VERSION ""

NS_ :

BS_:

BU_: ARM APIM_CDC APIM_CISM APIM ESPM DSP APIM_CIM FCIMB RACM_RCIM HUD_ADV WCM TRM_ITRM ACM GWM _delete IPC GENERIC TSTR

BO_ 811 APIM_Data: 8 APIM
 SG_ ExtLghtDsply_D_Stat : 7|3@0+ (1,0) [0|7] "SED"  GWM
 SG_ LongTermReset_B_RqMnu : 17|1@0+ (1,0) [0|1] "SED"  GWM
 SG_ SpeedoMajorUnit_D_Confg : 59|2@0+ (1,0) [0|3] "SED"  GWM
 SG_ ScMnSoc_Pc_RqMnu : 55|7@0+ (1,0) [0|125] "percent"  GWM
 SG_ ScEnbl_D_RqMnu : 57|2@0+ (1,0) [0|3] "SED"  GWM
 SG_ OnePdlDrvButtn_B_Stat : 48|1@0+ (1,0) [0|1] "SED"  GWM
 SG_ OnePdlDrvButtn_B_Falt : 16|1@0+ (1,0) [0|1] "SED"  GWM
 SG_ GoTEditMnte_T_RqMnu : 63|4@0+ (1,0) [0|15] "SED"  GWM
 SG_ GoTEditHr_T_RqMnu : 44|5@0+ (1,0) [0|29] "SED"  GWM
 SG_ ExtLghtRight_D_RqMnu : 11|3@0+ (1,0) [0|7] "SED"  GWM
 SG_ AutoLghtOvrrd_B_RqDrv : 8|1@0+ (1,0) [0|1] "SED"  GWM
 SG_ TrnkFrontRleas_No_RqMnu : 20|3@0+ (1,0) [0|7] "unitless"  GWM
 SG_ BecRleas_No_RqMnu : 23|3@0+ (1,0) [0|7] "unitless"  GWM
 SG_ ExtLghtRear_D_RqMnu : 14|3@0+ (1,0) [0|7] "SED"  GWM
 SG_ ExtLghtLeft_D_RqMnu : 1|3@0+ (1,0) [0|7] "SED"  GWM
 SG_ ExtLghtFront_D_RqMnu : 4|3@0+ (1,0) [0|7] "SED"  GWM
 SG_ DistToStopover_L_Actl : 31|16@0+ (0.1,0) [0|6553.4] "kilometer"  IPC,GWM
 SG_ StopoverType_D_Stat : 47|3@0+ (1,0) [0|7] "SED"  IPC,GWM

BO_ 543 TelTaleData: 8 IPC
 SG_ TeltalWarnData_No_Actl : 7|64@0+ (1,0) [0|1.84467E+019] "unitless"  APIM,APIM_CISM,GWM

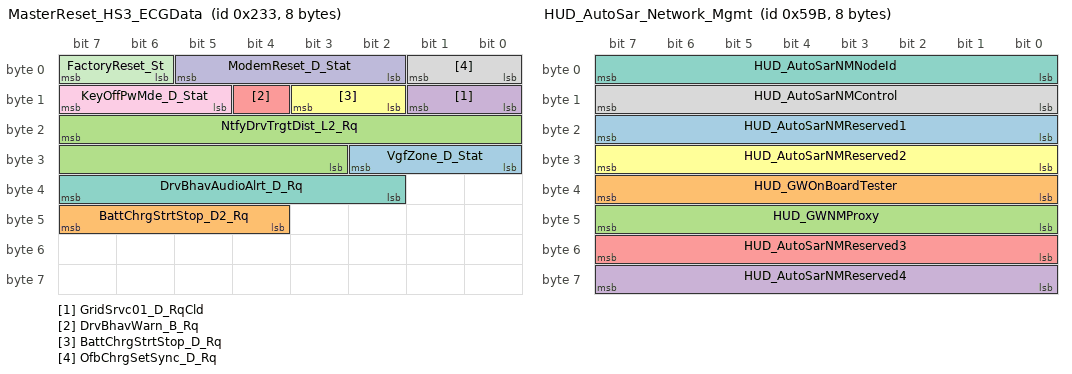
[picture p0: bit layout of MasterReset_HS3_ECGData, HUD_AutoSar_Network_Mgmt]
BO_ 563 MasterReset_HS3_ECGData: 8 GWM
 SG_ VgfZone_D_Stat : 26|3@0+ (1,0) [0|7] "SED"  IPC
 SG_ BattChrgStrtStop_D2_Rq : 47|4@0+ (1,0) [0|15] "SED" Vector__XXX
 SG_ NtfyDrvTrgtDist_L2_Rq : 23|13@0+ (0.1,0) [0|818.9] "Km" Vector__XXX
 SG_ GridSrvc01_D_RqCld : 9|2@0+ (1,0) [0|3] "SED"  APIM_CDC,APIM,APIM_CISM,APIM_CIM
 SG_ DrvBhavWarn_B_Rq : 12|1@0+ (1,0) [0|1] "SED"  APIM_CDC,APIM_CIM,IPC
 SG_ BattChrgStrtStop_D_Rq : 11|2@0+ (1,0) [0|3] "SED"  GENERIC
 SG_ DrvBhavAudioAlrt_D_Rq : 39|6@0+ (1,0) [0|63] "SED"  APIM_CDC,APIM,APIM_CISM,APIM_CIM
 SG_ OfbChrgSetSync_D_Rq : 1|2@0+ (1,0) [0|3] "SED"  APIM_CDC,APIM,APIM_CISM,APIM_CIM
 SG_ KeyOffPwMde_D_Stat : 15|3@0+ (1,0) [0|7] "SED"  APIM_CDC,APIM,APIM_CISM,APIM_CIM
 SG_ ModemReset_D_Stat : 5|4@0+ (1,0) [0|15] "SED"  APIM_CDC,APIM,APIM_CISM,APIM_CIM,ACM
 SG_ FactoryReset_St : 7|2@0+ (1,0) [0|3] "SED"  APIM_CDC,APIM,APIM_CISM,APIM_CIM,ACM

BO_ 587 PHONE_RDISP2_WORD_Rx: 8 HUD_ADV
 SG_ PHONE_RDISP2_WORD_Rx : 7|64@0+ (1,0) [0|1.84467440737096E+019] "unitless"  APIM_CDC,APIM,APIM_CISM,APIM_CIM,ACM

BO_ 579 PHONE_RDISP2_WORD_Tx: 8 ACM
 SG_ PHONE_RDISP2_WORD_Tx : 7|64@0+ (1,0) [0|1.84467440737096E+019] "unitless"  HUD_ADV

BO_ 585 NAV_RDISP2_WORD_Rx: 8 HUD_ADV
 SG_ NAV_RDISP2_WORD_Rx : 7|64@0+ (1,0) [0|1.84467440737096E+019] "unitless"  APIM_CDC,APIM,APIM_CISM,APIM_CIM

BO_ 586 CONMP_RDISP2_WORD_Rx: 8 HUD_ADV
 SG_ CONMP_RDISP2_WORD_Rx : 7|64@0+ (1,0) [0|1.84467440737096E+019] "unitless"  APIM_CDC,APIM,APIM_CISM,APIM_CIM

BO_ 578 CONMP_RDISP2_WORD_Tx: 8 APIM
 SG_ CONMP_RDISP2_WORD_Tx : 7|64@0+ (1,0) [0|1.84467440737096E+019] "unitless"  HUD_ADV

BO_ 577 NAV_RDISP2_WORD_Tx: 8 APIM
 SG_ NAV_RDISP2_WORD_Tx : 7|64@0+ (1,0) [0|1.84467440737096E+019] "unitless"  HUD_ADV

BO_ 978 ConvertibleTop_Slave_HS3: 8 GWM
 SG_ CnvtTopTWarn_B_Falt : 25|1@0+ (1,0) [0|1] "SED" Vector__XXX
 SG_ CnvtTopTOvr_B_Falt : 26|1@0+ (1,0) [0|1] "SED" Vector__XXX
 SG_ CnvtTopTDir_B_Falt : 27|1@0+ (1,0) [0|1] "SED" Vector__XXX
 SG_ CnvtTopStall_B_Falt : 28|1@0+ (1,0) [0|1] "SED" Vector__XXX
 SG_ CnvtTopSns_B_Falt : 29|1@0+ (1,0) [0|1] "SED" Vector__XXX
 SG_ CnvtTopRvrse_B_Stat : 30|1@0+ (1,0) [0|1] "SED" Vector__XXX
 SG_ CnvtTopRngOpen_B_Stat : 31|1@0+ (1,0) [0|1] "SED" Vector__XXX
 SG_ CnvtTopRngClose_B_Stat : 16|1@0+ (1,0) [0|1] "SED" Vector__XXX
 SG_ CnvtTopRestrc_B_Falt : 17|1@0+ (1,0) [0|1] "SED" Vector__XXX
 SG_ CnvtTopRdy_B_Stat : 18|1@0+ (1,0) [0|1] "SED" Vector__XXX
 SG_ CnvtTopPosSet_B_Stat : 19|1@0+ (1,0) [0|1] "SED" Vector__XXX
 SG_ CnvtTopPos_No_Actl : 39|16@0+ (1,0) [0|65535] "unitless" Vector__XXX
 SG_ CnvtTopPos_D_Stat : 23|4@0+ (1,0) [0|15] "SED"  APIM_CDC,APIM,APIM_CIM,APIM_CISM
 SG_ CnvtTopPos_B_Falt : 8|1@0+ (1,0) [0|1] "SED" Vector__XXX
 SG_ CnvtTopOut_B_Falt : 9|1@0+ (1,0) [0|1] "SED" Vector__XXX
 SG_ CnvtTopOpen_D_Stat : 11|2@0+ (1,0) [0|3] "SED" Vector__XXX
 SG_ CnvtTopOpen_B_Stat : 12|1@0+ (1,0) [0|1] "SED" Vector__XXX
 SG_ CnvtTopNom_B_Stat : 13|1@0+ (1,0) [0|1] "SED" Vector__XXX
 SG_ CnvtTopDir_B_Falt : 0|1@0+ (1,0) [0|1] "SED" Vector__XXX
 SG_ CnvtTopComplt_No_Cnt : 15|2@0+ (1,0) [0|3] "unitless" Vector__XXX
 SG_ CnvtTopComplt_D_Stat : 3|3@0+ (1,0) [0|7] "SED" Vector__XXX
 SG_ CnvtTopCnfm_B_Stat : 4|1@0+ (1,0) [0|1] "SED" Vector__XXX
 SG_ CnvtTopClose_D_Stat : 6|2@0+ (1,0) [0|3] "SED" Vector__XXX
 SG_ CnvtTopActv_B_Stat : 7|1@0+ (1,0) [0|1] "SED" Vector__XXX
 SG_ TonneuCapMde_D_Stat : 55|2@0+ (1,0) [0|3] "SED" Vector__XXX

BO_ 717 DSPAMP_RDISP_WORD_Rx: 8 APIM
 SG_ DSPAMP_RDISP_WORD_Rx : 7|64@0+ (1,0) [0|1.84467440737096E+019] "unitless"  DSP

BO_ 719 MyKeySrvr_Clnt_Word_Rx: 8 APIM
 SG_ MyKeySrvr_Clnt_Word_Rx : 7|64@0+ (1,0) [0|1.84467440737096E+019] "unitless"  IPC

BO_ 589 TRAFFIC_RDISP_WORD_Rx: 8 APIM
 SG_ TRAFFIC_RDISP_WORD_Rx : 7|64@0+ (1,0) [0|1.84467440737096E+019] "unitless"  GWM

BO_ 1146 TrailerInfo_ITRM: 8 TRM_ITRM
 SG_ TrlrAidSwtch_D_RqDrv : 35|2@0+ (1,0) [0|3] "SED"  GWM
 SG_ TrlrAidCtl_U_RqDrv : 31|12@0+ (0.00125,0) [0|5.11625] "volt"  GWM

BO_ 737 APIM_ECG_Word_Tx: 8 APIM
 SG_ APIM_ECG_Word_Tx : 7|64@0+ (1,0) [0|1.84467440737096E+019] "unitless"  IPC,GWM

BO_ 745 ECG_APIM_Word_Tx: 8 GWM
 SG_ ECG_APIM_Word_Tx : 7|64@0+ (1,0) [0|1.84467440737096E+019] "unitless"  APIM_CDC,APIM,APIM_CIM,APIM_CISM

BO_ 1195 TCU_RDISP2_WORD_Rx: 8 HUD_ADV
 SG_ TCU_RDISP2_WORD_Rx : 7|64@0+ (1,0) [0|1.84467440737096E+019] "unitless"  GWM

BO_ 1185 TCU_MC_WORD_Rx: 8 IPC
 SG_ TCU_MC_WORD_Rx : 7|64@0+ (1,0) [0|1.84467440737096E+019] "unitless"  GWM

BO_ 1435 HUD_AutoSar_Network_Mgmt: 8 HUD_ADV
 SG_ HUD_AutoSarNMReserved1 : 23|8@0+ (1,0) [0|255] "unitless"  GENERIC,IPC
 SG_ HUD_GWOnBoardTester : 39|8@0+ (1,0) [0|255] "unitless"  GENERIC,IPC,GWM
 SG_ HUD_GWNMProxy : 47|8@0+ (1,0) [0|255] "unitless"  GENERIC,IPC,GWM
 SG_ HUD_AutoSarNMReserved4 : 63|8@0+ (1,0) [0|255] "unitless"  GENERIC,IPC,GWM
 SG_ HUD_AutoSarNMReserved3 : 55|8@0+ (1,0) [0|255] "unitless"  GENERIC,IPC,GWM
 SG_ HUD_AutoSarNMReserved2 : 31|8@0+ (1,0) [0|255] "unitless"  GENERIC,IPC,GWM
 SG_ HUD_AutoSarNMNodeId : 7|8@0+ (1,0) [0|255] "unitless"  GENERIC,IPC,GWM
 SG_ HUD_AutoSarNMControl : 15|8@0+ (1,0) [0|255] "unitless"  GENERIC,IPC,GWM

BO_ 1109 eCall_Info: 8 APIM
 SG_ eCallConfirmation : 7|3@0+ (1,0) [0|7] "SED"  IPC,GWM

BO_ 1945 TesterPhysicalResTRM_ITRM: 8 TRM_ITRM
 SG_ TesterPhysicalResTRM_ITRM : 7|64@0+ (1,0) [0|1.84467E+019] "unitless"  TSTR

BO_ 1937 TesterPhysicalReqTRM_ITRM: 8 TSTR
 SG_ TesterPhysicalReqTRM_ITRM : 7|64@0+ (1,0) [0|1.84467E+019] "unitless"  TRM_ITRM

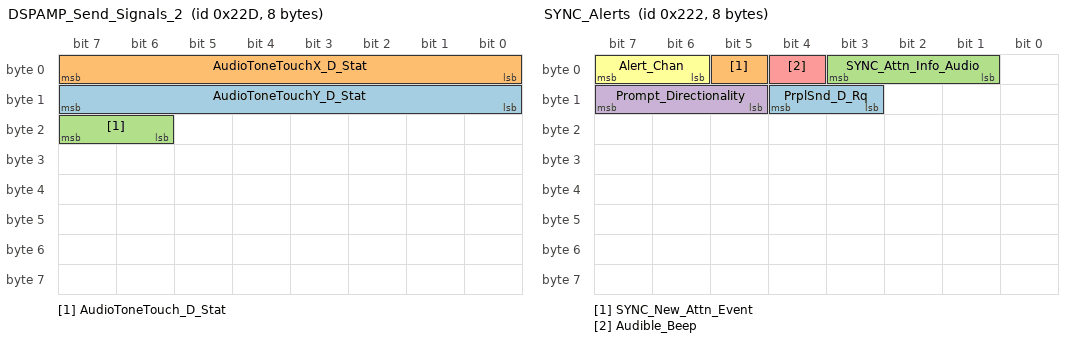
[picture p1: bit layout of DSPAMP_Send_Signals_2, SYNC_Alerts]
BO_ 557 DSPAMP_Send_Signals_2: 8 DSP
 SG_ AudioToneTouchY_D_Stat : 15|8@0+ (1,0) [0|255] "SED"  APIM_CDC,APIM,APIM_CISM,APIM_CIM
 SG_ AudioToneTouchX_D_Stat : 7|8@0+ (1,0) [0|255] "SED"  APIM_CDC,APIM,APIM_CISM,APIM_CIM
 SG_ AudioToneTouch_D_Stat : 23|2@0+ (1,0) [0|3] "SED"  APIM_CDC,APIM,APIM_CISM,APIM_CIM

BO_ 718 BEZEL_RDISP_WORD_Rx: 8 APIM
 SG_ BEZEL_RDISP_WORD_Rx : 7|64@0+ (1,0) [0|1.84467440737096E+019] "unitless"  GWM

BO_ 140 CruiseCtrl_StrgData2: 8 IPC
 SG_ DcacPwResetBttn_D_Stat : 36|2@0+ (1,0) [0|3] "SED"  GWM
 SG_ CcAslButtnIndxIncPress2 : 18|1@0+ (1,0) [0|1] "SED"  GWM
 SG_ SteWhlSwtchMde_D_Stat : 23|2@0+ (1,0) [0|3] "SED"  GWM
 SG_ CcAslButtnOffCnclPress2 : 17|1@0+ (1,0) [0|1] "SED"  GWM
 SG_ CcAslButtnIndxDecPress2 : 19|1@0+ (1,0) [0|1] "SED"  GWM
 SG_ CcAslButtnCnclResPress2 : 21|1@0+ (1,0) [0|1] "SED"  GWM
 SG_ CcAslButtnResIncPress3 : 29|1@0+ (1,0) [0|1] "SED"  GWM
 SG_ CcButtnOnPress3 : 37|1@0+ (1,0) [0|1] "SED"  GWM
 SG_ CcButtnOnOffPress3 : 38|1@0+ (1,0) [0|1] "SED"  GWM
 SG_ CcButtnOnOffCnclPress3 : 39|1@0+ (1,0) [0|1] "SED"  GWM
 SG_ CcButtnOffPress3 : 24|1@0+ (1,0) [0|1] "SED"  GWM
 SG_ CcAsllButtnResPress3 : 25|1@0+ (1,0) [0|1] "SED"  GWM
 SG_ CcAslButtnSetPress3 : 26|1@0+ (1,0) [0|1] "SED"  GWM
 SG_ CcAslButtnSetIncPress3 : 27|1@0+ (1,0) [0|1] "SED"  GWM
 SG_ CcAslButtnSetDecPress3 : 28|1@0+ (1,0) [0|1] "SED"  GWM
 SG_ CcAslButtnResDecPress3 : 30|1@0+ (1,0) [0|1] "SED"  GWM
 SG_ CcAslButtnOnPress3 : 31|1@0+ (1,0) [0|1] "SED"  GWM
 SG_ CcAslButtnOnOffCncl3 : 16|1@0+ (1,0) [0|1] "SED"  GWM
 SG_ CcAslButtnDeny_B_Actl3 : 20|1@0+ (1,0) [0|1] "SED"  GWM
 SG_ CcAslButtnCnclPress3 : 8|1@0+ (1,0) [0|1] "SED"  GWM
 SG_ AslButtnOnOffPress3 : 9|1@0+ (1,0) [0|1] "SED"  GWM
 SG_ AslButtnOnOffCnclPress2 : 10|1@0+ (1,0) [0|1] "SED"  GWM

BO_ 546 SYNC_Alerts: 8 APIM
 SG_ PrplSnd_D_Rq : 12|2@0+ (1,0) [0|3] "SED"  ACM
 SG_ SYNC_New_Attn_Event : 5|1@0+ (1,0) [0|1] "SED"  DSP,ACM
 SG_ SYNC_Attn_Info_Audio : 3|3@0+ (1,0) [0|7] "SED"  DSP,ACM
 SG_ Prompt_Directionality : 15|3@0+ (1,0) [0|7] "SED"  DSP,ACM
 SG_ Audible_Beep : 4|1@0+ (1,0) [0|1] "SED"  DSP,ACM
 SG_ Alert_Chan : 7|2@0+ (1,0) [0|3] "SED"  WCM,RACM_RCIM,DSP,ACM

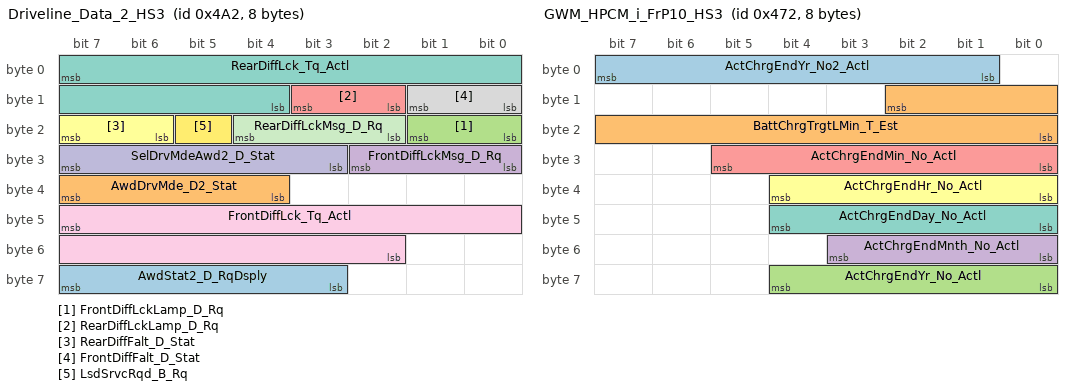
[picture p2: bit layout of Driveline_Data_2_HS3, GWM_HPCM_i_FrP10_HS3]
BO_ 1186 Driveline_Data_2_HS3: 8 GWM
 SG_ AwdStat2_D_RqDsply : 63|5@0+ (1,0) [0|31] "SED"  APIM_CDC,APIM_CIM,IPC
 SG_ AwdDrvMde_D2_Stat : 39|4@0+ (1,0) [0|15] "SED"  APIM_CDC,APIM_CIM,IPC
 SG_ FrontDiffLckLamp_D_Rq : 17|2@0+ (1,0) [0|3] "SED"  APIM_CDC,HUD_ADV,APIM,APIM_CIM,APIM_CISM,IPC
 SG_ FrontDiffLckMsg_D_Rq : 26|3@0+ (1,0) [0|7] "SED"  APIM_CDC,APIM_CIM,IPC
 SG_ RearDiffLckLamp_D_Rq : 11|2@0+ (1,0) [0|3] "SED"  APIM_CDC,HUD_ADV,APIM,APIM_CISM,APIM_CIM,ACM,IPC
 SG_ RearDiffFalt_D_Stat : 23|2@0+ (1,0) [0|3] "SED" Vector__XXX
 SG_ RearDiffLck_Tq_Actl : 7|12@0+ (1,0) [0|4093] "Nm" Vector__XXX
 SG_ FrontDiffFalt_D_Stat : 9|2@0+ (1,0) [0|3] "SED"  GENERIC
 SG_ FrontDiffLck_Tq_Actl : 47|14@0+ (1,0) [0|16381] "Nm"  GENERIC
 SG_ SelDrvMdeAwd2_D_Stat : 31|5@0+ (1,0) [0|31] "SED"  GENERIC
 SG_ RearDiffLckMsg_D_Rq : 20|3@0+ (1,0) [0|7] "SED"  APIM_CDC,APIM_CIM,IPC
 SG_ LsdSrvcRqd_B_Rq : 21|1@0+ (1,0) [0|1] "SED"  APIM_CDC,APIM_CISM,APIM_CIM,IPC

BO_ 1138 GWM_HPCM_i_FrP10_HS3: 8 GWM
 SG_ ActChrgEndYr_No2_Actl : 7|7@0+ (1,2017) [2017|2144] "year"  APIM_CDC,APIM,APIM_CIM,APIM_CISM,IPC
 SG_ BattChrgTrgtLMin_T_Est : 10|11@0+ (1,0) [0|2045] "minute"  APIM_CDC,APIM,APIM_CIM,APIM_CISM
 SG_ ActChrgEndYr_No_Actl : 60|5@0+ (1,2010) [2010|2040] "year"  APIM_CDC,APIM,APIM_CIM,APIM_CISM,IPC
 SG_ ActChrgEndMnth_No_Actl : 51|4@0+ (1,1) [1|15] "month"  APIM_CDC,APIM,APIM_CIM,APIM_CISM,IPC
 SG_ ActChrgEndMin_No_Actl : 29|6@0+ (1,0) [0|61] "minute"  APIM_CDC,APIM,APIM_CIM,APIM_CISM,IPC
 SG_ ActChrgEndHr_No_Actl : 36|5@0+ (1,0) [0|29] "hour"  APIM_CDC,APIM,APIM_CIM,APIM_CISM,IPC
 SG_ ActChrgEndDay_No_Actl : 44|5@0+ (1,1) [1|31] "day"  APIM_CDC,APIM,APIM_CIM,APIM_CISM,IPC

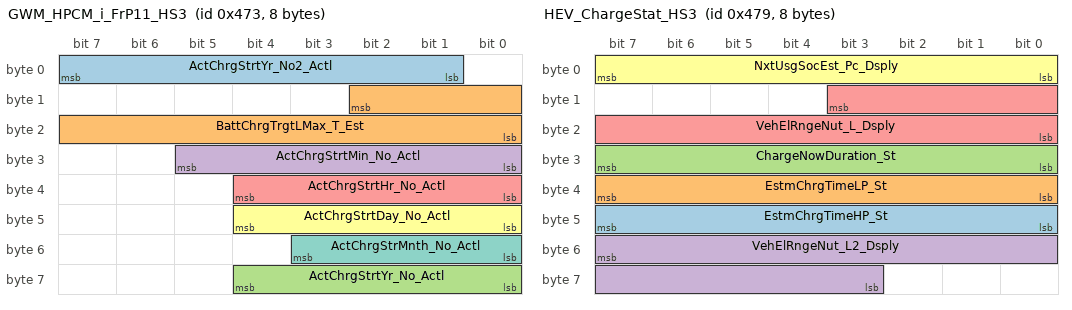
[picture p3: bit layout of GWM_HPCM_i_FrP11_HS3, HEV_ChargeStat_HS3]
BO_ 1139 GWM_HPCM_i_FrP11_HS3: 8 GWM
 SG_ ActChrgStrtYr_No2_Actl : 7|7@0+ (1,2017) [2017|2144] "year"  APIM_CDC,APIM,APIM_CIM,APIM_CISM,IPC
 SG_ BattChrgTrgtLMax_T_Est : 10|11@0+ (1,0) [0|2045] "minute"  APIM_CDC,APIM,APIM_CIM,APIM_CISM
 SG_ ActChrgStrtYr_No_Actl : 60|5@0+ (1,2010) [2010|2040] "year"  APIM_CDC,APIM,APIM_CIM,APIM_CISM,IPC
 SG_ ActChrgStrtMin_No_Actl : 29|6@0+ (1,0) [0|61] "minute"  APIM_CDC,APIM,APIM_CIM,APIM_CISM,IPC
 SG_ ActChrgStrtHr_No_Actl : 36|5@0+ (1,0) [0|29] "hour"  APIM_CDC,APIM,APIM_CIM,APIM_CISM,IPC,HUD_ADV
 SG_ ActChrgStrtDay_No_Actl : 44|5@0+ (1,1) [1|31] "day"  APIM_CDC,APIM,APIM_CIM,APIM_CISM,IPC
 SG_ ActChrgStrMnth_No_Actl : 51|4@0+ (1,1) [1|15] "month"  APIM_CDC,APIM,APIM_CIM,APIM_CISM,IPC

BO_ 1145 HEV_ChargeStat_HS3: 8 GWM
 SG_ EstmChrgTimeHP_St : 47|8@0+ (0.1,0) [0|25.4] "hour"  APIM_CDC,APIM,APIM_CISM,APIM_CIM,IPC
 SG_ EstmChrgTimeLP_St : 39|8@0+ (0.1,0) [0|25.4] "hour"  APIM_CDC,APIM,APIM_CISM,APIM_CIM,IPC
 SG_ ChargeNowDuration_St : 31|8@0+ (0.1,0) [0|25.4] "hour"  APIM_CDC,APIM,APIM_CISM,APIM_CIM,IPC
 SG_ VehElRngeNut_L2_Dsply : 55|13@0+ (0.1,0) [0|818.9] "km"  APIM_CDC,APIM,APIM_CIM,APIM_CISM
 SG_ VehElRngeNut_L_Dsply : 11|12@0+ (0.1,0) [0|409.3] "km"  APIM_CDC,APIM,APIM_CIM,APIM_CISM,IPC
 SG_ NxtUsgSocEst_Pc_Dsply : 7|8@0+ (0.5,0) [0|126.5] "unitless"  APIM_CDC,APIM,APIM_CIM,APIM_CISM

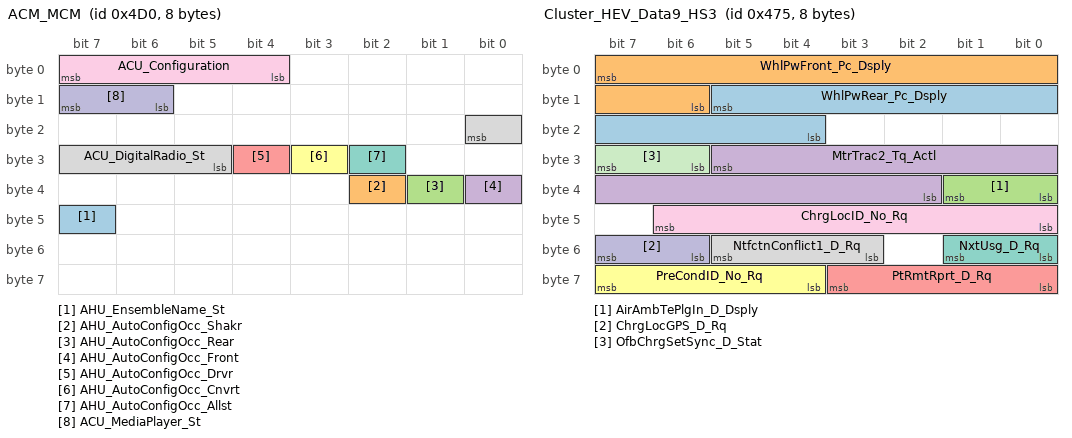
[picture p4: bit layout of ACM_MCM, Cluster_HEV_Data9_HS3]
BO_ 1232 ACM_MCM: 8 APIM_CIM
 SG_ AHU_EnsembleName_St : 47|1@0+ (1,0) [0|1] "SED"  APIM_CDC,APIM
 SG_ AHU_AutoConfigOcc_Shakr : 34|1@0+ (1,0) [0|1] "SED"  APIM_CDC,APIM,GWM
 SG_ AHU_AutoConfigOcc_Rear : 33|1@0+ (1,0) [0|1] "SED"  APIM_CDC,APIM,GWM
 SG_ AHU_AutoConfigOcc_Front : 32|1@0+ (1,0) [0|1] "SED"  APIM_CDC,APIM,GWM
 SG_ AHU_AutoConfigOcc_Drvr : 28|1@0+ (1,0) [0|1] "SED"  APIM_CDC,APIM,GWM
 SG_ AHU_AutoConfigOcc_Cnvrt : 27|1@0+ (1,0) [0|1] "SED"  APIM_CDC,APIM,GWM
 SG_ AHU_AutoConfigOcc_Allst : 26|1@0+ (1,0) [0|1] "SED"  APIM_CDC,APIM,GWM
 SG_ ACU_DigitalRadio_St : 16|4@0+ (1,0) [0|15] "SED"  APIM_CDC,APIM,GWM,IPC
 SG_ ACU_Configuration : 7|4@0+ (1,0) [0|15] "SED"  APIM_CDC,APIM,GWM,IPC
 SG_ ACU_MediaPlayer_St : 15|2@0+ (1,0) [0|3] "SED"  APIM_CDC,APIM,GWM,IPC

BO_ 1141 Cluster_HEV_Data9_HS3: 8 GWM
 SG_ WhlPwRear_Pc_Dsply : 13|10@0+ (0.2,-102.2) [-102.2|102.4] "percent"  APIM_CDC,APIM_CIM,IPC
 SG_ WhlPwFront_Pc_Dsply : 7|10@0+ (0.2,-102.2) [-102.2|102.4] "percent"  APIM_CDC,APIM_CIM,IPC
 SG_ AirAmbTePlgIn_D_Dsply : 33|2@0+ (1,0) [0|3] "SED"  APIM_CDC,APIM_CISM,APIM_CIM,IPC
 SG_ MtrTrac2_Tq_Actl : 29|12@0+ (1,-2047) [-2047|2048] "Nm" Vector__XXX
 SG_ PtRmtRprt_D_Rq : 59|4@0+ (1,0) [0|15] "SED"  IPC
 SG_ PreCondID_No_Rq : 63|4@0+ (1,0) [0|15] "unitless"  IPC
 SG_ NxtUsg_D_Rq : 49|2@0+ (1,0) [0|3] "SED"  IPC
 SG_ NtfctnConflict1_D_Rq : 53|3@0+ (1,0) [0|7] "SED"  APIM_CDC,APIM,APIM_CIM,APIM_CISM
 SG_ ChrgLocID_No_Rq : 46|7@0+ (1,0) [0|127] "unitless"  IPC
 SG_ ChrgLocGPS_D_Rq : 55|2@0+ (1,0) [0|3] "SED"  IPC
 SG_ OfbChrgSetSync_D_Stat : 31|2@0+ (1,0) [0|3] "SED"  APIM_CDC,APIM,APIM_CIM,APIM_CISM

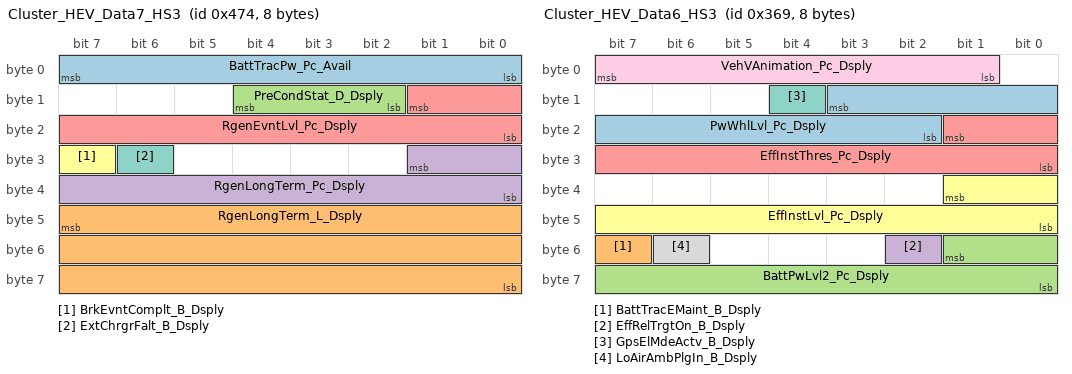
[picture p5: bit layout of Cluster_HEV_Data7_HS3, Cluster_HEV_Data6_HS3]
BO_ 1140 Cluster_HEV_Data7_HS3: 8 GWM
 SG_ BattTracPw_Pc_Avail : 7|8@0+ (0.5,0) [0|126.5] "percent"  APIM_CDC,APIM_CIM,IPC
 SG_ RgenLongTerm_L_Dsply : 47|24@0+ (0.1,0) [0|1677721.3] "km"  APIM_CDC,APIM_CIM,IPC
 SG_ PreCondStat_D_Dsply : 12|3@0+ (1,0) [0|7] "SED"  IPC
 SG_ RgenLongTerm_Pc_Dsply : 25|10@0+ (0.1,0) [0|102.3] "percent"  APIM_CDC,APIM_CIM,IPC
 SG_ RgenEvntLvl_Pc_Dsply : 9|10@0+ (0.1,0) [0|102.1] "percent"  APIM_CDC,APIM_CIM,IPC
 SG_ BrkEvntComplt_B_Dsply : 31|1@0+ (1,0) [0|1] "SED"  APIM_CDC,APIM_CIM,IPC
 SG_ ExtChrgrFalt_B_Dsply : 30|1@0+ (1,0) [0|1] "SED"  APIM_CDC,APIM_CIM,IPC

BO_ 873 Cluster_HEV_Data6_HS3: 8 GWM
 SG_ PwWhlLvl_Pc_Dsply : 11|10@0+ (0.2,-102.2) [-102.2|102.4] "percent"  APIM_CDC,APIM_CISM,APIM_CIM,IPC
 SG_ BattTracEMaint_B_Dsply : 55|1@0+ (1,0) [0|1] "SED"  APIM_CDC,APIM_CISM,APIM_CIM,IPC
 SG_ BattPwLvl2_Pc_Dsply : 49|10@0+ (0.2,-102.2) [-102.2|102.4] "percent"  APIM_CDC,APIM,APIM_CISM,APIM_CIM,IPC
 SG_ EffRelTrgtOn_B_Dsply : 50|1@0+ (1,0) [0|1] "SED"  APIM_CDC,APIM_CISM,APIM_CIM,IPC
 SG_ EffInstThres_Pc_Dsply : 17|10@0+ (0.1,0) [0|102.3] "percent"  APIM_CDC,APIM_CISM,APIM_CIM,IPC
 SG_ EffInstLvl_Pc_Dsply : 33|10@0+ (0.1,0) [0|102.3] "percent"  APIM_CDC,APIM_CISM,APIM_CIM,IPC
 SG_ GpsElMdeActv_B_Dsply : 12|1@0+ (1,0) [0|1] "SED"  APIM_CDC,APIM,APIM_CIM,APIM_CISM,IPC
 SG_ LoAirAmbPlgIn_B_Dsply : 54|1@0+ (1,0) [0|1] "SED"  APIM_CDC,APIM_CISM,APIM_CIM,IPC
 SG_ VehVAnimation_Pc_Dsply : 7|7@0+ (1,0) [0|127] "percent"  APIM_CDC,APIM_CISM,APIM_CIM,IPC

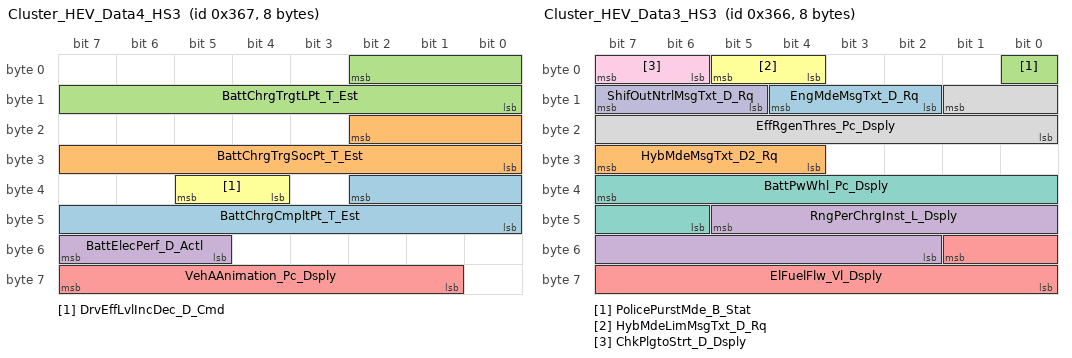
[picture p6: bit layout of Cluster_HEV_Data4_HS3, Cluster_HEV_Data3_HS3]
BO_ 871 Cluster_HEV_Data4_HS3: 8 GWM
 SG_ BattChrgCmpltPt_T_Est : 34|11@0+ (1,0) [0|2045] "minute"  IPC
 SG_ BattChrgTrgSocPt_T_Est : 18|11@0+ (1,0) [0|2045] "minute"  IPC
 SG_ BattChrgTrgtLPt_T_Est : 2|11@0+ (1,0) [0|2045] "minute"  IPC
 SG_ BattElecPerf_D_Actl : 55|3@0+ (1,0) [0|7] "SED"  APIM_CDC,APIM_CISM,APIM_CIM,IPC
 SG_ VehAAnimation_Pc_Dsply : 63|7@0+ (1,0) [0|127] "percent"  APIM_CDC,APIM_CISM,APIM_CIM,IPC
 SG_ DrvEffLvlIncDec_D_Cmd : 37|2@0+ (1,0) [0|3] "SED"  APIM_CDC,APIM_CISM,APIM_CIM,IPC

BO_ 870 Cluster_HEV_Data3_HS3: 8 GWM
 SG_ EngMdeMsgTxt_D_Rq : 12|3@0+ (1,0) [0|7] "SED"  APIM_CDC,IPC,APIM_CIM
 SG_ HybMdeMsgTxt_D2_Rq : 31|4@0+ (1,0) [0|15] "SED"  APIM_CDC,IPC,APIM_CIM
 SG_ PolicePurstMde_B_Stat : 0|1@0+ (1,0) [0|1] "SED"  APIM_CDC,IPC,APIM_CIM
 SG_ RngPerChrgInst_L_Dsply : 45|12@0+ (0.1,0) [0|409.3] "km"  APIM_CDC,IPC,APIM_CIM
 SG_ ElFuelFlw_Vl_Dsply : 49|10@0+ (25,0) [0|25575] "micro-litre"  APIM_CDC,APIM_CISM,APIM_CIM,IPC
 SG_ HybMdeLimMsgTxt_D_Rq : 5|2@0+ (1,0) [0|3] "SED"  APIM_CDC,APIM_CISM,APIM_CIM,IPC
 SG_ BattPwWhl_Pc_Dsply : 39|10@0+ (0.1,0) [0|102.3] "percent"  APIM_CDC,APIM_CISM,APIM_CIM,IPC
 SG_ EffRgenThres_Pc_Dsply : 9|10@0+ (0.1,-102.3) [-102.3|1023] "percent"  APIM_CDC,APIM_CIM,IPC
 SG_ ChkPlgtoStrt_D_Dsply : 7|2@0+ (1,0) [0|3] "SED"  APIM_CDC,IPC,APIM_CIM
 SG_ ShifOutNtrlMsgTxt_D_Rq : 15|3@0+ (1,0) [0|7] "SED"  APIM_CDC,APIM_CISM,APIM_CIM,IPC

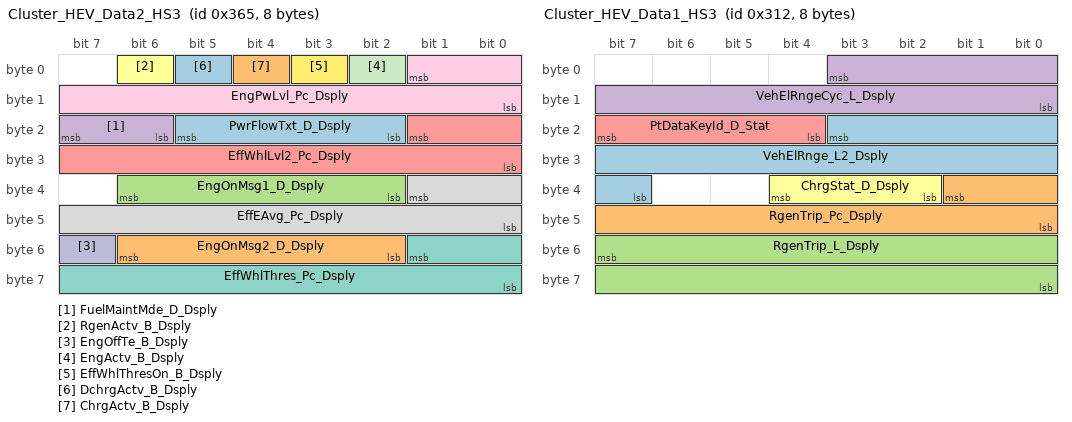
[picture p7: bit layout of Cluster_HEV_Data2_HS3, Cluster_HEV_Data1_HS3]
BO_ 869 Cluster_HEV_Data2_HS3: 8 GWM
 SG_ PwrFlowTxt_D_Dsply : 21|4@0+ (1,0) [0|15] "SED"  APIM_CDC,APIM,APIM_CIM,APIM_CISM,IPC
 SG_ EngOnMsg2_D_Dsply : 54|5@0+ (1,0) [0|31] "SED"  APIM_CDC,APIM,APIM_CISM,APIM_CIM,IPC
 SG_ EngOnMsg1_D_Dsply : 38|5@0+ (1,0) [0|31] "SED"  APIM_CDC,APIM,APIM_CISM,APIM_CIM,IPC
 SG_ FuelMaintMde_D_Dsply : 23|2@0+ (1,0) [0|3] "SED"  APIM_CDC,APIM_CIM,IPC
 SG_ EffWhlLvl2_Pc_Dsply : 17|10@0+ (0.2,-102.2) [-102.2|102.4] "percent"  APIM_CDC,APIM,APIM_CISM,APIM_CIM,ACM,IPC
 SG_ RgenActv_B_Dsply : 6|1@0+ (1,0) [0|1] "SED"  APIM_CDC,APIM_CISM,APIM_CIM,IPC
 SG_ EffWhlThres_Pc_Dsply : 49|10@0+ (0.1,0) [0|102.3] "percent"  APIM_CDC,APIM_CIM,IPC
 SG_ EffEAvg_Pc_Dsply : 33|10@0+ (0.1,0) [0|102.3] "percent"  APIM_CDC,APIM,APIM_CIM,APIM_CISM,IPC
 SG_ EngPwLvl_Pc_Dsply : 1|10@0+ (0.1,0) [0|102.3] "percent"  APIM_CDC,APIM,APIM_CIM,APIM_CISM,IPC
 SG_ EngOffTe_B_Dsply : 55|1@0+ (1,0) [0|1] "SED"  APIM_CDC,APIM_CISM,APIM_CIM,IPC
 SG_ EngActv_B_Dsply : 2|1@0+ (1,0) [0|1] "SED"  APIM_CDC,APIM,APIM_CISM,APIM_CIM,IPC
 SG_ EffWhlThresOn_B_Dsply : 3|1@0+ (1,0) [0|1] "SED"  APIM_CDC,APIM_CISM,APIM_CIM,IPC
 SG_ DchrgActv_B_Dsply : 5|1@0+ (1,0) [0|1] "SED"  APIM_CDC,APIM_CISM,APIM_CIM,IPC
 SG_ ChrgActv_B_Dsply : 4|1@0+ (1,0) [0|1] "SED"  APIM_CDC,APIM_CISM,APIM_CIM,IPC

BO_ 786 Cluster_HEV_Data1_HS3: 8 GWM
 SG_ VehElRnge_L2_Dsply : 19|13@0+ (0.1,0) [0|818.9] "kilometer"  APIM_CDC,APIM,APIM_CIM,APIM_CISM,IPC
 SG_ RgenTrip_Pc_Dsply : 33|10@0+ (0.1,0) [0|102.3] "percent"  APIM_CDC,APIM_CIM,IPC
 SG_ RgenTrip_L_Dsply : 55|16@0+ (0.1,0) [0|6553.3] "kilometer"  APIM_CDC,APIM_CIM,IPC
 SG_ VehElRngeCyc_L_Dsply : 3|12@0+ (0.1,0) [0|409.3] "km"  APIM_CDC,APIM,APIM_CIM,APIM_CISM
 SG_ PtDataKeyId_D_Stat : 23|4@0+ (1,0) [0|15] "SED" Vector__XXX
 SG_ ChrgStat_D_Dsply : 36|3@0+ (1,0) [0|7] "SED"  APIM_CDC,APIM,APIM_CIM,APIM_CISM,IPC

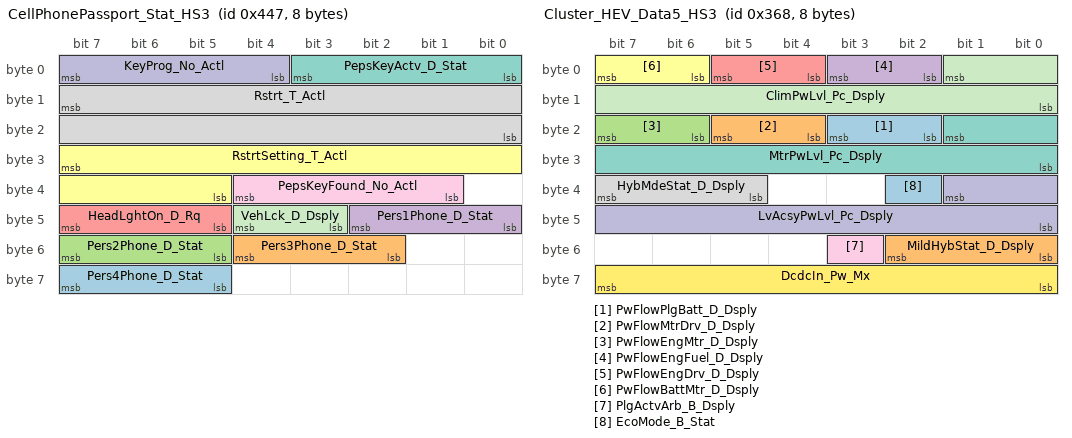
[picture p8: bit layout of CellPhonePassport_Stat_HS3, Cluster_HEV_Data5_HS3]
BO_ 1095 CellPhonePassport_Stat_HS3: 8 GWM
 SG_ Pers4Phone_D_Stat : 63|3@0+ (1,0) [0|7] "SED"  APIM_CDC,APIM,APIM_CIM,APIM_CISM
 SG_ Pers3Phone_D_Stat : 52|3@0+ (1,0) [0|7] "SED"  APIM_CDC,APIM,APIM_CIM,APIM_CISM
 SG_ Pers2Phone_D_Stat : 55|3@0+ (1,0) [0|7] "SED"  APIM_CDC,APIM,APIM_CIM,APIM_CISM
 SG_ Pers1Phone_D_Stat : 42|3@0+ (1,0) [0|7] "SED"  APIM_CDC,APIM,APIM_CIM,APIM_CISM
 SG_ HeadLghtOn_D_Rq : 47|3@0+ (1,0) [0|7] "SED"  GENERIC
 SG_ RstrtSetting_T_Actl : 31|11@0+ (1,0) [0|2047] "second" Vector__XXX
 SG_ PepsKeyActv_D_Stat : 3|4@0+ (1,0) [0|15] "SED" Vector__XXX
 SG_ Rstrt_T_Actl : 15|16@0+ (1,0) [0|65535] "seconds" Vector__XXX
 SG_ PepsKeyFound_No_Actl : 36|4@0+ (1,0) [0|15] "unitless" Vector__XXX
 SG_ KeyProg_No_Actl : 7|4@0+ (1,0) [0|15] "unitless" Vector__XXX
 SG_ VehLck_D_Dsply : 44|2@0+ (1,0) [0|3] "SED"  GENERIC

BO_ 684 MC_RDISP_WORD_Rx: 8 APIM
 SG_ MC_RDISP_WORD_Rx : 7|64@0+ (1,0) [0|1.84467440737096E+019] "unitless"  IPC

BO_ 872 Cluster_HEV_Data5_HS3: 8 GWM
 SG_ PwFlowPlgBatt_D_Dsply : 19|2@0+ (1,0) [0|3] "SED"  APIM_CDC,APIM,APIM_CIM,APIM_CISM,IPC
 SG_ PwFlowMtrDrv_D_Dsply : 21|2@0+ (1,0) [0|3] "SED"  APIM_CDC,APIM,APIM_CIM,APIM_CISM,IPC
 SG_ PwFlowEngMtr_D_Dsply : 23|2@0+ (1,0) [0|3] "SED"  APIM_CDC,APIM,APIM_CIM,APIM_CISM,IPC
 SG_ PwFlowEngFuel_D_Dsply : 3|2@0+ (1,0) [0|3] "SED"  APIM_CDC,APIM,APIM_CIM,APIM_CISM,IPC
 SG_ PwFlowEngDrv_D_Dsply : 5|2@0+ (1,0) [0|3] "SED"  APIM_CDC,APIM,APIM_CIM,APIM_CISM,IPC
 SG_ PwFlowBattMtr_D_Dsply : 7|2@0+ (1,0) [0|3] "SED"  APIM_CDC,APIM,APIM_CIM,APIM_CISM,IPC
 SG_ MtrPwLvl_Pc_Dsply : 17|10@0+ (0.2,-102.2) [-102.2|102.4] "percent"  APIM_CDC,APIM,APIM_CIM,APIM_CISM,IPC
 SG_ HybMdeStat_D_Dsply : 39|3@0+ (1,0) [0|7] "SED"  APIM_CDC,APIM,APIM_CISM,APIM_CIM,HUD_ADV,IPC
 SG_ PlgActvArb_B_Dsply : 51|1@0+ (1,0) [0|1] "SED"  APIM_CDC,APIM,APIM_CISM,APIM_CIM,IPC
 SG_ LvAcsyPwLvl_Pc_Dsply : 33|10@0+ (0.1,0) [0|102.3] "percent"  APIM_CDC,APIM,APIM_CIM,APIM_CISM,IPC
 SG_ ClimPwLvl_Pc_Dsply : 1|10@0+ (0.1,0) [0|102.3] "percent"  APIM_CDC,APIM,APIM_CIM,APIM_CISM,IPC
 SG_ DcdcIn_Pw_Mx : 63|8@0+ (20,1000) [1000|6100] "watts" Vector__XXX
 SG_ EcoMode_B_Stat : 34|1@0+ (1,0) [0|1] "SED"  APIM_CDC,APIM_CIM,IPC
 SG_ MildHybStat_D_Dsply : 50|3@0+ (1,0) [0|7] "SED"  APIM_CDC,IPC,APIM_CIM

BO_ 791 Cluster_HEV_Data8: 8 IPC
 SG_ StopStrtVThres_D_RqMnu : 17|2@0+ (1,0) [0|3] "SED"  GWM
 SG_ AwdDrvMde_D2_Rq : 21|4@0+ (1,0) [0|15] "SED"  GWM
 SG_ EngAirFilt_B_RqReset : 48|1@0+ (1,0) [0|1] "SED"  GWM
 SG_ BattElEmotive_Pc_Dsply : 1|10@0+ (0.1,0) [0|102.1] "percent"  APIM,APIM_CISM,GWM
 SG_ VehElEffTrip2Reset_B_Rq : 62|1@0+ (1,0) [0|1] "SED"  GWM
 SG_ VehElEffTrip1Reset_B_Rq : 63|1@0+ (1,0) [0|1] "SED"  GWM
 SG_ HybMdeOvrrd_D_Rq : 7|2@0+ (1,0) [0|3] "SED"  GWM
 SG_ GpsElMdeSel_B_Rq : 50|1@0+ (1,0) [0|1] "SED"  GWM
 SG_ LongTermReset_B_Rq : 49|1@0+ (1,0) [0|1] "SED"  GWM
 SG_ EcoCcActv_B_Rq : 51|1@0+ (1,0) [0|1] "SED"  GWM
 SG_ DrvEffLvl_No_Stat : 61|6@0+ (1,0) [0|61] "unitless"  APIM_CDC,APIM,APIM_CISM,GWM
 SG_ ChargeProfIDPref_Rq : 5|2@0+ (1,0) [0|3] "SED"  GWM
 SG_ ConsAvgTrip_Fe_Dsply : 31|24@0+ (0.0001,0) [0|1677.7215] "litre/100km"  GWM
 SG_ GrdAsstAllw_D_RqMnu : 23|2@0+ (1,0) [0|3] "SED"  GWM
 SG_ PlgOvrrdStrt_D_Cmd : 55|2@0+ (1,0) [0|3] "SED"  GWM
 SG_ EcoMde_D_RqMnu : 3|2@0+ (1,0) [0|3] "SED"  GWM
 SG_ EmotiveType_D_Dsply : 53|2@0+ (1,0) [0|3] "SED"  APIM,APIM_CISM,GWM

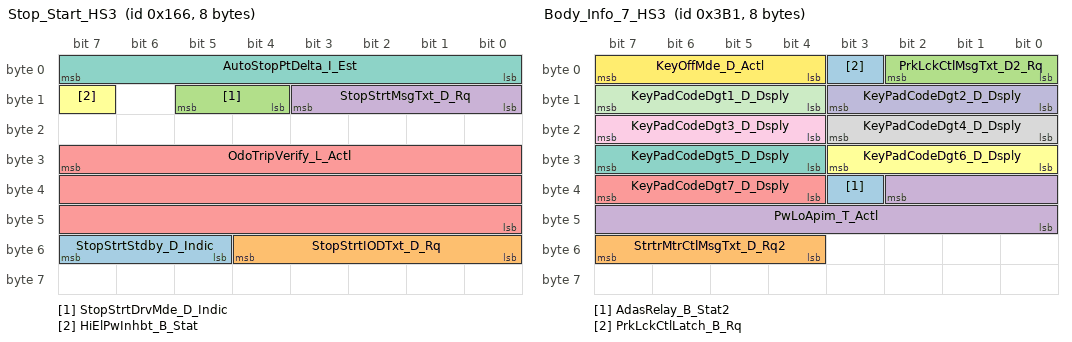
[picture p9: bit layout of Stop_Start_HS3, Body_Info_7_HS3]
BO_ 358 Stop_Start_HS3: 8 GWM
 SG_ StopStrtStdby_D_Indic : 55|3@0+ (1,0) [0|7] "SED"  APIM_CDC,APIM_CISM,APIM_CIM,IPC
 SG_ StopStrtIODTxt_D_Rq : 52|5@0+ (1,0) [0|31] "SED"  APIM_CDC,APIM_CISM,APIM_CIM,IPC
 SG_ StopStrtDrvMde_D_Indic : 13|2@0+ (1,0) [0|3] "SED"  APIM_CDC,APIM,APIM_CIM,APIM_CISM,IPC
 SG_ StopStrtMsgTxt_D_Rq : 11|4@0+ (1,0) [0|15] "SED"  APIM_CDC,APIM_CIM,IPC
 SG_ OdoTripVerify_L_Actl : 31|24@0+ (0.1,0) [0|1677721.4] "km"  APIM_CDC,APIM_CIM,IPC
 SG_ HiElPwInhbt_B_Stat : 15|1@0+ (1,0) [0|1] "SED"  GENERIC
 SG_ AutoStopPtDelta_I_Est : 7|8@0+ (1,-127) [-127|127] "Amps"  GENERIC

BO_ 945 Body_Info_7_HS3: 8 GWM
 SG_ AdasRelay_B_Stat2 : 35|1@0+ (1,0) [0|1] "SED" Vector__XXX
 SG_ StrtrMtrCtlMsgTxt_D_Rq2 : 55|4@0+ (1,0) [0|15] "SED"  APIM_CDC,APIM_CIM,IPC
 SG_ PrkLckCtlMsgTxt_D2_Rq : 2|3@0+ (1,0) [0|7] "SED"  APIM_CDC,APIM,APIM_CIM,IPC,APIM_CISM
 SG_ PwLoApim_T_Actl : 34|11@0+ (1,0) [0|2047] "minute"  APIM_CDC,APIM,APIM_CISM,APIM_CIM
 SG_ KeyPadCodeDgt7_D_Dsply : 39|4@0+ (1,0) [0|15] "SED"  IPC
 SG_ KeyPadCodeDgt6_D_Dsply : 27|4@0+ (1,0) [0|15] "SED"  IPC
 SG_ KeyPadCodeDgt5_D_Dsply : 31|4@0+ (1,0) [0|15] "SED"  IPC
 SG_ KeyPadCodeDgt4_D_Dsply : 19|4@0+ (1,0) [0|15] "SED"  IPC
 SG_ KeyPadCodeDgt3_D_Dsply : 23|4@0+ (1,0) [0|15] "SED"  IPC
 SG_ KeyPadCodeDgt2_D_Dsply : 11|4@0+ (1,0) [0|15] "SED"  IPC
 SG_ KeyPadCodeDgt1_D_Dsply : 15|4@0+ (1,0) [0|15] "SED"  IPC
 SG_ KeyOffMde_D_Actl : 7|4@0+ (1,0) [0|15] "SED"  APIM_CDC,APIM,APIM_CIM,APIM_CISM,IPC,TRM_ITRM
 SG_ PrkLckCtlLatch_B_Rq : 3|1@0+ (1,0) [0|1] "SED"  APIM_CDC,APIM_CIM,IPC

BO_ 740 ACM_Send_Signals_2: 8 ACM
 SG_ EmgcyAsstActv_D_Stat : 7|2@0+ (1,0) [0|3] "SED"  GWM

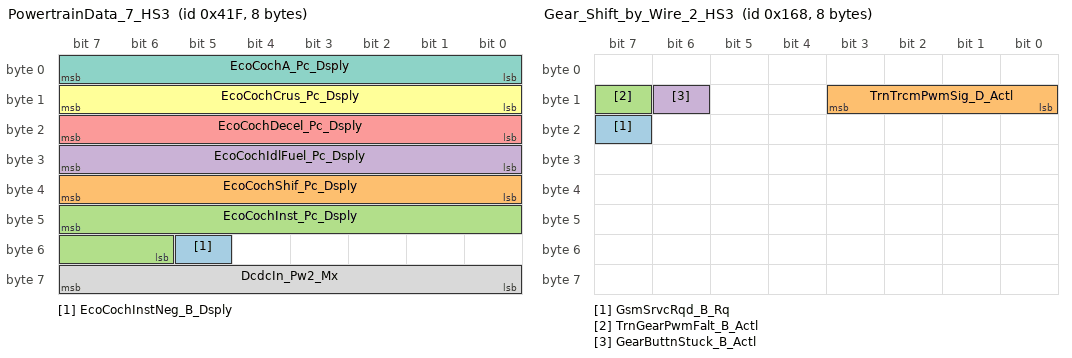
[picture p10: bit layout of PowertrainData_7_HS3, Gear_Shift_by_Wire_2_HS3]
BO_ 1055 PowertrainData_7_HS3: 8 GWM
 SG_ EcoCochInstNeg_B_Dsply : 53|1@0+ (1,0) [0|1] "SED"  APIM_CDC,APIM_CISM,APIM_CIM,IPC
 SG_ EcoCochShif_Pc_Dsply : 39|8@0+ (0.392157,0) [0|100.000035] "percent"  APIM,APIM_CDC,APIM_CISM,APIM_CIM,IPC
 SG_ EcoCochInst_Pc_Dsply : 47|10@0+ (0.1,0) [0|102.3] "percent"  APIM_CDC,APIM_CISM,APIM_CIM,IPC
 SG_ EcoCochIdlFuel_Pc_Dsply : 31|8@0+ (0.392157,0) [0|100.000035] "percent"  APIM_CDC,APIM_CISM,APIM_CIM,IPC
 SG_ EcoCochDecel_Pc_Dsply : 23|8@0+ (0.392157,0) [0|100.000035] "percent"  APIM_CDC,APIM,APIM_CISM,APIM_CIM,IPC
 SG_ EcoCochCrus_Pc_Dsply : 15|8@0+ (0.392157,0) [0|100.000035] "percent"  APIM_CDC,APIM,APIM_CISM,APIM_CIM,IPC
 SG_ EcoCochA_Pc_Dsply : 7|8@0+ (0.392157,0) [0|100.000035] "percent"  APIM_CDC,APIM,APIM_CISM,APIM_CIM,IPC
 SG_ DcdcIn_Pw2_Mx : 63|8@0+ (20,500) [500|5600] "watts" Vector__XXX

BO_ 360 Gear_Shift_by_Wire_2_HS3: 8 GWM
 SG_ GsmSrvcRqd_B_Rq : 23|1@0+ (1,0) [0|1] "SED"  APIM_CDC,APIM_CIM,IPC
 SG_ TrnTrcmPwmSig_D_Actl : 11|4@0+ (1,0) [0|15] "SED"  GENERIC
 SG_ TrnGearPwmFalt_B_Actl : 15|1@0+ (1,0) [0|1] "SED"  GENERIC
 SG_ GearButtnStuck_B_Actl : 14|1@0+ (1,0) [0|1] "SED"  GENERIC

BO_ 1839 TesterPhysicalResACM: 8 ACM
 SG_ TesterPhysicalResACM : 7|64@0+ (1,0) [0|1.84467E+019] "unitless"  TSTR

BO_ 1831 TesterPhysicalReqACM: 8 TSTR
 SG_ TesterPhysicalReqACM : 7|64@0+ (1,0) [0|1.84467E+019] "unitless"  ACM

BO_ 1056 SelectDriveModeData_HS3: 8 GWM
 SG_ VehVActlBrk_No_Corr : 0|8@1+ (0.001,0.9) [0.9|1.153] "unitless"  IPC
 SG_ AutoEpbButtnOn_B_Stat : 48|1@0+ (1,0) [0|1] "SED"  APIM_CDC,APIM,APIM_CIM,APIM_CISM
 SG_ AutoEpbMsgTxt_D_Rq : 58|3@0+ (1,0) [0|7] "SED"  APIM_CDC,APIM,APIM_CIM,APIM_CISM
 SG_ AutoEpbDsply_D_Stat : 37|2@0+ (1,0) [0|3] "SED"  APIM_CDC,APIM,APIM_CIM,APIM_CISM
 SG_ SelDrvMdeHmi03_D_Rq : 12|5@0+ (1,0) [0|31] "SED" Vector__XXX
 SG_ SelDrvMdePos12_B_Avail : 54|1@0+ (1,0) [0|1] "SED"  APIM_CDC,APIM,APIM_CISM,APIM_CIM,IPC
 SG_ SelDrvMdePos11_B_Avail : 55|1@0+ (1,0) [0|1] "SED"  APIM_CDC,APIM,APIM_CISM,APIM_CIM,IPC
 SG_ SelDrvMdePos10_B_Avail : 40|1@0+ (1,0) [0|1] "SED"  APIM_CDC,APIM,APIM_CISM,APIM_CIM,IPC
 SG_ SelDrvMdePos09_B_Avail : 41|1@0+ (1,0) [0|1] "SED"  APIM_CDC,APIM,APIM_CISM,APIM_CIM,IPC
 SG_ SelDrvMdePos08_B_Avail : 42|1@0+ (1,0) [0|1] "SED"  APIM_CDC,APIM,APIM_CISM,APIM_CIM,IPC
 SG_ SelDrvMdePos07_B_Avail : 43|1@0+ (1,0) [0|1] "SED"  APIM_CDC,APIM,APIM_CISM,APIM_CIM,IPC
 SG_ SelDrvMdePos06_B_Avail : 44|1@0+ (1,0) [0|1] "SED"  APIM_CDC,APIM,APIM_CISM,APIM_CIM,IPC
 SG_ SelDrvMdePos05_B_Avail : 45|1@0+ (1,0) [0|1] "SED"  APIM_CDC,APIM,APIM_CISM,APIM_CIM,IPC
 SG_ SelDrvMdePos04_B_Avail : 46|1@0+ (1,0) [0|1] "SED"  APIM_CDC,APIM,APIM_CISM,APIM_CIM,IPC
 SG_ SelDrvMdePos03_B_Avail : 47|1@0+ (1,0) [0|1] "SED"  APIM_CDC,APIM,APIM_CISM,APIM_CIM,IPC
 SG_ SelDrvMdePos02_B_Avail : 32|1@0+ (1,0) [0|1] "SED"  APIM_CDC,APIM,APIM_CISM,APIM_CIM,IPC
 SG_ SelDrvMdePos01_B_Avail : 24|1@0+ (1,0) [0|1] "SED"  APIM_CDC,APIM,APIM_CISM,APIM_CIM,IPC
 SG_ SelDrvMdeMsgTxt2_D_Rq : 23|4@0+ (1,0) [0|15] "SED"  APIM_CDC,APIM,APIM_CIM,APIM_CISM
 SG_ ActvDrvMde_D2_Stat : 53|5@0+ (1,0) [0|31] "SED"  APIM_CDC,APIM,APIM_CISM,APIM_CIM,HUD_ADV,ACM,IPC
 SG_ SelDrvMde_D2_Rq : 63|5@0+ (1,0) [0|31] "SED"  APIM_CDC,APIM,APIM_CISM,APIM_CIM,IPC
 SG_ AwdMde_D_RqBrk : 35|3@0+ (1,0) [0|7] "SED"  GENERIC
 SG_ SelDrvMdePt_D_Rq : 31|5@0+ (1,0) [0|31] "SED"  GENERIC
 SG_ SelDrvMdeMsgTxt_D_Rq : 19|4@0+ (1,0) [0|15] "SED"  APIM_CDC,APIM_CIM,IPC
 SG_ SelDrvMde_D_Stat : 26|2@0+ (1,0) [0|3] "SED"  APIM_CDC,APIM,APIM_CISM,APIM_CIM,IPC

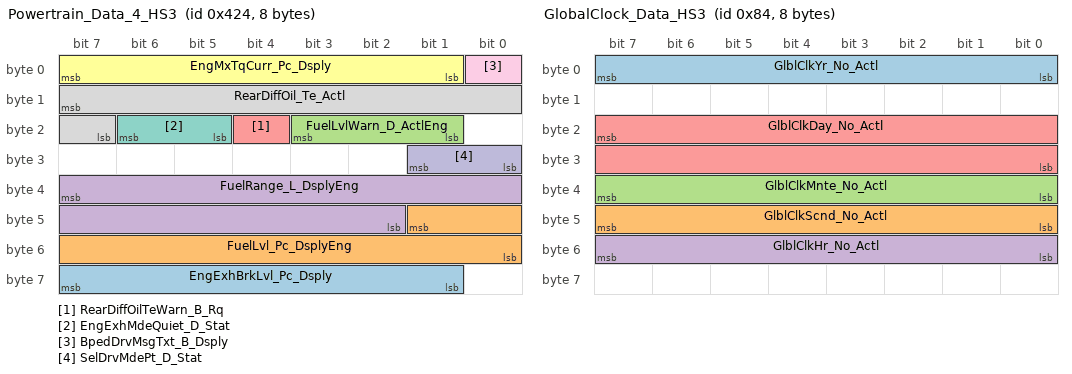
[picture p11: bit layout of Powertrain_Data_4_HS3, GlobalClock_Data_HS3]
BO_ 1060 Powertrain_Data_4_HS3: 8 GWM
 SG_ EngExhBrkLvl_Pc_Dsply : 63|7@0+ (1,0) [0|127] "Percent"  APIM_CDC,APIM_CIM,IPC
 SG_ FuelLvl_Pc_DsplyEng : 41|10@0+ (0.108696,-5.217408) [-5.217408|105.9786] "percent"  APIM_CDC,APIM,APIM_CISM,APIM_CIM,IPC
 SG_ FuelLvlWarn_D_ActlEng : 19|3@0+ (1,0) [0|7] "SED"  APIM_CDC,APIM,APIM_CISM,APIM_CIM,IPC
 SG_ FuelRange_L_DsplyEng : 39|14@0+ (0.1,0) [0|1638.3] "kilometer"  APIM_CDC,APIM_CIM,IPC
 SG_ RearDiffOilTeWarn_B_Rq : 20|1@0+ (1,0) [0|1] "SED"  APIM_CDC,APIM_CIM,IPC
 SG_ EngMxTqCurr_Pc_Dsply : 7|7@0+ (1,0) [0|100] "percent"  APIM_CDC,APIM_CIM,IPC
 SG_ EngExhMdeQuiet_D_Stat : 22|2@0+ (1,0) [0|3] "SED"  APIM_CDC,APIM_CISM,APIM_CIM,ACM,IPC
 SG_ RearDiffOil_Te_Actl : 15|9@0+ (1,-40) [-40|470] "degC"  APIM_CDC,APIM,APIM_CISM,APIM_CIM,IPC
 SG_ BpedDrvMsgTxt_B_Dsply : 0|1@0+ (1,0) [0|1] "SED"  APIM_CDC,APIM_CIM,IPC
 SG_ SelDrvMdePt_D_Stat : 25|2@0+ (1,0) [0|3] "SED"  GENERIC

BO_ 132 GlobalClock_Data_HS3: 8 GWM
 SG_ GlblClkYr_No_Actl : 7|8@0+ (1,2000) [2000|2255] "year"  APIM_CDC,ACM,APIM,APIM_CIM,APIM_CISM,RACM_RCIM,HUD_ADV,TRM_ITRM,IPC
 SG_ GlblClkScnd_No_Actl : 47|8@0+ (1,0) [0|255] "second"  APIM_CDC,APIM,APIM_CIM,APIM_CISM,RACM_RCIM,HUD_ADV,TRM_ITRM,IPC
 SG_ GlblClkMnte_No_Actl : 39|8@0+ (1,0) [0|255] "minute"  APIM_CDC,APIM,APIM_CIM,APIM_CISM,RACM_RCIM,HUD_ADV,TRM_ITRM,IPC
 SG_ GlblClkHr_No_Actl : 55|8@0+ (1,0) [0|255] "hour"  APIM_CDC,APIM,APIM_CIM,APIM_CISM,RACM_RCIM,HUD_ADV,TRM_ITRM,IPC
 SG_ GlblClkDay_No_Actl : 23|16@0+ (1,0) [0|65535] "julian day"  APIM_CDC,ACM,APIM,APIM_CIM,APIM_CISM,RACM_RCIM,HUD_ADV,TRM_ITRM,IPC

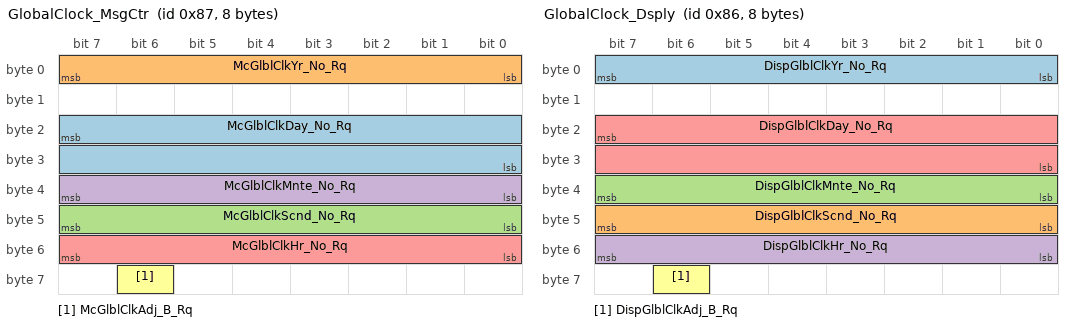
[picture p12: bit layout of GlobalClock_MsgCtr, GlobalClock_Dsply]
BO_ 135 GlobalClock_MsgCtr: 8 IPC
 SG_ McGlblClkDay_No_Rq : 23|16@0+ (1,0) [0|65535] "julian day"  GWM
 SG_ McGlblClkYr_No_Rq : 7|8@0+ (1,2000) [2000|2255] "year"  GWM
 SG_ McGlblClkScnd_No_Rq : 47|8@0+ (1,0) [0|255] "second"  GWM
 SG_ McGlblClkMnte_No_Rq : 39|8@0+ (1,0) [0|255] "minute"  GWM
 SG_ McGlblClkHr_No_Rq : 55|8@0+ (1,0) [0|255] "hour"  GWM
 SG_ McGlblClkAdj_B_Rq : 62|1@0+ (1,0) [0|1] "SED"  GWM

BO_ 134 GlobalClock_Dsply: 8 APIM_CIM
 SG_ DispGlblClkYr_No_Rq : 7|8@0+ (1,2000) [2000|2255] "year"  IPC,GWM
 SG_ DispGlblClkScnd_No_Rq : 47|8@0+ (1,0) [0|255] "second"  IPC,GWM
 SG_ DispGlblClkMnte_No_Rq : 39|8@0+ (1,0) [0|255] "minute"  IPC,GWM
 SG_ DispGlblClkHr_No_Rq : 55|8@0+ (1,0) [0|255] "hour"  IPC,GWM
 SG_ DispGlblClkDay_No_Rq : 23|16@0+ (1,0) [0|65535] "julian day"  IPC,GWM
 SG_ DispGlblClkAdj_B_Rq : 62|1@0+ (1,0) [0|1] "SED"  IPC,GWM

BO_ 559 ElecHorizon_Data2: 8 APIM_CIM
 SG_ EhData2_No_Actl : 7|64@0+ (1,0) [0|1.84467440737096E+019] "unitless"  HUD_ADV,GWM

BO_ 558 ElecHorizon_Data1: 8 APIM
 SG_ EhData1_No_Actl : 7|64@0+ (1,0) [0|1.84467440737096E+019] "unitless"  HUD_ADV,GWM

BO_ 939 ParkAid_Aud_Warn_Stat2_HS3: 8 GWM
 SG_ DrTgateMde_D_Stat : 49|2@0+ (1,0) [0|3] "SED"  APIM_CDC,APIM,APIM_CIM,APIM_CISM
 SG_ ResPrkAidSnsRlSide_D_Stat : 23|4@0+ (1,0) [0|15] "SED"  APIM_CDC,APIM,APIM_CIM,APIM_CISM,IPC
 SG_ SidePrkSnsR4_D_Stat : 55|4@0+ (1,0) [0|15] "SED"  APIM_CDC,APIM,APIM_CIM,APIM_CISM,IPC
 SG_ SidePrkSnsR3_D_Stat : 47|4@0+ (1,0) [0|15] "SED"  APIM_CDC,APIM,APIM_CIM,APIM_CISM,IPC
 SG_ SidePrkSnsL4_D_Stat : 43|4@0+ (1,0) [0|15] "SED"  APIM_CDC,APIM,APIM_CIM,APIM_CISM,IPC
 SG_ SidePrkSnsL3_D_Stat : 37|4@0+ (1,0) [0|15] "SED"  APIM_CDC,APIM,APIM_CIM,APIM_CISM,IPC
 SG_ PrkAidChime_D_Stat : 4|2@0+ (1,0) [0|3] "SED"  APIM_CDC,APIM_CIM,IPC
 SG_ PrkAidSnsRlCntr_D_Stat : 15|4@0+ (1,0) [0|15] "SED"  APIM_CDC,APIM,APIM_CIM,APIM_CISM,IPC
 SG_ PrkAidSnsRrCrnr_D_Stat : 31|4@0+ (1,0) [0|15] "SED"  APIM_CDC,APIM,APIM_CIM,APIM_CISM,IPC
 SG_ PrkAidSnsRrCntr_D_Stat : 19|4@0+ (1,0) [0|15] "SED"  APIM_CDC,APIM,APIM_CIM,APIM_CISM,IPC
 SG_ PrkAidSnsRlCrnr_D_Stat : 11|4@0+ (1,0) [0|15] "SED"  APIM_CDC,APIM,APIM_CIM,APIM_CISM,IPC
 SG_ PrkAidRear_D_Stat : 39|2@0+ (1,0) [0|3] "SED"  APIM_CDC,APIM,APIM_CIM,APIM_CISM,IPC
 SG_ PrkAidFront_D_Stat : 2|2@0+ (1,0) [0|3] "SED"  APIM_CDC,APIM,APIM_CISM,APIM_CIM,IPC
 SG_ PrkAid_D_Falt : 7|3@0+ (1,0) [0|7] "SED"  APIM_CDC,APIM_CIM,IPC
 SG_ ResPrkAidSnsRrSide_D_Stat : 27|4@0+ (1,0) [0|15] "SED"  APIM_CDC,APIM,APIM_CIM,APIM_CISM,IPC
 SG_ PrkAidLamp_D_Rq : 33|2@0+ (1,0) [0|3] "SED"  FCIMB
 SG_ ApaLongCtrlEnbl_D_Rq : 0|1@0+ (1,0) [0|1] "SED"  GENERIC
 SG_ ApaBrk_A_Rq : 63|8@0+ (0.05,-12.75) [-12.75|0] "m/sec^2"  GENERIC
 SG_ ApaBrk_D_Rq : 51|2@0+ (1,0) [0|3] "SED"  GENERIC

BO_ 938 ParkAid_Aud_Warn_Stat_HS3: 8 GWM
 SG_ SidePrkSnsR2_D_Stat : 59|4@0+ (1,0) [0|15] "SED"  APIM_CDC,APIM,APIM_CIM,APIM_CISM,IPC
 SG_ SidePrkSnsR1_D_Stat : 63|4@0+ (1,0) [0|15] "SED"  APIM_CDC,APIM,APIM_CIM,APIM_CISM,IPC
 SG_ SidePrkSnsL2_D_Stat : 51|4@0+ (1,0) [0|15] "SED"  APIM_CDC,APIM,APIM_CIM,APIM_CISM,IPC
 SG_ SidePrkSnsL1_D_Stat : 55|4@0+ (1,0) [0|15] "SED"  APIM_CDC,APIM,APIM_CIM,APIM_CISM,IPC
 SG_ ApaMde_D_Stat : 23|3@0+ (1,0) [0|7] "SED"  APIM_CDC,APIM,APIM_CIM,APIM_CISM,IPC
 SG_ ApaActvSd_D_Actl : 14|2@0+ (1,0) [0|3] "SED"  APIM,APIM_CIM,APIM_CISM,IPC
 SG_ PrkAidSwtch_B_Stat : 8|1@0+ (1,0) [0|1] "SED"  APIM_CDC,APIM,APIM_CISM,APIM_CIM,IPC
 SG_ PrkAidMsgTxt_D_Rq : 19|4@0+ (1,0) [0|15] "SED"  APIM_CDC,APIM,APIM_CISM,APIM_CIM,IPC
 SG_ ApaMde_D_Avail : 12|4@0+ (1,0) [0|15] "SED"  APIM,APIM_CIM,APIM_CISM
 SG_ PrkAidSnsFrCrnr_D_Stat : 47|4@0+ (1,0) [0|15] "SED"  APIM_CDC,APIM,APIM_CIM,APIM_CISM,IPC
 SG_ PrkAidSnsFrCntr_D_Stat : 35|4@0+ (1,0) [0|15] "SED"  APIM_CDC,APIM,APIM_CIM,APIM_CISM,IPC
 SG_ PrkAidSnsFlCrnr_D_Stat : 27|4@0+ (1,0) [0|15] "SED"  APIM_CDC,APIM,APIM_CIM,APIM_CISM,IPC
 SG_ PrkAidSnsFlCntr_D_Stat : 31|4@0+ (1,0) [0|15] "SED"  APIM_CDC,APIM,APIM_CIM,APIM_CISM,IPC
 SG_ RpaChime_D_Rq : 7|4@0+ (1,0) [0|15] "SED"  APIM_CDC,APIM,APIM_CISM,APIM_CIM,IPC
 SG_ FpaChime_D_Rq : 3|4@0+ (1,0) [0|15] "SED"  APIM_CDC,APIM,APIM_CISM,APIM_CIM,IPC
 SG_ PrkAidAudioMute_B_Rq : 15|1@0+ (1,0) [0|1] "SED"  APIM_CDC,APIM_CIM,IPC
 SG_ PrkBrkEl_B_RqFap : 20|1@0+ (1,0) [0|1] "SED"  APIM_CIM,GENERIC

BO_ 952 Tire_Pressure_Data_DRW_HS3: 8 GWM
 SG_ Tire_Press_IRR_Data : 23|16@0+ (1,0) [0|65533] "kilopascal"  APIM_CDC,APIM,APIM_CISM,APIM_CIM,IPC
 SG_ Tire_Press_ILR_Data : 7|16@0+ (1,0) [0|65533] "kilopascal"  APIM_CDC,APIM,APIM_CISM,APIM_CIM,IPC

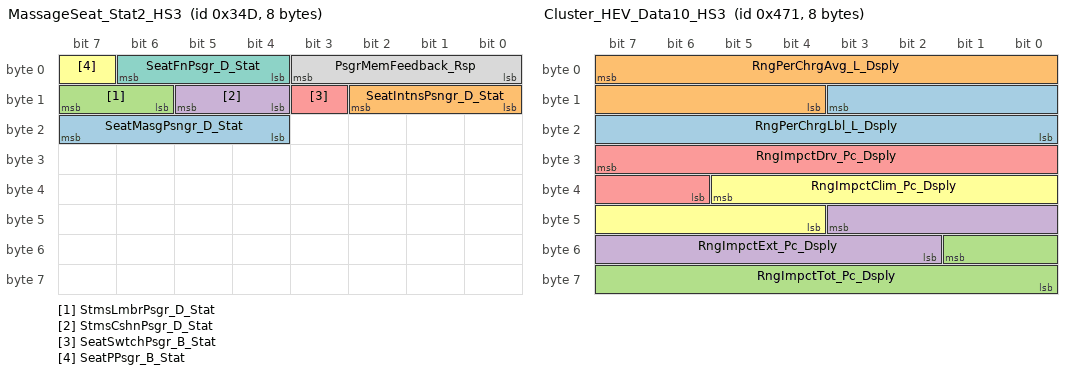
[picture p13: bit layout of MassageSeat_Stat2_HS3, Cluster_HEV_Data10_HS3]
BO_ 845 MassageSeat_Stat2_HS3: 8 GWM
 SG_ SeatMasgPsngr_D_Stat : 23|4@0+ (1,0) [0|15] "SED"  APIM_CDC,APIM,APIM_CIM,APIM_CISM
 SG_ SeatIntnsPsngr_D_Stat : 10|3@0+ (1,0) [0|7] "SED"  APIM_CDC,APIM,APIM_CIM,APIM_CISM
 SG_ StmsLmbrPsgr_D_Stat : 15|2@0+ (1,0) [0|3] "SED"  APIM_CDC,APIM,APIM_CIM,APIM_CISM
 SG_ StmsCshnPsgr_D_Stat : 13|2@0+ (1,0) [0|3] "SED"  APIM_CDC,APIM,APIM_CIM,APIM_CISM
 SG_ SeatSwtchPsgr_B_Stat : 11|1@0+ (1,0) [0|1] "SED"  APIM_CDC,APIM,APIM_CIM,APIM_CISM
 SG_ SeatPPsgr_B_Stat : 7|1@0+ (1,0) [0|1] "SED"  APIM_CDC,APIM,APIM_CIM,APIM_CISM
 SG_ SeatFnPsgr_D_Stat : 6|3@0+ (1,0) [0|7] "SED"  APIM_CDC,APIM,APIM_CIM,APIM_CISM
 SG_ PsgrMemFeedback_Rsp : 3|4@0+ (1,0) [0|15] "SED"  APIM_CDC,APIM,APIM_CIM,APIM_CISM

BO_ 1137 Cluster_HEV_Data10_HS3: 8 GWM
 SG_ RngPerChrgLbl_L_Dsply : 11|12@0+ (0.1,0) [0|409.3] "km"  APIM_CDC,APIM_CISM,APIM_CIM,IPC
 SG_ RngPerChrgAvg_L_Dsply : 7|12@0+ (0.1,0) [0|409.3] "km"  APIM_CDC,APIM,APIM_CIM,APIM_CISM,IPC
 SG_ RngImpctTot_Pc_Dsply : 49|10@0+ (0.2,-102) [-102|102.4] "percent"  APIM_CDC,APIM_CISM,APIM_CIM,IPC
 SG_ RngImpctExt_Pc_Dsply : 43|10@0+ (0.2,-102) [-102|102.4] "percent"  APIM_CDC,APIM_CISM,APIM_CIM,IPC
 SG_ RngImpctDrv_Pc_Dsply : 31|10@0+ (0.2,-102) [-102|102.4] "percent"  APIM_CDC,APIM_CISM,APIM_CIM,IPC
 SG_ RngImpctClim_Pc_Dsply : 37|10@0+ (0.2,-102) [-102|102.4] "percent"  APIM_CDC,APIM_CISM,APIM_CIM,IPC

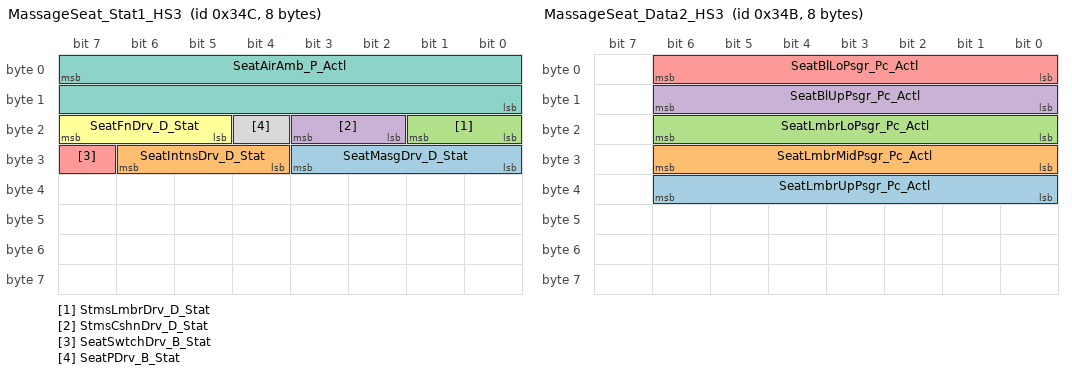
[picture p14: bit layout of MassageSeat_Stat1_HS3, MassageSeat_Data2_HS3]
BO_ 844 MassageSeat_Stat1_HS3: 8 GWM
 SG_ SeatMasgDrv_D_Stat : 27|4@0+ (1,0) [0|15] "SED"  APIM_CDC,APIM,APIM_CIM,APIM_CISM
 SG_ SeatIntnsDrv_D_Stat : 30|3@0+ (1,0) [0|7] "SED"  APIM_CDC,APIM,APIM_CIM,APIM_CISM
 SG_ StmsLmbrDrv_D_Stat : 17|2@0+ (1,0) [0|3] "SED"  APIM_CDC,APIM,APIM_CIM,APIM_CISM
 SG_ StmsCshnDrv_D_Stat : 19|2@0+ (1,0) [0|3] "SED"  APIM_CDC,APIM,APIM_CIM,APIM_CISM
 SG_ SeatSwtchDrv_B_Stat : 31|1@0+ (1,0) [0|1] "SED"  APIM_CDC,APIM,APIM_CIM,APIM_CISM
 SG_ SeatFnDrv_D_Stat : 23|3@0+ (1,0) [0|7] "SED"  APIM_CDC,APIM,APIM_CIM,APIM_CISM
 SG_ SeatAirAmb_P_Actl : 7|16@0+ (0.01,0) [0|655.35] "KiloPascal"  APIM_CDC,APIM,APIM_CIM,APIM_CISM
 SG_ SeatPDrv_B_Stat : 20|1@0+ (1,0) [0|1] "SED"  APIM_CDC,APIM,APIM_CIM,APIM_CISM

BO_ 843 MassageSeat_Data2_HS3: 8 GWM
 SG_ SeatLmbrUpPsgr_Pc_Actl : 38|7@0+ (1,0) [0|127] "Percent"  APIM_CDC,APIM,APIM_CIM,APIM_CISM
 SG_ SeatLmbrMidPsgr_Pc_Actl : 30|7@0+ (1,0) [0|127] "Percent"  APIM_CDC,APIM,APIM_CIM,APIM_CISM
 SG_ SeatLmbrLoPsgr_Pc_Actl : 22|7@0+ (1,0) [0|127] "Percent"  APIM_CDC,APIM,APIM_CIM,APIM_CISM
 SG_ SeatBlUpPsgr_Pc_Actl : 14|7@0+ (1,0) [0|126] "Percent"  APIM_CDC,APIM,APIM_CIM,APIM_CISM
 SG_ SeatBlLoPsgr_Pc_Actl : 6|7@0+ (1,0) [0|126] "Percent"  APIM_CDC,APIM,APIM_CIM,APIM_CISM

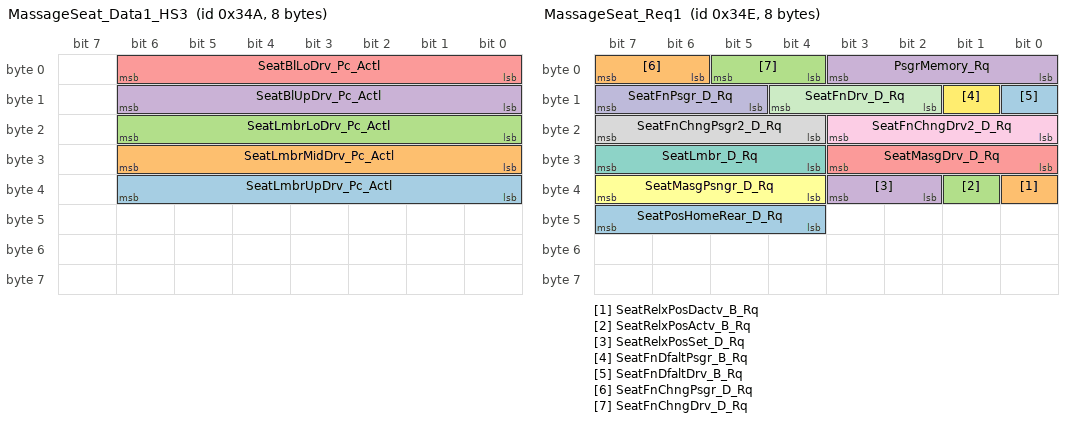
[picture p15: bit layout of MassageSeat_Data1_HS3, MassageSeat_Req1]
BO_ 842 MassageSeat_Data1_HS3: 8 GWM
 SG_ SeatLmbrUpDrv_Pc_Actl : 38|7@0+ (1,0) [0|127] "Percent"  APIM_CDC,APIM,APIM_CIM,APIM_CISM
 SG_ SeatLmbrMidDrv_Pc_Actl : 30|7@0+ (1,0) [0|127] "Percent"  APIM_CDC,APIM,APIM_CIM,APIM_CISM
 SG_ SeatLmbrLoDrv_Pc_Actl : 22|7@0+ (1,0) [0|127] "Percent"  APIM_CDC,APIM,APIM_CIM,APIM_CISM
 SG_ SeatBlUpDrv_Pc_Actl : 14|7@0+ (1,0) [0|126] "Percent"  APIM_CDC,APIM,APIM_CIM,APIM_CISM
 SG_ SeatBlLoDrv_Pc_Actl : 6|7@0+ (1,0) [0|126] "Percent"  APIM_CDC,APIM,APIM_CIM,APIM_CISM

BO_ 846 MassageSeat_Req1: 8 APIM_CIM
 SG_ SeatPosHomeRear_D_Rq : 47|4@0+ (1,0) [0|15] "SED"  GWM
 SG_ SeatRelxPosDactv_B_Rq : 32|1@0+ (1,0) [0|1] "SED"  GWM
 SG_ SeatRelxPosActv_B_Rq : 33|1@0+ (1,0) [0|1] "SED"  GWM
 SG_ SeatRelxPosSet_D_Rq : 35|2@0+ (1,0) [0|3] "SED"  GWM
 SG_ SeatMasgDrv_D_Rq : 27|4@0+ (1,0) [0|15] "SED"  GWM
 SG_ SeatMasgPsngr_D_Rq : 39|4@0+ (1,0) [0|15] "SED"  GWM
 SG_ SeatLmbr_D_Rq : 31|4@0+ (1,0) [0|15] "SED"  GWM
 SG_ SeatFnChngPsgr2_D_Rq : 23|4@0+ (1,0) [0|15] "SED"  GWM
 SG_ SeatFnChngDrv2_D_Rq : 19|4@0+ (1,0) [0|15] "SED"  GWM
 SG_ SeatFnPsgr_D_Rq : 15|3@0+ (1,0) [0|7] "SED"  GWM
 SG_ SeatFnDrv_D_Rq : 12|3@0+ (1,0) [0|7] "SED"  GWM
 SG_ SeatFnDfaltPsgr_B_Rq : 9|1@0+ (1,0) [0|1] "SED"  GWM
 SG_ SeatFnDfaltDrv_B_Rq : 8|1@0+ (1,0) [0|1] "SED"  GWM
 SG_ SeatFnChngPsgr_D_Rq : 7|2@0+ (1,0) [0|3] "SED"  GWM
 SG_ SeatFnChngDrv_D_Rq : 5|2@0+ (1,0) [0|3] "SED"  GWM
 SG_ PsgrMemory_Rq : 3|4@0+ (1,0) [0|15] "SED"  GWM

BO_TX_BU_ 811 : APIM_CDC,APIM_CIM,APIM_CISM,APIM;
BO_TX_BU_ 543 : APIM_CDC,APIM_CIM,IPC;
BO_TX_BU_ 579 : APIM_CISM,APIM_CIM,APIM_CDC,APIM,ACM;
BO_TX_BU_ 578 : APIM_CDC,APIM_CIM,APIM_CISM,APIM;
BO_TX_BU_ 577 : APIM_CDC,APIM_CIM,APIM_CISM,APIM;
BO_TX_BU_ 717 : APIM_CDC,APIM_CIM,APIM_CISM,APIM;
BO_TX_BU_ 719 : APIM_CISM,APIM;
BO_TX_BU_ 589 : APIM_CIM,APIM_CISM,APIM;
BO_TX_BU_ 737 : APIM_CDC,APIM_CIM,APIM_CISM,APIM;
BO_TX_BU_ 1185 : APIM_CDC,APIM_CIM,IPC;
BO_TX_BU_ 1109 : APIM_CDC,APIM_CIM,APIM_CISM,APIM;
BO_TX_BU_ 718 : APIM_CDC,APIM_CIM,APIM_CISM,APIM;
BO_TX_BU_ 140 : APIM_CDC,APIM_CIM,IPC;
BO_TX_BU_ 546 : APIM_CDC,APIM_CIM,APIM_CISM,APIM;
BO_TX_BU_ 1232 : APIM_CISM,ACM,APIM_CIM;
BO_TX_BU_ 684 : APIM_CISM,APIM;
BO_TX_BU_ 791 : APIM_CDC,APIM_CIM,IPC;
BO_TX_BU_ 135 : APIM_CIM,APIM_CDC,IPC;
BO_TX_BU_ 134 : APIM,APIM_CDC,APIM_CISM,APIM_CIM;
BO_TX_BU_ 559 : APIM,APIM_CDC,APIM_CISM,APIM_CIM;
BO_TX_BU_ 558 : APIM_CDC,APIM_CIM,APIM_CISM,APIM;
BO_TX_BU_ 846 : APIM,APIM_CDC,APIM_CISM,APIM_CIM;
CM_ SG_ 563 NtfyDrvTrgtDist_L2_Rq "Object.SetTripRangeAlert_Rq
This signal is meant to provide the customer settings for the target distance remote notification";
CM_ SG_ 587 PHONE_RDISP2_WORD_Rx "MM ISO 15765-2 Message Catalogue
Section MC - PHONE";
CM_ SG_ 579 PHONE_RDISP2_WORD_Tx "MM ISO 15765-2 Message Catalogue
Section  PHONE - MC";
CM_ SG_ 585 NAV_RDISP2_WORD_Rx "MM ISO 15765-2 Message Catalogue NavRepClient2 - NavRepServer";
CM_ SG_ 586 CONMP_RDISP2_WORD_Rx "MM ISO 15765-2 Message Catalogue
Section CONMP - MC
Section MediaPlayerServer - MediaPlayerClient";
CM_ SG_ 578 CONMP_RDISP2_WORD_Tx "MM ISO 15765-2 Message Catalogue
Section CONMP - MC
Section MediaPlayerServer - MediaPlayerClient";
CM_ SG_ 577 NAV_RDISP2_WORD_Tx "MM ISO 15765-2 Message Catalogue NavRepServer – NavRepClient2";
CM_ SG_ 978 CnvtTopRngOpen_B_Stat "Signal not transmitted on gas and HEV variants.";
CM_ SG_ 978 CnvtTopRngClose_B_Stat "Signal not transmitted on gas and HEV variants.";
CM_ SG_ 717 DSPAMP_RDISP_WORD_Rx "Object:BezelDiagnostics.DSP_Bezel_Diag_Data";
CM_ SG_ 719 MyKeySrvr_Clnt_Word_Rx "Object.RepSrv_RepClient_WORD_Rx";
CM_ SG_ 745 ECG_APIM_Word_Tx "Tx by HS3 APIM";
CM_ SG_ 1185 TCU_MC_WORD_Rx "Tx by HS3 APIM";
CM_ SG_ 546 Prompt_Directionality "Object.AlertMethod. SYNC_Alerts

";
CM_ SG_ 546 Audible_Beep "Object.AlertMethod. SYNC_Alerts";
CM_ SG_ 546 Alert_Chan "Object.AlertMethod. SYNC_Alerts
";
CM_ SG_ 1232 AHU_EnsembleName_St "Object Configuration Management.EnsembleName_St";
CM_ SG_ 1232 AHU_AutoConfigOcc_Shakr "Object: AudioSettings.AHU_AutoConFigOcc_Shaker";
CM_ SG_ 1232 AHU_AutoConfigOcc_Rear "Object:AudioSettings.AHU_AutoConfigOcc_Rear";
CM_ SG_ 1232 AHU_AutoConfigOcc_Front "Object: AudioSettings. AHU_AutoConfigOcc_Front";
CM_ SG_ 1232 AHU_AutoConfigOcc_Drvr "Object:AudioSettings.AHU_AutoConfigOcc_Driver";
CM_ SG_ 1232 AHU_AutoConfigOcc_Cnvrt "AHU_AutoConfigOcc_Convertible ";
CM_ SG_ 1232 AHU_AutoConfigOcc_Allst "Object: AudioSettings. AHU_AutoConfigOcc_AllSeats";
CM_ SG_ 1232 ACU_DigitalRadio_St "Object Configuration Management.ACU_DigitalRadio";
CM_ SG_ 1232 ACU_Configuration "Object Configuration Management.ACU_Configuration";
CM_ SG_ 1232 ACU_MediaPlayer_St "Object Configuration Management.ACU_MediaPlayer

$1: MusicCassettePlayer is handled as Medialess in MFD setup";
CM_ SG_ 870 PolicePurstMde_B_Stat "Normal SED EP 1000. Using 100FP can result  in100ms w/c latency.  Latency accepted for feature/function by SME since existing FGW msg.";
CM_ SG_ 684 MC_RDISP_WORD_Rx "Communicates ConsHistGraph_St, which includes data to populate the consumption history display.";
CM_ SG_ 791 ChargeProfIDPref_Rq "Object:ChargeProfIDPref_St
Status of the charge preference for the current Charge Profile.";
CM_ SG_ 358 HiElPwInhbt_B_Stat "Signal not transmitted on HEV programs";
CM_ SG_ 358 AutoStopPtDelta_I_Est "Signal not transmitted on vehicles that do not have autostop/stop-start feature.";
CM_ SG_ 360 GsmSrvcRqd_B_Rq "Signal not transmitted on vehicles that do not have shift by wire.";
CM_ SG_ 360 TrnTrcmPwmSig_D_Actl "Signal not transmitted on vehicles that do not have shift by wire.";
CM_ SG_ 360 TrnGearPwmFalt_B_Actl "Signal not transmitted on vehicles that do not have shift by wire.";
CM_ SG_ 360 GearButtnStuck_B_Actl "Signal not transmitted on vehicles that do not have shift by wire.";
CM_ BO_ 134 "FCDIM APIM TX";
CM_ BO_ 559 "APIM Tx";
CM_ BO_ 558 "APIM Tx";
CM_ BO_ 846 "APIM Tx";
BA_DEF_ BO_  "FrameRouting" STRING ;
BA_DEF_ BO_  "NetworkInitialization" ENUM  "No","Yes";
BA_DEF_ BO_  "GenMsgStartDelayTime" INT 0 10000;
BA_DEF_ BO_  "GenMsgNrOfRepetition" INT 0 100;
BA_DEF_ BO_  "GenMsgDelayTime" INT 0 1000;
BA_DEF_ BO_  "GenMsgCycleTime" INT 0 100000;
BA_DEF_ BO_  "GenMsgSendType" ENUM  "FixedPeriodic","Event","EnabledPeriodic","NotUsed","NotUsed","EventPeriodic","NotUsed","NotUsed","NoMsgSendType";
BA_DEF_ SG_  "U_P702_MY2024_Tx" ENUM  "No","Yes";
BA_DEF_ SG_  "U_V710_MY2023_Tx" ENUM  "No","Yes";
BA_DEF_ SG_  "U_CDX74X_MY2024_Tx" ENUM  "No","Yes";
BA_DEF_ SG_  "U_CDX707_MY2023_Tx" ENUM  "No","Yes";
BA_DEF_ SG_  "U_P708_MY2023_Tx" ENUM  "No","Yes";
BA_DEF_ SG_  "U_V713AV_MY2022_Tx" ENUM  "No","Yes";
BA_DEF_ SG_  "U_V713N_MY2022_Tx" ENUM  "No","Yes";
BA_DEF_ SG_  "ECGUsedTxSignal" ENUM  "No","Yes";
BA_DEF_ SG_  "U_P702_MY2024_Rx" ENUM  "No","Yes";
BA_DEF_ SG_  "U_V710_MY2023_Rx" ENUM  "No","Yes";
BA_DEF_ SG_  "U_CDX74X_MY2024_Rx" ENUM  "No","Yes";
BA_DEF_ SG_  "U_CDX707_MY2023_Rx" ENUM  "No","Yes";
BA_DEF_ SG_  "U_P708_MY2023_Rx" ENUM  "No","Yes";
BA_DEF_ SG_  "U_V713AV_MY2022_Rx" ENUM  "No","Yes";
BA_DEF_ SG_  "U_V713N_MY2022_Rx" ENUM  "No","Yes";
BA_DEF_ SG_  "ECGUsedRxSignal" ENUM  "No","Yes";
BA_DEF_ SG_  "UsedOnPgmDBC" ENUM  "No","Yes";
BA_DEF_ SG_  "ContentDependant" ENUM  "No","Yes";
BA_DEF_ SG_  "GenSigStartValue" HEX 0 268435455;
BA_DEF_ SG_  "MetaData" ENUM  "No","Yes";
BA_DEF_ SG_  "WakeupSignal" ENUM  "No","Yes";
BA_DEF_ SG_  "GenSigInactiveValue" INT 0 100000;
BA_DEF_ SG_  "GenSigSendType" ENUM  "Cyclic","OnWrite","vector_leerstring","OnChange","vector_leerstring","IfActive","vector_leerstring","NoSigSendType";
BA_DEF_ BO_  "TpTxIndex" INT 0 536870911;
BA_DEF_ BO_  "OvtpPushApplication" ENUM  "FALSE","TRUE";
BA_DEF_ BO_  "SCP_FreshnessValueLength" INT 0 512;
BA_DEF_ BO_  "SCP_DataId" INT 0 17663;
BA_DEF_ BO_  "SCP_FreshnessValueTxLength" INT 0 512;
BA_DEF_ BO_  "SCP_AuthInfoTxLength" INT 0 512;
BA_DEF_ BO_  "SC_Message" ENUM  "No","Yes";
BA_DEF_ BO_  "GenMsgRoutingTimeoutTime" INT 0 5000;
BA_DEF_ BO_  "MessageGateway" ENUM  "No","Yes";
BA_DEF_ BO_  "NmAsrMessage" ENUM  "No","Yes";
BA_DEF_ BO_  "DiagState" ENUM  "No","Yes";
BA_DEF_ BO_  "DiagRequest" ENUM  "No","Yes";
BA_DEF_ BO_  "DiagResponse" ENUM  "No","Yes";
BA_DEF_ BO_  "NmMessage" ENUM  "No","Yes";
BA_DEF_ BO_  "GenMsgILSupport" ENUM  "No","Yes";
BA_DEF_DEF_  "FrameRouting" "";
BA_DEF_DEF_  "NetworkInitialization" "Yes";
BA_DEF_DEF_  "GenMsgStartDelayTime" 0;
BA_DEF_DEF_  "GenMsgNrOfRepetition" 1;
BA_DEF_DEF_  "GenMsgDelayTime" 20;
BA_DEF_DEF_  "GenMsgCycleTime" 0;
BA_DEF_DEF_  "GenMsgSendType" "NoMsgSendType";
BA_DEF_DEF_  "U_P702_MY2024_Tx" "No";
BA_DEF_DEF_  "U_V710_MY2023_Tx" "No";
BA_DEF_DEF_  "U_CDX74X_MY2024_Tx" "No";
BA_DEF_DEF_  "U_CDX707_MY2023_Tx" "No";
BA_DEF_DEF_  "U_P708_MY2023_Tx" "No";
BA_DEF_DEF_  "U_V713AV_MY2022_Tx" "No";
BA_DEF_DEF_  "U_V713N_MY2022_Tx" "No";
BA_DEF_DEF_  "ECGUsedTxSignal" "No";
BA_DEF_DEF_  "U_P702_MY2024_Rx" "No";
BA_DEF_DEF_  "U_V710_MY2023_Rx" "No";
BA_DEF_DEF_  "U_CDX74X_MY2024_Rx" "No";
BA_DEF_DEF_  "U_CDX707_MY2023_Rx" "No";
BA_DEF_DEF_  "U_P708_MY2023_Rx" "No";
BA_DEF_DEF_  "U_V713AV_MY2022_Rx" "No";
BA_DEF_DEF_  "U_V713N_MY2022_Rx" "No";
BA_DEF_DEF_  "ECGUsedRxSignal" "No";
BA_DEF_DEF_  "UsedOnPgmDBC" "Yes";
BA_DEF_DEF_  "ContentDependant" "No";
BA_DEF_DEF_  "GenSigStartValue" 0;
BA_DEF_DEF_  "MetaData" "No";
BA_DEF_DEF_  "WakeupSignal" "No";
BA_DEF_DEF_  "GenSigInactiveValue" 0;
BA_DEF_DEF_  "GenSigSendType" "NoSigSendType";
BA_DEF_DEF_  "TpTxIndex" 0;
BA_DEF_DEF_  "OvtpPushApplication" "FALSE";
BA_DEF_DEF_  "SCP_FreshnessValueLength" 64;
BA_DEF_DEF_  "SCP_DataId" 0;
BA_DEF_DEF_  "SCP_FreshnessValueTxLength" 11;
BA_DEF_DEF_  "SCP_AuthInfoTxLength" 53;
BA_DEF_DEF_  "SC_Message" "No";
BA_DEF_DEF_  "GenMsgRoutingTimeoutTime" 0;
BA_DEF_DEF_  "MessageGateway" "No";
BA_DEF_DEF_  "NmAsrMessage" "No";
BA_DEF_DEF_  "DiagState" "No";
BA_DEF_DEF_  "DiagRequest" "No";
BA_DEF_DEF_  "DiagResponse" "No";
BA_DEF_DEF_  "NmMessage" "No";
BA_DEF_DEF_  "GenMsgILSupport" "Yes";
BA_ "GenMsgSendType" BO_ 811 5;
BA_ "GenMsgCycleTime" BO_ 811 1000;
BA_ "GenMsgSendType" BO_ 543 0;
BA_ "GenMsgCycleTime" BO_ 543 1000;
BA_ "GenMsgSendType" BO_ 563 5;
BA_ "GenMsgCycleTime" BO_ 563 1000;
BA_ "TpTxIndex" BO_ 587 44;
BA_ "TpTxIndex" BO_ 579 44;
BA_ "TpTxIndex" BO_ 585 42;
BA_ "TpTxIndex" BO_ 586 43;
BA_ "TpTxIndex" BO_ 578 43;
BA_ "TpTxIndex" BO_ 577 42;
BA_ "FrameRouting" BO_ 978 "MS1_CAN,0x3D2;";
BA_ "TpTxIndex" BO_ 717 25;
BA_ "TpTxIndex" BO_ 719 24;
BA_ "TpTxIndex" BO_ 589 30;
BA_ "GenMsgSendType" BO_ 1146 0;
BA_ "GenMsgCycleTime" BO_ 1146 50;
BA_ "TpTxIndex" BO_ 737 53;
BA_ "TpTxIndex" BO_ 745 53;
BA_ "TpTxIndex" BO_ 1195 52;
BA_ "TpTxIndex" BO_ 1185 51;
BA_ "NetworkInitialization" BO_ 1185 0;
BA_ "GenMsgILSupport" BO_ 1435 0;
BA_ "NmAsrMessage" BO_ 1435 1;
BA_ "GenMsgSendType" BO_ 1435 0;
BA_ "GenMsgCycleTime" BO_ 1435 1000;
BA_ "NetworkInitialization" BO_ 1435 0;
BA_ "GenMsgSendType" BO_ 1109 5;
BA_ "GenMsgCycleTime" BO_ 1109 100;
BA_ "GenMsgILSupport" BO_ 1945 0;
BA_ "DiagResponse" BO_ 1945 1;
BA_ "GenMsgSendType" BO_ 1945 1;
BA_ "GenMsgDelayTime" BO_ 1945 0;
BA_ "NetworkInitialization" BO_ 1945 0;
BA_ "GenMsgILSupport" BO_ 1937 0;
BA_ "DiagRequest" BO_ 1937 1;
BA_ "GenMsgSendType" BO_ 1937 1;
BA_ "GenMsgDelayTime" BO_ 1937 0;
BA_ "NetworkInitialization" BO_ 1937 0;
BA_ "GenMsgSendType" BO_ 557 5;
BA_ "GenMsgCycleTime" BO_ 557 1000;
BA_ "TpTxIndex" BO_ 718 26;
BA_ "GenMsgSendType" BO_ 140 5;
BA_ "GenMsgCycleTime" BO_ 140 1000;
BA_ "GenMsgSendType" BO_ 546 5;
BA_ "GenMsgCycleTime" BO_ 546 1000;
BA_ "FrameRouting" BO_ 1186 "FD1_CAN,0x4A2;";
BA_ "FrameRouting" BO_ 1138 "FD1_CAN,0x472;";
BA_ "FrameRouting" BO_ 1139 "FD1_CAN,0x473;";
BA_ "FrameRouting" BO_ 1145 "FD1_CAN,0x352;";
BA_ "GenMsgSendType" BO_ 1232 0;
BA_ "GenMsgCycleTime" BO_ 1232 1000;
BA_ "FrameRouting" BO_ 1141 "FD1_CAN,0x475;";
BA_ "FrameRouting" BO_ 1140 "FD1_CAN,0x474;";
BA_ "FrameRouting" BO_ 873 "FD1_CAN,0x369;";
BA_ "FrameRouting" BO_ 871 "FD1_CAN,0x367;";
BA_ "FrameRouting" BO_ 870 "FD1_CAN,0x366;";
BA_ "FrameRouting" BO_ 869 "FD1_CAN,0x365;";
BA_ "FrameRouting" BO_ 786 "FD1_CAN,0x312;";
BA_ "FrameRouting" BO_ 1095 "FD1_CAN,0x447;";
BA_ "TpTxIndex" BO_ 684 29;
BA_ "FrameRouting" BO_ 872 "FD1_CAN,0x368;";
BA_ "GenMsgSendType" BO_ 791 5;
BA_ "GenMsgCycleTime" BO_ 791 1000;
BA_ "FrameRouting" BO_ 358 "FD1_CAN,0x166;";
BA_ "FrameRouting" BO_ 945 "FD1_CAN,0x3B1;";
BA_ "GenMsgSendType" BO_ 740 5;
BA_ "GenMsgCycleTime" BO_ 740 1000;
BA_ "FrameRouting" BO_ 1055 "FD1_CAN,0x41F;";
BA_ "FrameRouting" BO_ 360 "FD3_CAN,0x168;";
BA_ "GenMsgILSupport" BO_ 1839 0;
BA_ "DiagResponse" BO_ 1839 1;
BA_ "GenMsgSendType" BO_ 1839 1;
BA_ "GenMsgDelayTime" BO_ 1839 0;
BA_ "NetworkInitialization" BO_ 1839 0;
BA_ "GenMsgILSupport" BO_ 1831 0;
BA_ "DiagRequest" BO_ 1831 1;
BA_ "GenMsgSendType" BO_ 1831 1;
BA_ "GenMsgDelayTime" BO_ 1831 0;
BA_ "NetworkInitialization" BO_ 1831 0;
BA_ "FrameRouting" BO_ 1056 "FD1_CAN,0x420;";
BA_ "MessageGateway" BO_ 1060 1;
BA_ "GenMsgRoutingTimeoutTime" BO_ 1060 300;
BA_ "GenMsgSendType" BO_ 1060 5;
BA_ "GenMsgCycleTime" BO_ 1060 1000;
BA_ "FrameRouting" BO_ 132 "FD1_CAN,0x84;";
BA_ "GenMsgSendType" BO_ 135 1;
BA_ "NetworkInitialization" BO_ 135 0;
BA_ "GenMsgSendType" BO_ 134 1;
BA_ "GenMsgSendType" BO_ 559 1;
BA_ "GenMsgSendType" BO_ 558 1;
BA_ "FrameRouting" BO_ 939 "FD1_CAN,0x3AB;FD3_CAN,0x3AB";
BA_ "FrameRouting" BO_ 938 "FD1_CAN,0x3AA;FD3_CAN,0x3AA";
BA_ "FrameRouting" BO_ 952 "FD1_CAN,0x3B8;";
BA_ "FrameRouting" BO_ 845 "MS1_CAN,0x34D;";
BA_ "FrameRouting" BO_ 1137 "FD1_CAN,0x471;";
BA_ "FrameRouting" BO_ 844 "MS1_CAN,0x34C;";
BA_ "FrameRouting" BO_ 843 "MS1_CAN,0x34B;";
BA_ "FrameRouting" BO_ 842 "MS1_CAN,0x34A;";
BA_ "GenMsgSendType" BO_ 846 5;
BA_ "GenMsgCycleTime" BO_ 846 1000;
BA_ "GenSigSendType" SG_ 811 ExtLghtDsply_D_Stat 3;
BA_ "ECGUsedRxSignal" SG_ 811 ExtLghtDsply_D_Stat 1;
BA_ "U_V713N_MY2022_Rx" SG_ 811 ExtLghtDsply_D_Stat 1;
BA_ "U_V713AV_MY2022_Rx" SG_ 811 ExtLghtDsply_D_Stat 1;
BA_ "U_P708_MY2023_Rx" SG_ 811 ExtLghtDsply_D_Stat 1;
BA_ "U_CDX74X_MY2024_Rx" SG_ 811 ExtLghtDsply_D_Stat 1;
BA_ "U_V710_MY2023_Rx" SG_ 811 ExtLghtDsply_D_Stat 1;
BA_ "U_V710_MY2023_Tx" SG_ 811 ExtLghtDsply_D_Stat 1;
BA_ "U_P708_MY2023_Tx" SG_ 811 ExtLghtDsply_D_Stat 1;
BA_ "U_P702_MY2024_Tx" SG_ 811 ExtLghtDsply_D_Stat 1;
BA_ "GenSigSendType" SG_ 811 LongTermReset_B_RqMnu 3;
BA_ "U_V710_MY2023_Tx" SG_ 811 LongTermReset_B_RqMnu 1;
BA_ "U_P708_MY2023_Tx" SG_ 811 LongTermReset_B_RqMnu 1;
BA_ "U_P702_MY2024_Tx" SG_ 811 LongTermReset_B_RqMnu 1;
BA_ "GenSigSendType" SG_ 811 SpeedoMajorUnit_D_Confg 3;
BA_ "U_V710_MY2023_Tx" SG_ 811 SpeedoMajorUnit_D_Confg 1;
BA_ "U_P708_MY2023_Tx" SG_ 811 SpeedoMajorUnit_D_Confg 1;
BA_ "U_P702_MY2024_Tx" SG_ 811 SpeedoMajorUnit_D_Confg 1;
BA_ "GenSigStartValue" SG_ 811 ScMnSoc_Pc_RqMnu 126;
BA_ "U_V710_MY2023_Tx" SG_ 811 ScMnSoc_Pc_RqMnu 1;
BA_ "U_P708_MY2023_Tx" SG_ 811 ScMnSoc_Pc_RqMnu 1;
BA_ "U_P702_MY2024_Tx" SG_ 811 ScMnSoc_Pc_RqMnu 1;
BA_ "GenSigSendType" SG_ 811 ScEnbl_D_RqMnu 3;
BA_ "U_V710_MY2023_Tx" SG_ 811 ScEnbl_D_RqMnu 1;
BA_ "U_P708_MY2023_Tx" SG_ 811 ScEnbl_D_RqMnu 1;
BA_ "U_P702_MY2024_Tx" SG_ 811 ScEnbl_D_RqMnu 1;
BA_ "GenSigSendType" SG_ 811 OnePdlDrvButtn_B_Stat 3;
BA_ "U_V710_MY2023_Tx" SG_ 811 OnePdlDrvButtn_B_Stat 1;
BA_ "U_P708_MY2023_Tx" SG_ 811 OnePdlDrvButtn_B_Stat 1;
BA_ "U_P702_MY2024_Tx" SG_ 811 OnePdlDrvButtn_B_Stat 1;
BA_ "GenSigSendType" SG_ 811 OnePdlDrvButtn_B_Falt 3;
BA_ "U_V710_MY2023_Tx" SG_ 811 OnePdlDrvButtn_B_Falt 1;
BA_ "U_P708_MY2023_Tx" SG_ 811 OnePdlDrvButtn_B_Falt 1;
BA_ "U_P702_MY2024_Tx" SG_ 811 OnePdlDrvButtn_B_Falt 1;
BA_ "GenSigStartValue" SG_ 811 GoTEditMnte_T_RqMnu 14;
BA_ "GenSigSendType" SG_ 811 GoTEditMnte_T_RqMnu 3;
BA_ "ECGUsedRxSignal" SG_ 811 GoTEditMnte_T_RqMnu 1;
BA_ "U_V713N_MY2022_Rx" SG_ 811 GoTEditMnte_T_RqMnu 1;
BA_ "U_V713AV_MY2022_Rx" SG_ 811 GoTEditMnte_T_RqMnu 1;
BA_ "U_P708_MY2023_Rx" SG_ 811 GoTEditMnte_T_RqMnu 1;
BA_ "U_CDX74X_MY2024_Rx" SG_ 811 GoTEditMnte_T_RqMnu 1;
BA_ "U_V710_MY2023_Rx" SG_ 811 GoTEditMnte_T_RqMnu 1;
BA_ "U_V710_MY2023_Tx" SG_ 811 GoTEditMnte_T_RqMnu 1;
BA_ "U_P708_MY2023_Tx" SG_ 811 GoTEditMnte_T_RqMnu 1;
BA_ "U_P702_MY2024_Tx" SG_ 811 GoTEditMnte_T_RqMnu 1;
BA_ "GenSigStartValue" SG_ 811 GoTEditHr_T_RqMnu 30;
BA_ "GenSigSendType" SG_ 811 GoTEditHr_T_RqMnu 3;
BA_ "ECGUsedRxSignal" SG_ 811 GoTEditHr_T_RqMnu 1;
BA_ "U_V713N_MY2022_Rx" SG_ 811 GoTEditHr_T_RqMnu 1;
BA_ "U_V713AV_MY2022_Rx" SG_ 811 GoTEditHr_T_RqMnu 1;
BA_ "U_P708_MY2023_Rx" SG_ 811 GoTEditHr_T_RqMnu 1;
BA_ "U_CDX74X_MY2024_Rx" SG_ 811 GoTEditHr_T_RqMnu 1;
BA_ "U_V710_MY2023_Rx" SG_ 811 GoTEditHr_T_RqMnu 1;
BA_ "U_V710_MY2023_Tx" SG_ 811 GoTEditHr_T_RqMnu 1;
BA_ "U_P708_MY2023_Tx" SG_ 811 GoTEditHr_T_RqMnu 1;
BA_ "U_P702_MY2024_Tx" SG_ 811 GoTEditHr_T_RqMnu 1;
BA_ "WakeupSignal" SG_ 811 ExtLghtRight_D_RqMnu 1;
BA_ "GenSigSendType" SG_ 811 ExtLghtRight_D_RqMnu 3;
BA_ "U_V710_MY2023_Tx" SG_ 811 ExtLghtRight_D_RqMnu 1;
BA_ "U_P708_MY2023_Tx" SG_ 811 ExtLghtRight_D_RqMnu 1;
BA_ "U_P702_MY2024_Tx" SG_ 811 ExtLghtRight_D_RqMnu 1;
BA_ "WakeupSignal" SG_ 811 AutoLghtOvrrd_B_RqDrv 1;
BA_ "GenSigSendType" SG_ 811 AutoLghtOvrrd_B_RqDrv 3;
BA_ "U_V710_MY2023_Tx" SG_ 811 AutoLghtOvrrd_B_RqDrv 1;
BA_ "U_P708_MY2023_Tx" SG_ 811 AutoLghtOvrrd_B_RqDrv 1;
BA_ "U_P702_MY2024_Tx" SG_ 811 AutoLghtOvrrd_B_RqDrv 1;
BA_ "WakeupSignal" SG_ 811 TrnkFrontRleas_No_RqMnu 1;
BA_ "GenSigSendType" SG_ 811 TrnkFrontRleas_No_RqMnu 3;
BA_ "U_V710_MY2023_Tx" SG_ 811 TrnkFrontRleas_No_RqMnu 1;
BA_ "U_P708_MY2023_Tx" SG_ 811 TrnkFrontRleas_No_RqMnu 1;
BA_ "U_P702_MY2024_Tx" SG_ 811 TrnkFrontRleas_No_RqMnu 1;
BA_ "WakeupSignal" SG_ 811 BecRleas_No_RqMnu 1;
BA_ "GenSigSendType" SG_ 811 BecRleas_No_RqMnu 3;
BA_ "U_V710_MY2023_Tx" SG_ 811 BecRleas_No_RqMnu 1;
BA_ "U_P708_MY2023_Tx" SG_ 811 BecRleas_No_RqMnu 1;
BA_ "U_P702_MY2024_Tx" SG_ 811 BecRleas_No_RqMnu 1;
BA_ "WakeupSignal" SG_ 811 ExtLghtRear_D_RqMnu 1;
BA_ "GenSigSendType" SG_ 811 ExtLghtRear_D_RqMnu 3;
BA_ "U_V710_MY2023_Tx" SG_ 811 ExtLghtRear_D_RqMnu 1;
BA_ "U_P708_MY2023_Tx" SG_ 811 ExtLghtRear_D_RqMnu 1;
BA_ "U_P702_MY2024_Tx" SG_ 811 ExtLghtRear_D_RqMnu 1;
BA_ "WakeupSignal" SG_ 811 ExtLghtLeft_D_RqMnu 1;
BA_ "GenSigSendType" SG_ 811 ExtLghtLeft_D_RqMnu 3;
BA_ "U_V710_MY2023_Tx" SG_ 811 ExtLghtLeft_D_RqMnu 1;
BA_ "U_P708_MY2023_Tx" SG_ 811 ExtLghtLeft_D_RqMnu 1;
BA_ "U_P702_MY2024_Tx" SG_ 811 ExtLghtLeft_D_RqMnu 1;
BA_ "WakeupSignal" SG_ 811 ExtLghtFront_D_RqMnu 1;
BA_ "GenSigSendType" SG_ 811 ExtLghtFront_D_RqMnu 3;
BA_ "U_V710_MY2023_Tx" SG_ 811 ExtLghtFront_D_RqMnu 1;
BA_ "U_P708_MY2023_Tx" SG_ 811 ExtLghtFront_D_RqMnu 1;
BA_ "U_P702_MY2024_Tx" SG_ 811 ExtLghtFront_D_RqMnu 1;
BA_ "GenSigStartValue" SG_ 811 DistToStopover_L_Actl 65535;
BA_ "ECGUsedRxSignal" SG_ 811 DistToStopover_L_Actl 1;
BA_ "U_V713N_MY2022_Rx" SG_ 811 DistToStopover_L_Actl 1;
BA_ "U_V713AV_MY2022_Rx" SG_ 811 DistToStopover_L_Actl 1;
BA_ "U_P708_MY2023_Rx" SG_ 811 DistToStopover_L_Actl 1;
BA_ "U_CDX74X_MY2024_Rx" SG_ 811 DistToStopover_L_Actl 1;
BA_ "U_V710_MY2023_Rx" SG_ 811 DistToStopover_L_Actl 1;
BA_ "U_V710_MY2023_Tx" SG_ 811 DistToStopover_L_Actl 1;
BA_ "U_P708_MY2023_Tx" SG_ 811 DistToStopover_L_Actl 1;
BA_ "U_P702_MY2024_Tx" SG_ 811 DistToStopover_L_Actl 1;
BA_ "GenSigSendType" SG_ 811 StopoverType_D_Stat 3;
BA_ "ECGUsedRxSignal" SG_ 811 StopoverType_D_Stat 1;
BA_ "U_V713AV_MY2022_Rx" SG_ 811 StopoverType_D_Stat 1;
BA_ "U_P708_MY2023_Rx" SG_ 811 StopoverType_D_Stat 1;
BA_ "U_CDX74X_MY2024_Rx" SG_ 811 StopoverType_D_Stat 1;
BA_ "U_V710_MY2023_Rx" SG_ 811 StopoverType_D_Stat 1;
BA_ "U_V710_MY2023_Tx" SG_ 811 StopoverType_D_Stat 1;
BA_ "U_P708_MY2023_Tx" SG_ 811 StopoverType_D_Stat 1;
BA_ "U_P702_MY2024_Tx" SG_ 811 StopoverType_D_Stat 1;
BA_ "ECGUsedRxSignal" SG_ 543 TeltalWarnData_No_Actl 1;
BA_ "U_V713N_MY2022_Rx" SG_ 543 TeltalWarnData_No_Actl 1;
BA_ "U_V713AV_MY2022_Rx" SG_ 543 TeltalWarnData_No_Actl 1;
BA_ "U_P708_MY2023_Rx" SG_ 543 TeltalWarnData_No_Actl 1;
BA_ "U_CDX74X_MY2024_Rx" SG_ 543 TeltalWarnData_No_Actl 1;
BA_ "U_V710_MY2023_Rx" SG_ 543 TeltalWarnData_No_Actl 1;
BA_ "U_V713N_MY2022_Tx" SG_ 543 TeltalWarnData_No_Actl 1;
BA_ "U_V713AV_MY2022_Tx" SG_ 543 TeltalWarnData_No_Actl 1;
BA_ "U_P708_MY2023_Tx" SG_ 543 TeltalWarnData_No_Actl 1;
BA_ "U_V710_MY2023_Tx" SG_ 543 TeltalWarnData_No_Actl 1;
BA_ "U_P702_MY2024_Tx" SG_ 543 TeltalWarnData_No_Actl 1;
BA_ "GenSigSendType" SG_ 563 VgfZone_D_Stat 3;
BA_ "ECGUsedTxSignal" SG_ 563 VgfZone_D_Stat 1;
BA_ "GenSigSendType" SG_ 563 BattChrgStrtStop_D2_Rq 3;
BA_ "ECGUsedTxSignal" SG_ 563 BattChrgStrtStop_D2_Rq 1;
BA_ "U_CDX74X_MY2024_Tx" SG_ 563 BattChrgStrtStop_D2_Rq 1;
BA_ "U_V710_MY2023_Tx" SG_ 563 BattChrgStrtStop_D2_Rq 1;
BA_ "WakeupSignal" SG_ 563 NtfyDrvTrgtDist_L2_Rq 1;
BA_ "GenSigStartValue" SG_ 563 NtfyDrvTrgtDist_L2_Rq 8190;
BA_ "GenSigSendType" SG_ 563 NtfyDrvTrgtDist_L2_Rq 3;
BA_ "ECGUsedTxSignal" SG_ 563 NtfyDrvTrgtDist_L2_Rq 1;
BA_ "U_CDX74X_MY2024_Tx" SG_ 563 NtfyDrvTrgtDist_L2_Rq 1;
BA_ "U_V710_MY2023_Tx" SG_ 563 NtfyDrvTrgtDist_L2_Rq 1;
BA_ "GenSigStartValue" SG_ 563 GridSrvc01_D_RqCld 2;
BA_ "GenSigSendType" SG_ 563 GridSrvc01_D_RqCld 3;
BA_ "U_V710_MY2023_Rx" SG_ 563 GridSrvc01_D_RqCld 1;
BA_ "U_P708_MY2023_Rx" SG_ 563 GridSrvc01_D_RqCld 1;
BA_ "U_P702_MY2024_Rx" SG_ 563 GridSrvc01_D_RqCld 1;
BA_ "ECGUsedTxSignal" SG_ 563 GridSrvc01_D_RqCld 1;
BA_ "U_P708_MY2023_Tx" SG_ 563 GridSrvc01_D_RqCld 1;
BA_ "U_CDX74X_MY2024_Tx" SG_ 563 GridSrvc01_D_RqCld 1;
BA_ "U_V710_MY2023_Tx" SG_ 563 GridSrvc01_D_RqCld 1;
BA_ "GenSigSendType" SG_ 563 DrvBhavWarn_B_Rq 3;
BA_ "U_V713AV_MY2022_Rx" SG_ 563 DrvBhavWarn_B_Rq 1;
BA_ "U_P708_MY2023_Rx" SG_ 563 DrvBhavWarn_B_Rq 1;
BA_ "U_V710_MY2023_Rx" SG_ 563 DrvBhavWarn_B_Rq 1;
BA_ "U_V713N_MY2022_Rx" SG_ 563 DrvBhavWarn_B_Rq 1;
BA_ "U_P702_MY2024_Rx" SG_ 563 DrvBhavWarn_B_Rq 1;
BA_ "ECGUsedTxSignal" SG_ 563 DrvBhavWarn_B_Rq 1;
BA_ "U_V713N_MY2022_Tx" SG_ 563 DrvBhavWarn_B_Rq 1;
BA_ "U_V713AV_MY2022_Tx" SG_ 563 DrvBhavWarn_B_Rq 1;
BA_ "U_P708_MY2023_Tx" SG_ 563 DrvBhavWarn_B_Rq 1;
BA_ "U_CDX74X_MY2024_Tx" SG_ 563 DrvBhavWarn_B_Rq 1;
BA_ "U_V710_MY2023_Tx" SG_ 563 DrvBhavWarn_B_Rq 1;
BA_ "GenSigSendType" SG_ 563 BattChrgStrtStop_D_Rq 3;
BA_ "ECGUsedTxSignal" SG_ 563 BattChrgStrtStop_D_Rq 1;
BA_ "U_V713N_MY2022_Tx" SG_ 563 BattChrgStrtStop_D_Rq 1;
BA_ "U_V713AV_MY2022_Tx" SG_ 563 BattChrgStrtStop_D_Rq 1;
BA_ "U_P708_MY2023_Tx" SG_ 563 BattChrgStrtStop_D_Rq 1;
BA_ "U_CDX74X_MY2024_Tx" SG_ 563 BattChrgStrtStop_D_Rq 1;
BA_ "U_V710_MY2023_Tx" SG_ 563 BattChrgStrtStop_D_Rq 1;
BA_ "GenSigSendType" SG_ 563 DrvBhavAudioAlrt_D_Rq 3;
BA_ "U_V710_MY2023_Rx" SG_ 563 DrvBhavAudioAlrt_D_Rq 1;
BA_ "U_P708_MY2023_Rx" SG_ 563 DrvBhavAudioAlrt_D_Rq 1;
BA_ "U_P702_MY2024_Rx" SG_ 563 DrvBhavAudioAlrt_D_Rq 1;
BA_ "ECGUsedTxSignal" SG_ 563 DrvBhavAudioAlrt_D_Rq 1;
BA_ "U_P708_MY2023_Tx" SG_ 563 DrvBhavAudioAlrt_D_Rq 1;
BA_ "U_CDX74X_MY2024_Tx" SG_ 563 DrvBhavAudioAlrt_D_Rq 1;
BA_ "U_V710_MY2023_Tx" SG_ 563 DrvBhavAudioAlrt_D_Rq 1;
BA_ "GenSigSendType" SG_ 563 OfbChrgSetSync_D_Rq 3;
BA_ "U_V710_MY2023_Rx" SG_ 563 OfbChrgSetSync_D_Rq 1;
BA_ "U_P708_MY2023_Rx" SG_ 563 OfbChrgSetSync_D_Rq 1;
BA_ "U_P702_MY2024_Rx" SG_ 563 OfbChrgSetSync_D_Rq 1;
BA_ "ECGUsedTxSignal" SG_ 563 OfbChrgSetSync_D_Rq 1;
BA_ "U_V713N_MY2022_Tx" SG_ 563 OfbChrgSetSync_D_Rq 1;
BA_ "U_V713AV_MY2022_Tx" SG_ 563 OfbChrgSetSync_D_Rq 1;
BA_ "GenSigSendType" SG_ 563 KeyOffPwMde_D_Stat 3;
BA_ "U_V710_MY2023_Rx" SG_ 563 KeyOffPwMde_D_Stat 1;
BA_ "U_P708_MY2023_Rx" SG_ 563 KeyOffPwMde_D_Stat 1;
BA_ "U_P702_MY2024_Rx" SG_ 563 KeyOffPwMde_D_Stat 1;
BA_ "ECGUsedTxSignal" SG_ 563 KeyOffPwMde_D_Stat 1;
BA_ "U_V713N_MY2022_Tx" SG_ 563 KeyOffPwMde_D_Stat 1;
BA_ "U_V713AV_MY2022_Tx" SG_ 563 KeyOffPwMde_D_Stat 1;
BA_ "U_P708_MY2023_Tx" SG_ 563 KeyOffPwMde_D_Stat 1;
BA_ "U_CDX74X_MY2024_Tx" SG_ 563 KeyOffPwMde_D_Stat 1;
BA_ "U_V710_MY2023_Tx" SG_ 563 KeyOffPwMde_D_Stat 1;
BA_ "GenSigSendType" SG_ 563 ModemReset_D_Stat 3;
BA_ "U_V713N_MY2022_Rx" SG_ 563 ModemReset_D_Stat 1;
BA_ "U_V713AV_MY2022_Rx" SG_ 563 ModemReset_D_Stat 1;
BA_ "U_P708_MY2023_Rx" SG_ 563 ModemReset_D_Stat 1;
BA_ "U_V710_MY2023_Rx" SG_ 563 ModemReset_D_Stat 1;
BA_ "U_P702_MY2024_Rx" SG_ 563 ModemReset_D_Stat 1;
BA_ "ECGUsedTxSignal" SG_ 563 ModemReset_D_Stat 1;
BA_ "U_V713N_MY2022_Tx" SG_ 563 ModemReset_D_Stat 1;
BA_ "U_V713AV_MY2022_Tx" SG_ 563 ModemReset_D_Stat 1;
BA_ "U_P708_MY2023_Tx" SG_ 563 ModemReset_D_Stat 1;
BA_ "U_CDX74X_MY2024_Tx" SG_ 563 ModemReset_D_Stat 1;
BA_ "U_V710_MY2023_Tx" SG_ 563 ModemReset_D_Stat 1;
BA_ "GenSigSendType" SG_ 563 FactoryReset_St 3;
BA_ "U_V713N_MY2022_Rx" SG_ 563 FactoryReset_St 1;
BA_ "U_V713AV_MY2022_Rx" SG_ 563 FactoryReset_St 1;
BA_ "U_P708_MY2023_Rx" SG_ 563 FactoryReset_St 1;
BA_ "U_V710_MY2023_Rx" SG_ 563 FactoryReset_St 1;
BA_ "U_P702_MY2024_Rx" SG_ 563 FactoryReset_St 1;
BA_ "ECGUsedTxSignal" SG_ 563 FactoryReset_St 1;
BA_ "U_V713N_MY2022_Tx" SG_ 563 FactoryReset_St 1;
BA_ "U_V713AV_MY2022_Tx" SG_ 563 FactoryReset_St 1;
BA_ "U_P708_MY2023_Tx" SG_ 563 FactoryReset_St 1;
BA_ "U_CDX74X_MY2024_Tx" SG_ 563 FactoryReset_St 1;
BA_ "U_V710_MY2023_Tx" SG_ 563 FactoryReset_St 1;
BA_ "U_V713N_MY2022_Rx" SG_ 587 PHONE_RDISP2_WORD_Rx 1;
BA_ "U_V713AV_MY2022_Rx" SG_ 587 PHONE_RDISP2_WORD_Rx 1;
BA_ "U_P708_MY2023_Rx" SG_ 587 PHONE_RDISP2_WORD_Rx 1;
BA_ "U_V710_MY2023_Rx" SG_ 587 PHONE_RDISP2_WORD_Rx 1;
BA_ "U_P702_MY2024_Rx" SG_ 587 PHONE_RDISP2_WORD_Rx 1;
BA_ "U_P708_MY2023_Tx" SG_ 587 PHONE_RDISP2_WORD_Rx 1;
BA_ "U_P702_MY2024_Tx" SG_ 587 PHONE_RDISP2_WORD_Rx 1;
BA_ "U_P708_MY2023_Rx" SG_ 579 PHONE_RDISP2_WORD_Tx 1;
BA_ "U_P702_MY2024_Rx" SG_ 579 PHONE_RDISP2_WORD_Tx 1;
BA_ "U_V713N_MY2022_Tx" SG_ 579 PHONE_RDISP2_WORD_Tx 1;
BA_ "U_V713AV_MY2022_Tx" SG_ 579 PHONE_RDISP2_WORD_Tx 1;
BA_ "U_P708_MY2023_Tx" SG_ 579 PHONE_RDISP2_WORD_Tx 1;
BA_ "U_V710_MY2023_Tx" SG_ 579 PHONE_RDISP2_WORD_Tx 1;
BA_ "U_P702_MY2024_Tx" SG_ 579 PHONE_RDISP2_WORD_Tx 1;
BA_ "U_V710_MY2023_Rx" SG_ 585 NAV_RDISP2_WORD_Rx 1;
BA_ "U_P708_MY2023_Rx" SG_ 585 NAV_RDISP2_WORD_Rx 1;
BA_ "U_P702_MY2024_Rx" SG_ 585 NAV_RDISP2_WORD_Rx 1;
BA_ "U_P708_MY2023_Tx" SG_ 585 NAV_RDISP2_WORD_Rx 1;
BA_ "U_P702_MY2024_Tx" SG_ 585 NAV_RDISP2_WORD_Rx 1;
BA_ "U_V710_MY2023_Rx" SG_ 586 CONMP_RDISP2_WORD_Rx 1;
BA_ "U_P708_MY2023_Rx" SG_ 586 CONMP_RDISP2_WORD_Rx 1;
BA_ "U_P702_MY2024_Rx" SG_ 586 CONMP_RDISP2_WORD_Rx 1;
BA_ "U_P708_MY2023_Tx" SG_ 586 CONMP_RDISP2_WORD_Rx 1;
BA_ "U_P702_MY2024_Tx" SG_ 586 CONMP_RDISP2_WORD_Rx 1;
BA_ "U_P708_MY2023_Rx" SG_ 578 CONMP_RDISP2_WORD_Tx 1;
BA_ "U_P702_MY2024_Rx" SG_ 578 CONMP_RDISP2_WORD_Tx 1;
BA_ "U_V710_MY2023_Tx" SG_ 578 CONMP_RDISP2_WORD_Tx 1;
BA_ "U_P708_MY2023_Tx" SG_ 578 CONMP_RDISP2_WORD_Tx 1;
BA_ "U_P702_MY2024_Tx" SG_ 578 CONMP_RDISP2_WORD_Tx 1;
BA_ "U_P708_MY2023_Rx" SG_ 577 NAV_RDISP2_WORD_Tx 1;
BA_ "U_P702_MY2024_Rx" SG_ 577 NAV_RDISP2_WORD_Tx 1;
BA_ "U_V710_MY2023_Tx" SG_ 577 NAV_RDISP2_WORD_Tx 1;
BA_ "U_P708_MY2023_Tx" SG_ 577 NAV_RDISP2_WORD_Tx 1;
BA_ "U_P702_MY2024_Tx" SG_ 577 NAV_RDISP2_WORD_Tx 1;
BA_ "GenSigStartValue" SG_ 978 CnvtTopPos_D_Stat 7;
BA_ "MetaData" SG_ 978 CnvtTopComplt_No_Cnt 1;
BA_ "U_V710_MY2023_Rx" SG_ 717 DSPAMP_RDISP_WORD_Rx 1;
BA_ "U_V710_MY2023_Tx" SG_ 717 DSPAMP_RDISP_WORD_Rx 1;
BA_ "U_P708_MY2023_Tx" SG_ 717 DSPAMP_RDISP_WORD_Rx 1;
BA_ "U_P702_MY2024_Tx" SG_ 717 DSPAMP_RDISP_WORD_Rx 1;
BA_ "U_P708_MY2023_Tx" SG_ 719 MyKeySrvr_Clnt_Word_Rx 1;
BA_ "U_P708_MY2023_Tx" SG_ 589 TRAFFIC_RDISP_WORD_Rx 1;
BA_ "U_P708_MY2023_Tx" SG_ 1146 TrlrAidSwtch_D_RqDrv 1;
BA_ "U_P702_MY2024_Tx" SG_ 1146 TrlrAidSwtch_D_RqDrv 1;
BA_ "GenSigStartValue" SG_ 1146 TrlrAidCtl_U_RqDrv 4093;
BA_ "U_P708_MY2023_Tx" SG_ 1146 TrlrAidCtl_U_RqDrv 1;
BA_ "U_P702_MY2024_Tx" SG_ 1146 TrlrAidCtl_U_RqDrv 1;
BA_ "ECGUsedRxSignal" SG_ 737 APIM_ECG_Word_Tx 1;
BA_ "U_V713N_MY2022_Rx" SG_ 737 APIM_ECG_Word_Tx 1;
BA_ "U_V713AV_MY2022_Rx" SG_ 737 APIM_ECG_Word_Tx 1;
BA_ "U_P708_MY2023_Rx" SG_ 737 APIM_ECG_Word_Tx 1;
BA_ "U_CDX74X_MY2024_Rx" SG_ 737 APIM_ECG_Word_Tx 1;
BA_ "U_V710_MY2023_Rx" SG_ 737 APIM_ECG_Word_Tx 1;
BA_ "U_V710_MY2023_Tx" SG_ 737 APIM_ECG_Word_Tx 1;
BA_ "U_P708_MY2023_Tx" SG_ 737 APIM_ECG_Word_Tx 1;
BA_ "U_P702_MY2024_Tx" SG_ 737 APIM_ECG_Word_Tx 1;
BA_ "U_V710_MY2023_Rx" SG_ 745 ECG_APIM_Word_Tx 1;
BA_ "U_P708_MY2023_Rx" SG_ 745 ECG_APIM_Word_Tx 1;
BA_ "U_P702_MY2024_Rx" SG_ 745 ECG_APIM_Word_Tx 1;
BA_ "ECGUsedTxSignal" SG_ 745 ECG_APIM_Word_Tx 1;
BA_ "U_V713N_MY2022_Tx" SG_ 745 ECG_APIM_Word_Tx 1;
BA_ "U_V713AV_MY2022_Tx" SG_ 745 ECG_APIM_Word_Tx 1;
BA_ "U_P708_MY2023_Tx" SG_ 745 ECG_APIM_Word_Tx 1;
BA_ "U_CDX74X_MY2024_Tx" SG_ 745 ECG_APIM_Word_Tx 1;
BA_ "U_V710_MY2023_Tx" SG_ 745 ECG_APIM_Word_Tx 1;
BA_ "U_P708_MY2023_Tx" SG_ 1195 TCU_RDISP2_WORD_Rx 1;
BA_ "U_P702_MY2024_Tx" SG_ 1195 TCU_RDISP2_WORD_Rx 1;
BA_ "ECGUsedRxSignal" SG_ 1185 TCU_MC_WORD_Rx 1;
BA_ "U_CDX74X_MY2024_Rx" SG_ 1185 TCU_MC_WORD_Rx 1;
BA_ "U_V710_MY2023_Rx" SG_ 1185 TCU_MC_WORD_Rx 1;
BA_ "U_P702_MY2024_Tx" SG_ 1185 TCU_MC_WORD_Rx 1;
BA_ "U_V710_MY2023_Rx" SG_ 1435 HUD_AutoSarNMReserved1 1;
BA_ "U_P708_MY2023_Tx" SG_ 1435 HUD_AutoSarNMReserved1 1;
BA_ "U_P702_MY2024_Tx" SG_ 1435 HUD_AutoSarNMReserved1 1;
BA_ "GenSigStartValue" SG_ 1435 HUD_GWOnBoardTester 255;
BA_ "U_V710_MY2023_Rx" SG_ 1435 HUD_GWOnBoardTester 1;
BA_ "U_P708_MY2023_Tx" SG_ 1435 HUD_GWOnBoardTester 1;
BA_ "U_P702_MY2024_Tx" SG_ 1435 HUD_GWOnBoardTester 1;
BA_ "GenSigStartValue" SG_ 1435 HUD_GWNMProxy 255;
BA_ "U_V710_MY2023_Rx" SG_ 1435 HUD_GWNMProxy 1;
BA_ "U_P708_MY2023_Tx" SG_ 1435 HUD_GWNMProxy 1;
BA_ "U_P702_MY2024_Tx" SG_ 1435 HUD_GWNMProxy 1;
BA_ "GenSigStartValue" SG_ 1435 HUD_AutoSarNMReserved4 255;
BA_ "U_V710_MY2023_Rx" SG_ 1435 HUD_AutoSarNMReserved4 1;
BA_ "U_P708_MY2023_Tx" SG_ 1435 HUD_AutoSarNMReserved4 1;
BA_ "U_P702_MY2024_Tx" SG_ 1435 HUD_AutoSarNMReserved4 1;
BA_ "GenSigStartValue" SG_ 1435 HUD_AutoSarNMReserved3 255;
BA_ "U_V710_MY2023_Rx" SG_ 1435 HUD_AutoSarNMReserved3 1;
BA_ "U_P708_MY2023_Tx" SG_ 1435 HUD_AutoSarNMReserved3 1;
BA_ "U_P702_MY2024_Tx" SG_ 1435 HUD_AutoSarNMReserved3 1;
BA_ "GenSigStartValue" SG_ 1435 HUD_AutoSarNMReserved2 255;
BA_ "U_V710_MY2023_Rx" SG_ 1435 HUD_AutoSarNMReserved2 1;
BA_ "U_P708_MY2023_Tx" SG_ 1435 HUD_AutoSarNMReserved2 1;
BA_ "U_P702_MY2024_Tx" SG_ 1435 HUD_AutoSarNMReserved2 1;
BA_ "GenSigStartValue" SG_ 1435 HUD_AutoSarNMNodeId 155;
BA_ "U_V710_MY2023_Rx" SG_ 1435 HUD_AutoSarNMNodeId 1;
BA_ "U_P708_MY2023_Tx" SG_ 1435 HUD_AutoSarNMNodeId 1;
BA_ "U_P702_MY2024_Tx" SG_ 1435 HUD_AutoSarNMNodeId 1;
BA_ "U_V710_MY2023_Rx" SG_ 1435 HUD_AutoSarNMControl 1;
BA_ "U_P708_MY2023_Tx" SG_ 1435 HUD_AutoSarNMControl 1;
BA_ "U_P702_MY2024_Tx" SG_ 1435 HUD_AutoSarNMControl 1;
BA_ "GenSigSendType" SG_ 1109 eCallConfirmation 3;
BA_ "U_P708_MY2023_Rx" SG_ 1109 eCallConfirmation 1;
BA_ "U_V710_MY2023_Tx" SG_ 1109 eCallConfirmation 1;
BA_ "U_P708_MY2023_Tx" SG_ 1109 eCallConfirmation 1;
BA_ "U_P702_MY2024_Tx" SG_ 1109 eCallConfirmation 1;
BA_ "GenSigSendType" SG_ 1945 TesterPhysicalResTRM_ITRM 3;
BA_ "U_P708_MY2023_Tx" SG_ 1945 TesterPhysicalResTRM_ITRM 1;
BA_ "U_CDX707_MY2023_Tx" SG_ 1945 TesterPhysicalResTRM_ITRM 1;
BA_ "U_CDX74X_MY2024_Tx" SG_ 1945 TesterPhysicalResTRM_ITRM 1;
BA_ "U_V710_MY2023_Tx" SG_ 1945 TesterPhysicalResTRM_ITRM 1;
BA_ "U_P702_MY2024_Tx" SG_ 1945 TesterPhysicalResTRM_ITRM 1;
BA_ "GenSigSendType" SG_ 1937 TesterPhysicalReqTRM_ITRM 3;
BA_ "U_P708_MY2023_Rx" SG_ 1937 TesterPhysicalReqTRM_ITRM 1;
BA_ "U_CDX707_MY2023_Rx" SG_ 1937 TesterPhysicalReqTRM_ITRM 1;
BA_ "U_CDX74X_MY2024_Rx" SG_ 1937 TesterPhysicalReqTRM_ITRM 1;
BA_ "U_V710_MY2023_Rx" SG_ 1937 TesterPhysicalReqTRM_ITRM 1;
BA_ "U_P702_MY2024_Rx" SG_ 1937 TesterPhysicalReqTRM_ITRM 1;
BA_ "GenSigSendType" SG_ 557 AudioToneTouchY_D_Stat 3;
BA_ "U_V713AV_MY2022_Rx" SG_ 557 AudioToneTouchY_D_Stat 1;
BA_ "U_P708_MY2023_Rx" SG_ 557 AudioToneTouchY_D_Stat 1;
BA_ "U_V710_MY2023_Rx" SG_ 557 AudioToneTouchY_D_Stat 1;
BA_ "U_P702_MY2024_Rx" SG_ 557 AudioToneTouchY_D_Stat 1;
BA_ "GenSigSendType" SG_ 557 AudioToneTouchX_D_Stat 3;
BA_ "U_V713AV_MY2022_Rx" SG_ 557 AudioToneTouchX_D_Stat 1;
BA_ "U_P708_MY2023_Rx" SG_ 557 AudioToneTouchX_D_Stat 1;
BA_ "U_V710_MY2023_Rx" SG_ 557 AudioToneTouchX_D_Stat 1;
BA_ "U_P702_MY2024_Rx" SG_ 557 AudioToneTouchX_D_Stat 1;
BA_ "GenSigSendType" SG_ 557 AudioToneTouch_D_Stat 3;
BA_ "U_V713AV_MY2022_Rx" SG_ 557 AudioToneTouch_D_Stat 1;
BA_ "U_P708_MY2023_Rx" SG_ 557 AudioToneTouch_D_Stat 1;
BA_ "U_V710_MY2023_Rx" SG_ 557 AudioToneTouch_D_Stat 1;
BA_ "U_P702_MY2024_Rx" SG_ 557 AudioToneTouch_D_Stat 1;
BA_ "U_V710_MY2023_Tx" SG_ 718 BEZEL_RDISP_WORD_Rx 1;
BA_ "U_P708_MY2023_Tx" SG_ 718 BEZEL_RDISP_WORD_Rx 1;
BA_ "U_P702_MY2024_Tx" SG_ 718 BEZEL_RDISP_WORD_Rx 1;
BA_ "GenSigSendType" SG_ 140 DcacPwResetBttn_D_Stat 3;
BA_ "U_P702_MY2024_Tx" SG_ 140 DcacPwResetBttn_D_Stat 1;
BA_ "GenSigSendType" SG_ 140 CcAslButtnIndxIncPress2 3;
BA_ "U_V713N_MY2022_Tx" SG_ 140 CcAslButtnIndxIncPress2 1;
BA_ "U_V713AV_MY2022_Tx" SG_ 140 CcAslButtnIndxIncPress2 1;
BA_ "U_P702_MY2024_Tx" SG_ 140 CcAslButtnIndxIncPress2 1;
BA_ "GenSigSendType" SG_ 140 SteWhlSwtchMde_D_Stat 3;
BA_ "U_V713N_MY2022_Tx" SG_ 140 SteWhlSwtchMde_D_Stat 1;
BA_ "U_V713AV_MY2022_Tx" SG_ 140 SteWhlSwtchMde_D_Stat 1;
BA_ "U_P702_MY2024_Tx" SG_ 140 SteWhlSwtchMde_D_Stat 1;
BA_ "GenSigSendType" SG_ 140 CcAslButtnOffCnclPress2 3;
BA_ "U_V713N_MY2022_Tx" SG_ 140 CcAslButtnOffCnclPress2 1;
BA_ "U_V713AV_MY2022_Tx" SG_ 140 CcAslButtnOffCnclPress2 1;
BA_ "U_P702_MY2024_Tx" SG_ 140 CcAslButtnOffCnclPress2 1;
BA_ "GenSigSendType" SG_ 140 CcAslButtnIndxDecPress2 3;
BA_ "U_V713N_MY2022_Tx" SG_ 140 CcAslButtnIndxDecPress2 1;
BA_ "U_V713AV_MY2022_Tx" SG_ 140 CcAslButtnIndxDecPress2 1;
BA_ "U_P702_MY2024_Tx" SG_ 140 CcAslButtnIndxDecPress2 1;
BA_ "GenSigSendType" SG_ 140 CcAslButtnCnclResPress2 3;
BA_ "U_V713N_MY2022_Tx" SG_ 140 CcAslButtnCnclResPress2 1;
BA_ "U_V713AV_MY2022_Tx" SG_ 140 CcAslButtnCnclResPress2 1;
BA_ "U_P702_MY2024_Tx" SG_ 140 CcAslButtnCnclResPress2 1;
BA_ "GenSigSendType" SG_ 140 CcAslButtnResIncPress3 3;
BA_ "U_V713N_MY2022_Tx" SG_ 140 CcAslButtnResIncPress3 1;
BA_ "U_V713AV_MY2022_Tx" SG_ 140 CcAslButtnResIncPress3 1;
BA_ "U_P702_MY2024_Tx" SG_ 140 CcAslButtnResIncPress3 1;
BA_ "GenSigSendType" SG_ 140 CcButtnOnPress3 3;
BA_ "U_V713N_MY2022_Tx" SG_ 140 CcButtnOnPress3 1;
BA_ "U_V713AV_MY2022_Tx" SG_ 140 CcButtnOnPress3 1;
BA_ "U_P702_MY2024_Tx" SG_ 140 CcButtnOnPress3 1;
BA_ "GenSigSendType" SG_ 140 CcButtnOnOffPress3 3;
BA_ "U_V713N_MY2022_Tx" SG_ 140 CcButtnOnOffPress3 1;
BA_ "U_V713AV_MY2022_Tx" SG_ 140 CcButtnOnOffPress3 1;
BA_ "U_P702_MY2024_Tx" SG_ 140 CcButtnOnOffPress3 1;
BA_ "GenSigSendType" SG_ 140 CcButtnOnOffCnclPress3 3;
BA_ "U_V713N_MY2022_Tx" SG_ 140 CcButtnOnOffCnclPress3 1;
BA_ "U_V713AV_MY2022_Tx" SG_ 140 CcButtnOnOffCnclPress3 1;
BA_ "U_P702_MY2024_Tx" SG_ 140 CcButtnOnOffCnclPress3 1;
BA_ "GenSigSendType" SG_ 140 CcButtnOffPress3 3;
BA_ "U_V713N_MY2022_Tx" SG_ 140 CcButtnOffPress3 1;
BA_ "U_V713AV_MY2022_Tx" SG_ 140 CcButtnOffPress3 1;
BA_ "U_P702_MY2024_Tx" SG_ 140 CcButtnOffPress3 1;
BA_ "GenSigSendType" SG_ 140 CcAsllButtnResPress3 3;
BA_ "U_V713N_MY2022_Tx" SG_ 140 CcAsllButtnResPress3 1;
BA_ "U_V713AV_MY2022_Tx" SG_ 140 CcAsllButtnResPress3 1;
BA_ "U_P702_MY2024_Tx" SG_ 140 CcAsllButtnResPress3 1;
BA_ "GenSigSendType" SG_ 140 CcAslButtnSetPress3 3;
BA_ "U_V713N_MY2022_Tx" SG_ 140 CcAslButtnSetPress3 1;
BA_ "U_V713AV_MY2022_Tx" SG_ 140 CcAslButtnSetPress3 1;
BA_ "U_P702_MY2024_Tx" SG_ 140 CcAslButtnSetPress3 1;
BA_ "GenSigSendType" SG_ 140 CcAslButtnSetIncPress3 3;
BA_ "U_V713N_MY2022_Tx" SG_ 140 CcAslButtnSetIncPress3 1;
BA_ "U_V713AV_MY2022_Tx" SG_ 140 CcAslButtnSetIncPress3 1;
BA_ "U_P702_MY2024_Tx" SG_ 140 CcAslButtnSetIncPress3 1;
BA_ "GenSigSendType" SG_ 140 CcAslButtnSetDecPress3 3;
BA_ "U_V713N_MY2022_Tx" SG_ 140 CcAslButtnSetDecPress3 1;
BA_ "U_V713AV_MY2022_Tx" SG_ 140 CcAslButtnSetDecPress3 1;
BA_ "U_P702_MY2024_Tx" SG_ 140 CcAslButtnSetDecPress3 1;
BA_ "GenSigSendType" SG_ 140 CcAslButtnResDecPress3 3;
BA_ "U_V713N_MY2022_Tx" SG_ 140 CcAslButtnResDecPress3 1;
BA_ "U_V713AV_MY2022_Tx" SG_ 140 CcAslButtnResDecPress3 1;
BA_ "U_P702_MY2024_Tx" SG_ 140 CcAslButtnResDecPress3 1;
BA_ "GenSigSendType" SG_ 140 CcAslButtnOnPress3 3;
BA_ "U_V713N_MY2022_Tx" SG_ 140 CcAslButtnOnPress3 1;
BA_ "U_V713AV_MY2022_Tx" SG_ 140 CcAslButtnOnPress3 1;
BA_ "U_P702_MY2024_Tx" SG_ 140 CcAslButtnOnPress3 1;
BA_ "GenSigSendType" SG_ 140 CcAslButtnOnOffCncl3 3;
BA_ "U_V713N_MY2022_Tx" SG_ 140 CcAslButtnOnOffCncl3 1;
BA_ "U_V713AV_MY2022_Tx" SG_ 140 CcAslButtnOnOffCncl3 1;
BA_ "U_P702_MY2024_Tx" SG_ 140 CcAslButtnOnOffCncl3 1;
BA_ "GenSigSendType" SG_ 140 CcAslButtnDeny_B_Actl3 3;
BA_ "U_V713N_MY2022_Tx" SG_ 140 CcAslButtnDeny_B_Actl3 1;
BA_ "U_V713AV_MY2022_Tx" SG_ 140 CcAslButtnDeny_B_Actl3 1;
BA_ "U_P702_MY2024_Tx" SG_ 140 CcAslButtnDeny_B_Actl3 1;
BA_ "GenSigSendType" SG_ 140 CcAslButtnCnclPress3 3;
BA_ "U_V713N_MY2022_Tx" SG_ 140 CcAslButtnCnclPress3 1;
BA_ "U_V713AV_MY2022_Tx" SG_ 140 CcAslButtnCnclPress3 1;
BA_ "U_P702_MY2024_Tx" SG_ 140 CcAslButtnCnclPress3 1;
BA_ "GenSigSendType" SG_ 140 AslButtnOnOffPress3 3;
BA_ "U_V713N_MY2022_Tx" SG_ 140 AslButtnOnOffPress3 1;
BA_ "U_V713AV_MY2022_Tx" SG_ 140 AslButtnOnOffPress3 1;
BA_ "U_P702_MY2024_Tx" SG_ 140 AslButtnOnOffPress3 1;
BA_ "GenSigSendType" SG_ 140 AslButtnOnOffCnclPress2 3;
BA_ "U_V713N_MY2022_Tx" SG_ 140 AslButtnOnOffCnclPress2 1;
BA_ "U_V713AV_MY2022_Tx" SG_ 140 AslButtnOnOffCnclPress2 1;
BA_ "U_P702_MY2024_Tx" SG_ 140 AslButtnOnOffCnclPress2 1;
BA_ "GenSigSendType" SG_ 546 PrplSnd_D_Rq 3;
BA_ "U_V713N_MY2022_Rx" SG_ 546 PrplSnd_D_Rq 1;
BA_ "U_V713AV_MY2022_Rx" SG_ 546 PrplSnd_D_Rq 1;
BA_ "U_P708_MY2023_Rx" SG_ 546 PrplSnd_D_Rq 1;
BA_ "U_V710_MY2023_Rx" SG_ 546 PrplSnd_D_Rq 1;
BA_ "U_V710_MY2023_Tx" SG_ 546 PrplSnd_D_Rq 1;
BA_ "U_P708_MY2023_Tx" SG_ 546 PrplSnd_D_Rq 1;
BA_ "U_P702_MY2024_Tx" SG_ 546 PrplSnd_D_Rq 1;
BA_ "GenSigSendType" SG_ 546 SYNC_New_Attn_Event 3;
BA_ "U_V713N_MY2022_Rx" SG_ 546 SYNC_New_Attn_Event 1;
BA_ "U_V713AV_MY2022_Rx" SG_ 546 SYNC_New_Attn_Event 1;
BA_ "U_P708_MY2023_Rx" SG_ 546 SYNC_New_Attn_Event 1;
BA_ "U_V710_MY2023_Rx" SG_ 546 SYNC_New_Attn_Event 1;
BA_ "U_CDX74X_MY2024_Rx" SG_ 546 SYNC_New_Attn_Event 1;
BA_ "U_V710_MY2023_Tx" SG_ 546 SYNC_New_Attn_Event 1;
BA_ "U_P708_MY2023_Tx" SG_ 546 SYNC_New_Attn_Event 1;
BA_ "U_P702_MY2024_Tx" SG_ 546 SYNC_New_Attn_Event 1;
BA_ "GenSigSendType" SG_ 546 SYNC_Attn_Info_Audio 3;
BA_ "U_V713N_MY2022_Rx" SG_ 546 SYNC_Attn_Info_Audio 1;
BA_ "U_V713AV_MY2022_Rx" SG_ 546 SYNC_Attn_Info_Audio 1;
BA_ "U_P708_MY2023_Rx" SG_ 546 SYNC_Attn_Info_Audio 1;
BA_ "U_V710_MY2023_Rx" SG_ 546 SYNC_Attn_Info_Audio 1;
BA_ "U_CDX74X_MY2024_Rx" SG_ 546 SYNC_Attn_Info_Audio 1;
BA_ "U_V710_MY2023_Tx" SG_ 546 SYNC_Attn_Info_Audio 1;
BA_ "U_P708_MY2023_Tx" SG_ 546 SYNC_Attn_Info_Audio 1;
BA_ "U_P702_MY2024_Tx" SG_ 546 SYNC_Attn_Info_Audio 1;
BA_ "GenSigSendType" SG_ 546 Prompt_Directionality 3;
BA_ "U_V713N_MY2022_Rx" SG_ 546 Prompt_Directionality 1;
BA_ "U_V713AV_MY2022_Rx" SG_ 546 Prompt_Directionality 1;
BA_ "U_P708_MY2023_Rx" SG_ 546 Prompt_Directionality 1;
BA_ "U_V710_MY2023_Rx" SG_ 546 Prompt_Directionality 1;
BA_ "U_CDX74X_MY2024_Rx" SG_ 546 Prompt_Directionality 1;
BA_ "U_V710_MY2023_Tx" SG_ 546 Prompt_Directionality 1;
BA_ "U_P708_MY2023_Tx" SG_ 546 Prompt_Directionality 1;
BA_ "U_P702_MY2024_Tx" SG_ 546 Prompt_Directionality 1;
BA_ "GenSigSendType" SG_ 546 Audible_Beep 3;
BA_ "U_V713N_MY2022_Rx" SG_ 546 Audible_Beep 1;
BA_ "U_V713AV_MY2022_Rx" SG_ 546 Audible_Beep 1;
BA_ "U_P708_MY2023_Rx" SG_ 546 Audible_Beep 1;
BA_ "U_V710_MY2023_Rx" SG_ 546 Audible_Beep 1;
BA_ "U_CDX74X_MY2024_Rx" SG_ 546 Audible_Beep 1;
BA_ "U_V710_MY2023_Tx" SG_ 546 Audible_Beep 1;
BA_ "U_P708_MY2023_Tx" SG_ 546 Audible_Beep 1;
BA_ "U_P702_MY2024_Tx" SG_ 546 Audible_Beep 1;
BA_ "GenSigSendType" SG_ 546 Alert_Chan 3;
BA_ "U_V713N_MY2022_Rx" SG_ 546 Alert_Chan 1;
BA_ "U_V713AV_MY2022_Rx" SG_ 546 Alert_Chan 1;
BA_ "U_P708_MY2023_Rx" SG_ 546 Alert_Chan 1;
BA_ "U_V710_MY2023_Rx" SG_ 546 Alert_Chan 1;
BA_ "U_CDX74X_MY2024_Rx" SG_ 546 Alert_Chan 1;
BA_ "U_P702_MY2024_Rx" SG_ 546 Alert_Chan 1;
BA_ "U_V710_MY2023_Tx" SG_ 546 Alert_Chan 1;
BA_ "U_P708_MY2023_Tx" SG_ 546 Alert_Chan 1;
BA_ "U_P702_MY2024_Tx" SG_ 546 Alert_Chan 1;
BA_ "U_V713AV_MY2022_Rx" SG_ 1186 AwdStat2_D_RqDsply 1;
BA_ "U_P708_MY2023_Rx" SG_ 1186 AwdStat2_D_RqDsply 1;
BA_ "U_V710_MY2023_Rx" SG_ 1186 AwdStat2_D_RqDsply 1;
BA_ "U_V713N_MY2022_Rx" SG_ 1186 AwdStat2_D_RqDsply 1;
BA_ "U_P702_MY2024_Rx" SG_ 1186 AwdStat2_D_RqDsply 1;
BA_ "U_V713N_MY2022_Rx" SG_ 1186 AwdDrvMde_D2_Stat 1;
BA_ "U_V713AV_MY2022_Rx" SG_ 1186 AwdDrvMde_D2_Stat 1;
BA_ "U_P708_MY2023_Rx" SG_ 1186 AwdDrvMde_D2_Stat 1;
BA_ "U_P702_MY2024_Rx" SG_ 1186 AwdDrvMde_D2_Stat 1;
BA_ "U_V713N_MY2022_Rx" SG_ 1186 FrontDiffLckLamp_D_Rq 1;
BA_ "U_V713AV_MY2022_Rx" SG_ 1186 FrontDiffLckLamp_D_Rq 1;
BA_ "U_P708_MY2023_Rx" SG_ 1186 FrontDiffLckLamp_D_Rq 1;
BA_ "U_V710_MY2023_Rx" SG_ 1186 FrontDiffLckLamp_D_Rq 1;
BA_ "U_P702_MY2024_Rx" SG_ 1186 FrontDiffLckLamp_D_Rq 1;
BA_ "U_V713N_MY2022_Rx" SG_ 1186 FrontDiffLckMsg_D_Rq 1;
BA_ "U_V713AV_MY2022_Rx" SG_ 1186 FrontDiffLckMsg_D_Rq 1;
BA_ "U_P708_MY2023_Rx" SG_ 1186 FrontDiffLckMsg_D_Rq 1;
BA_ "U_V710_MY2023_Rx" SG_ 1186 FrontDiffLckMsg_D_Rq 1;
BA_ "U_P702_MY2024_Rx" SG_ 1186 FrontDiffLckMsg_D_Rq 1;
BA_ "U_V713N_MY2022_Rx" SG_ 1186 RearDiffLckLamp_D_Rq 1;
BA_ "U_V713AV_MY2022_Rx" SG_ 1186 RearDiffLckLamp_D_Rq 1;
BA_ "U_P708_MY2023_Rx" SG_ 1186 RearDiffLckLamp_D_Rq 1;
BA_ "U_V710_MY2023_Rx" SG_ 1186 RearDiffLckLamp_D_Rq 1;
BA_ "U_P702_MY2024_Rx" SG_ 1186 RearDiffLckLamp_D_Rq 1;
BA_ "GenSigStartValue" SG_ 1186 FrontDiffLck_Tq_Actl 16382;
BA_ "GenSigStartValue" SG_ 1186 SelDrvMdeAwd2_D_Stat 31;
BA_ "U_V713N_MY2022_Rx" SG_ 1186 RearDiffLckMsg_D_Rq 1;
BA_ "U_V713AV_MY2022_Rx" SG_ 1186 RearDiffLckMsg_D_Rq 1;
BA_ "U_P708_MY2023_Rx" SG_ 1186 RearDiffLckMsg_D_Rq 1;
BA_ "U_V710_MY2023_Rx" SG_ 1186 RearDiffLckMsg_D_Rq 1;
BA_ "U_P702_MY2024_Rx" SG_ 1186 RearDiffLckMsg_D_Rq 1;
BA_ "U_V713N_MY2022_Rx" SG_ 1186 LsdSrvcRqd_B_Rq 1;
BA_ "U_V713AV_MY2022_Rx" SG_ 1186 LsdSrvcRqd_B_Rq 1;
BA_ "U_P708_MY2023_Rx" SG_ 1186 LsdSrvcRqd_B_Rq 1;
BA_ "U_V710_MY2023_Rx" SG_ 1186 LsdSrvcRqd_B_Rq 1;
BA_ "U_P702_MY2024_Rx" SG_ 1186 LsdSrvcRqd_B_Rq 1;
BA_ "U_V713N_MY2022_Rx" SG_ 1138 ActChrgEndYr_No2_Actl 1;
BA_ "U_V713AV_MY2022_Rx" SG_ 1138 ActChrgEndYr_No2_Actl 1;
BA_ "U_V710_MY2023_Rx" SG_ 1138 ActChrgEndYr_No2_Actl 1;
BA_ "U_P708_MY2023_Rx" SG_ 1138 ActChrgEndYr_No2_Actl 1;
BA_ "U_P702_MY2024_Rx" SG_ 1138 ActChrgEndYr_No2_Actl 1;
BA_ "U_V710_MY2023_Rx" SG_ 1138 BattChrgTrgtLMin_T_Est 1;
BA_ "U_P708_MY2023_Rx" SG_ 1138 BattChrgTrgtLMin_T_Est 1;
BA_ "U_P702_MY2024_Rx" SG_ 1138 BattChrgTrgtLMin_T_Est 1;
BA_ "U_V713N_MY2022_Rx" SG_ 1138 ActChrgEndYr_No_Actl 1;
BA_ "U_V713AV_MY2022_Rx" SG_ 1138 ActChrgEndYr_No_Actl 1;
BA_ "U_V710_MY2023_Rx" SG_ 1138 ActChrgEndYr_No_Actl 1;
BA_ "U_P708_MY2023_Rx" SG_ 1138 ActChrgEndYr_No_Actl 1;
BA_ "U_P702_MY2024_Rx" SG_ 1138 ActChrgEndYr_No_Actl 1;
BA_ "GenSigStartValue" SG_ 1138 ActChrgEndMnth_No_Actl 1;
BA_ "U_V713N_MY2022_Rx" SG_ 1138 ActChrgEndMnth_No_Actl 1;
BA_ "U_V713AV_MY2022_Rx" SG_ 1138 ActChrgEndMnth_No_Actl 1;
BA_ "U_V710_MY2023_Rx" SG_ 1138 ActChrgEndMnth_No_Actl 1;
BA_ "U_P708_MY2023_Rx" SG_ 1138 ActChrgEndMnth_No_Actl 1;
BA_ "U_P702_MY2024_Rx" SG_ 1138 ActChrgEndMnth_No_Actl 1;
BA_ "U_V713N_MY2022_Rx" SG_ 1138 ActChrgEndMin_No_Actl 1;
BA_ "U_V713AV_MY2022_Rx" SG_ 1138 ActChrgEndMin_No_Actl 1;
BA_ "U_V710_MY2023_Rx" SG_ 1138 ActChrgEndMin_No_Actl 1;
BA_ "U_P708_MY2023_Rx" SG_ 1138 ActChrgEndMin_No_Actl 1;
BA_ "U_P702_MY2024_Rx" SG_ 1138 ActChrgEndMin_No_Actl 1;
BA_ "U_V713N_MY2022_Rx" SG_ 1138 ActChrgEndHr_No_Actl 1;
BA_ "U_V713AV_MY2022_Rx" SG_ 1138 ActChrgEndHr_No_Actl 1;
BA_ "U_V710_MY2023_Rx" SG_ 1138 ActChrgEndHr_No_Actl 1;
BA_ "U_P708_MY2023_Rx" SG_ 1138 ActChrgEndHr_No_Actl 1;
BA_ "U_P702_MY2024_Rx" SG_ 1138 ActChrgEndHr_No_Actl 1;
BA_ "GenSigStartValue" SG_ 1138 ActChrgEndDay_No_Actl 1;
BA_ "U_V713N_MY2022_Rx" SG_ 1138 ActChrgEndDay_No_Actl 1;
BA_ "U_V713AV_MY2022_Rx" SG_ 1138 ActChrgEndDay_No_Actl 1;
BA_ "U_V710_MY2023_Rx" SG_ 1138 ActChrgEndDay_No_Actl 1;
BA_ "U_P708_MY2023_Rx" SG_ 1138 ActChrgEndDay_No_Actl 1;
BA_ "U_P702_MY2024_Rx" SG_ 1138 ActChrgEndDay_No_Actl 1;
BA_ "U_V713N_MY2022_Rx" SG_ 1139 ActChrgStrtYr_No2_Actl 1;
BA_ "U_V713AV_MY2022_Rx" SG_ 1139 ActChrgStrtYr_No2_Actl 1;
BA_ "U_V710_MY2023_Rx" SG_ 1139 ActChrgStrtYr_No2_Actl 1;
BA_ "U_P708_MY2023_Rx" SG_ 1139 ActChrgStrtYr_No2_Actl 1;
BA_ "U_P702_MY2024_Rx" SG_ 1139 ActChrgStrtYr_No2_Actl 1;
BA_ "U_V710_MY2023_Rx" SG_ 1139 BattChrgTrgtLMax_T_Est 1;
BA_ "U_P708_MY2023_Rx" SG_ 1139 BattChrgTrgtLMax_T_Est 1;
BA_ "U_P702_MY2024_Rx" SG_ 1139 BattChrgTrgtLMax_T_Est 1;
BA_ "U_V713N_MY2022_Rx" SG_ 1139 ActChrgStrtYr_No_Actl 1;
BA_ "U_V713AV_MY2022_Rx" SG_ 1139 ActChrgStrtYr_No_Actl 1;
BA_ "U_V710_MY2023_Rx" SG_ 1139 ActChrgStrtYr_No_Actl 1;
BA_ "U_P708_MY2023_Rx" SG_ 1139 ActChrgStrtYr_No_Actl 1;
BA_ "U_P702_MY2024_Rx" SG_ 1139 ActChrgStrtYr_No_Actl 1;
BA_ "U_V713N_MY2022_Rx" SG_ 1139 ActChrgStrtMin_No_Actl 1;
BA_ "U_V713AV_MY2022_Rx" SG_ 1139 ActChrgStrtMin_No_Actl 1;
BA_ "U_V710_MY2023_Rx" SG_ 1139 ActChrgStrtMin_No_Actl 1;
BA_ "U_P708_MY2023_Rx" SG_ 1139 ActChrgStrtMin_No_Actl 1;
BA_ "U_P702_MY2024_Rx" SG_ 1139 ActChrgStrtMin_No_Actl 1;
BA_ "U_P708_MY2023_Rx" SG_ 1139 ActChrgStrtHr_No_Actl 1;
BA_ "U_P702_MY2024_Rx" SG_ 1139 ActChrgStrtHr_No_Actl 1;
BA_ "U_V713N_MY2022_Rx" SG_ 1139 ActChrgStrtHr_No_Actl 1;
BA_ "U_V713AV_MY2022_Rx" SG_ 1139 ActChrgStrtHr_No_Actl 1;
BA_ "U_V710_MY2023_Rx" SG_ 1139 ActChrgStrtHr_No_Actl 1;
BA_ "GenSigStartValue" SG_ 1139 ActChrgStrtDay_No_Actl 1;
BA_ "U_V713N_MY2022_Rx" SG_ 1139 ActChrgStrtDay_No_Actl 1;
BA_ "U_V713AV_MY2022_Rx" SG_ 1139 ActChrgStrtDay_No_Actl 1;
BA_ "U_V710_MY2023_Rx" SG_ 1139 ActChrgStrtDay_No_Actl 1;
BA_ "U_P708_MY2023_Rx" SG_ 1139 ActChrgStrtDay_No_Actl 1;
BA_ "U_P702_MY2024_Rx" SG_ 1139 ActChrgStrtDay_No_Actl 1;
BA_ "GenSigStartValue" SG_ 1139 ActChrgStrMnth_No_Actl 1;
BA_ "U_V713N_MY2022_Rx" SG_ 1139 ActChrgStrMnth_No_Actl 1;
BA_ "U_V713AV_MY2022_Rx" SG_ 1139 ActChrgStrMnth_No_Actl 1;
BA_ "U_V710_MY2023_Rx" SG_ 1139 ActChrgStrMnth_No_Actl 1;
BA_ "U_P708_MY2023_Rx" SG_ 1139 ActChrgStrMnth_No_Actl 1;
BA_ "U_P702_MY2024_Rx" SG_ 1139 ActChrgStrMnth_No_Actl 1;
BA_ "U_V713N_MY2022_Rx" SG_ 1145 EstmChrgTimeHP_St 1;
BA_ "U_V710_MY2023_Rx" SG_ 1145 EstmChrgTimeHP_St 1;
BA_ "U_P708_MY2023_Rx" SG_ 1145 EstmChrgTimeHP_St 1;
BA_ "U_P702_MY2024_Rx" SG_ 1145 EstmChrgTimeHP_St 1;
BA_ "U_V713N_MY2022_Rx" SG_ 1145 EstmChrgTimeLP_St 1;
BA_ "U_V710_MY2023_Rx" SG_ 1145 EstmChrgTimeLP_St 1;
BA_ "U_P708_MY2023_Rx" SG_ 1145 EstmChrgTimeLP_St 1;
BA_ "U_P702_MY2024_Rx" SG_ 1145 EstmChrgTimeLP_St 1;
BA_ "U_V713N_MY2022_Rx" SG_ 1145 ChargeNowDuration_St 1;
BA_ "U_V710_MY2023_Rx" SG_ 1145 ChargeNowDuration_St 1;
BA_ "U_P708_MY2023_Rx" SG_ 1145 ChargeNowDuration_St 1;
BA_ "U_P702_MY2024_Rx" SG_ 1145 ChargeNowDuration_St 1;
BA_ "GenSigStartValue" SG_ 1145 VehElRngeNut_L2_Dsply 8190;
BA_ "U_V710_MY2023_Rx" SG_ 1145 VehElRngeNut_L2_Dsply 1;
BA_ "U_P708_MY2023_Rx" SG_ 1145 VehElRngeNut_L2_Dsply 1;
BA_ "U_P702_MY2024_Rx" SG_ 1145 VehElRngeNut_L2_Dsply 1;
BA_ "U_V713N_MY2022_Rx" SG_ 1145 VehElRngeNut_L_Dsply 1;
BA_ "U_V710_MY2023_Rx" SG_ 1145 VehElRngeNut_L_Dsply 1;
BA_ "U_P708_MY2023_Rx" SG_ 1145 VehElRngeNut_L_Dsply 1;
BA_ "U_P702_MY2024_Rx" SG_ 1145 VehElRngeNut_L_Dsply 1;
BA_ "U_V710_MY2023_Rx" SG_ 1145 NxtUsgSocEst_Pc_Dsply 1;
BA_ "U_P708_MY2023_Rx" SG_ 1145 NxtUsgSocEst_Pc_Dsply 1;
BA_ "U_P702_MY2024_Rx" SG_ 1145 NxtUsgSocEst_Pc_Dsply 1;
BA_ "U_P708_MY2023_Rx" SG_ 1232 AHU_EnsembleName_St 1;
BA_ "U_P702_MY2024_Rx" SG_ 1232 AHU_EnsembleName_St 1;
BA_ "U_V713N_MY2022_Tx" SG_ 1232 AHU_EnsembleName_St 1;
BA_ "U_V713AV_MY2022_Tx" SG_ 1232 AHU_EnsembleName_St 1;
BA_ "U_P708_MY2023_Tx" SG_ 1232 AHU_EnsembleName_St 1;
BA_ "U_V710_MY2023_Tx" SG_ 1232 AHU_EnsembleName_St 1;
BA_ "U_P708_MY2023_Rx" SG_ 1232 AHU_AutoConfigOcc_Shakr 1;
BA_ "U_P702_MY2024_Rx" SG_ 1232 AHU_AutoConfigOcc_Shakr 1;
BA_ "U_V713N_MY2022_Tx" SG_ 1232 AHU_AutoConfigOcc_Shakr 1;
BA_ "U_V713AV_MY2022_Tx" SG_ 1232 AHU_AutoConfigOcc_Shakr 1;
BA_ "U_P708_MY2023_Tx" SG_ 1232 AHU_AutoConfigOcc_Shakr 1;
BA_ "U_V710_MY2023_Tx" SG_ 1232 AHU_AutoConfigOcc_Shakr 1;
BA_ "U_P708_MY2023_Rx" SG_ 1232 AHU_AutoConfigOcc_Rear 1;
BA_ "U_P702_MY2024_Rx" SG_ 1232 AHU_AutoConfigOcc_Rear 1;
BA_ "U_V713N_MY2022_Tx" SG_ 1232 AHU_AutoConfigOcc_Rear 1;
BA_ "U_V713AV_MY2022_Tx" SG_ 1232 AHU_AutoConfigOcc_Rear 1;
BA_ "U_P708_MY2023_Tx" SG_ 1232 AHU_AutoConfigOcc_Rear 1;
BA_ "U_V710_MY2023_Tx" SG_ 1232 AHU_AutoConfigOcc_Rear 1;
BA_ "U_P708_MY2023_Rx" SG_ 1232 AHU_AutoConfigOcc_Front 1;
BA_ "U_P702_MY2024_Rx" SG_ 1232 AHU_AutoConfigOcc_Front 1;
BA_ "U_V713N_MY2022_Tx" SG_ 1232 AHU_AutoConfigOcc_Front 1;
BA_ "U_V713AV_MY2022_Tx" SG_ 1232 AHU_AutoConfigOcc_Front 1;
BA_ "U_P708_MY2023_Tx" SG_ 1232 AHU_AutoConfigOcc_Front 1;
BA_ "U_V710_MY2023_Tx" SG_ 1232 AHU_AutoConfigOcc_Front 1;
BA_ "U_P708_MY2023_Rx" SG_ 1232 AHU_AutoConfigOcc_Drvr 1;
BA_ "U_P702_MY2024_Rx" SG_ 1232 AHU_AutoConfigOcc_Drvr 1;
BA_ "U_V713N_MY2022_Tx" SG_ 1232 AHU_AutoConfigOcc_Drvr 1;
BA_ "U_V713AV_MY2022_Tx" SG_ 1232 AHU_AutoConfigOcc_Drvr 1;
BA_ "U_P708_MY2023_Tx" SG_ 1232 AHU_AutoConfigOcc_Drvr 1;
BA_ "U_V710_MY2023_Tx" SG_ 1232 AHU_AutoConfigOcc_Drvr 1;
BA_ "U_P708_MY2023_Rx" SG_ 1232 AHU_AutoConfigOcc_Cnvrt 1;
BA_ "U_P702_MY2024_Rx" SG_ 1232 AHU_AutoConfigOcc_Cnvrt 1;
BA_ "U_V713N_MY2022_Tx" SG_ 1232 AHU_AutoConfigOcc_Cnvrt 1;
BA_ "U_V713AV_MY2022_Tx" SG_ 1232 AHU_AutoConfigOcc_Cnvrt 1;
BA_ "U_P708_MY2023_Tx" SG_ 1232 AHU_AutoConfigOcc_Cnvrt 1;
BA_ "U_V710_MY2023_Tx" SG_ 1232 AHU_AutoConfigOcc_Cnvrt 1;
BA_ "U_P708_MY2023_Rx" SG_ 1232 AHU_AutoConfigOcc_Allst 1;
BA_ "U_P702_MY2024_Rx" SG_ 1232 AHU_AutoConfigOcc_Allst 1;
BA_ "U_V713N_MY2022_Tx" SG_ 1232 AHU_AutoConfigOcc_Allst 1;
BA_ "U_V713AV_MY2022_Tx" SG_ 1232 AHU_AutoConfigOcc_Allst 1;
BA_ "U_P708_MY2023_Tx" SG_ 1232 AHU_AutoConfigOcc_Allst 1;
BA_ "U_V710_MY2023_Tx" SG_ 1232 AHU_AutoConfigOcc_Allst 1;
BA_ "U_V713N_MY2022_Rx" SG_ 1232 ACU_DigitalRadio_St 1;
BA_ "U_V713AV_MY2022_Rx" SG_ 1232 ACU_DigitalRadio_St 1;
BA_ "U_P708_MY2023_Rx" SG_ 1232 ACU_DigitalRadio_St 1;
BA_ "U_P702_MY2024_Rx" SG_ 1232 ACU_DigitalRadio_St 1;
BA_ "U_V713N_MY2022_Tx" SG_ 1232 ACU_DigitalRadio_St 1;
BA_ "U_V713AV_MY2022_Tx" SG_ 1232 ACU_DigitalRadio_St 1;
BA_ "U_P708_MY2023_Tx" SG_ 1232 ACU_DigitalRadio_St 1;
BA_ "U_V710_MY2023_Tx" SG_ 1232 ACU_DigitalRadio_St 1;
BA_ "U_V713N_MY2022_Rx" SG_ 1232 ACU_Configuration 1;
BA_ "U_V713AV_MY2022_Rx" SG_ 1232 ACU_Configuration 1;
BA_ "U_P708_MY2023_Rx" SG_ 1232 ACU_Configuration 1;
BA_ "U_P702_MY2024_Rx" SG_ 1232 ACU_Configuration 1;
BA_ "U_V713N_MY2022_Tx" SG_ 1232 ACU_Configuration 1;
BA_ "U_V713AV_MY2022_Tx" SG_ 1232 ACU_Configuration 1;
BA_ "U_P708_MY2023_Tx" SG_ 1232 ACU_Configuration 1;
BA_ "U_V710_MY2023_Tx" SG_ 1232 ACU_Configuration 1;
BA_ "U_V713N_MY2022_Rx" SG_ 1232 ACU_MediaPlayer_St 1;
BA_ "U_V713AV_MY2022_Rx" SG_ 1232 ACU_MediaPlayer_St 1;
BA_ "U_P708_MY2023_Rx" SG_ 1232 ACU_MediaPlayer_St 1;
BA_ "U_P702_MY2024_Rx" SG_ 1232 ACU_MediaPlayer_St 1;
BA_ "U_V713N_MY2022_Tx" SG_ 1232 ACU_MediaPlayer_St 1;
BA_ "U_V713AV_MY2022_Tx" SG_ 1232 ACU_MediaPlayer_St 1;
BA_ "U_P708_MY2023_Tx" SG_ 1232 ACU_MediaPlayer_St 1;
BA_ "U_V710_MY2023_Tx" SG_ 1232 ACU_MediaPlayer_St 1;
BA_ "GenSigStartValue" SG_ 1141 WhlPwRear_Pc_Dsply 511;
BA_ "U_V710_MY2023_Rx" SG_ 1141 WhlPwRear_Pc_Dsply 1;
BA_ "U_P702_MY2024_Rx" SG_ 1141 WhlPwRear_Pc_Dsply 1;
BA_ "GenSigStartValue" SG_ 1141 WhlPwFront_Pc_Dsply 511;
BA_ "U_V710_MY2023_Rx" SG_ 1141 WhlPwFront_Pc_Dsply 1;
BA_ "U_P702_MY2024_Rx" SG_ 1141 WhlPwFront_Pc_Dsply 1;
BA_ "U_V713AV_MY2022_Rx" SG_ 1141 AirAmbTePlgIn_D_Dsply 1;
BA_ "U_P708_MY2023_Rx" SG_ 1141 AirAmbTePlgIn_D_Dsply 1;
BA_ "U_V710_MY2023_Rx" SG_ 1141 AirAmbTePlgIn_D_Dsply 1;
BA_ "U_V713N_MY2022_Rx" SG_ 1141 AirAmbTePlgIn_D_Dsply 1;
BA_ "U_P702_MY2024_Rx" SG_ 1141 AirAmbTePlgIn_D_Dsply 1;
BA_ "GenSigStartValue" SG_ 1141 MtrTrac2_Tq_Actl 4095;
BA_ "WakeupSignal" SG_ 1141 PtRmtRprt_D_Rq 1;
BA_ "U_V713N_MY2022_Rx" SG_ 1141 PtRmtRprt_D_Rq 1;
BA_ "U_V713AV_MY2022_Rx" SG_ 1141 PtRmtRprt_D_Rq 1;
BA_ "U_V713N_MY2022_Rx" SG_ 1141 PreCondID_No_Rq 1;
BA_ "U_V713AV_MY2022_Rx" SG_ 1141 PreCondID_No_Rq 1;
BA_ "U_V713N_MY2022_Rx" SG_ 1141 NxtUsg_D_Rq 1;
BA_ "U_V713AV_MY2022_Rx" SG_ 1141 NxtUsg_D_Rq 1;
BA_ "U_V710_MY2023_Rx" SG_ 1141 NtfctnConflict1_D_Rq 1;
BA_ "U_P708_MY2023_Rx" SG_ 1141 NtfctnConflict1_D_Rq 1;
BA_ "U_P702_MY2024_Rx" SG_ 1141 NtfctnConflict1_D_Rq 1;
BA_ "U_V713N_MY2022_Rx" SG_ 1141 ChrgLocID_No_Rq 1;
BA_ "U_V713AV_MY2022_Rx" SG_ 1141 ChrgLocID_No_Rq 1;
BA_ "U_V713N_MY2022_Rx" SG_ 1141 ChrgLocGPS_D_Rq 1;
BA_ "U_V713AV_MY2022_Rx" SG_ 1141 ChrgLocGPS_D_Rq 1;
BA_ "U_V710_MY2023_Rx" SG_ 1141 OfbChrgSetSync_D_Stat 1;
BA_ "U_P708_MY2023_Rx" SG_ 1141 OfbChrgSetSync_D_Stat 1;
BA_ "U_P702_MY2024_Rx" SG_ 1141 OfbChrgSetSync_D_Stat 1;
BA_ "U_V713N_MY2022_Rx" SG_ 1140 BattTracPw_Pc_Avail 1;
BA_ "U_V713AV_MY2022_Rx" SG_ 1140 BattTracPw_Pc_Avail 1;
BA_ "U_V710_MY2023_Rx" SG_ 1140 BattTracPw_Pc_Avail 1;
BA_ "U_P702_MY2024_Rx" SG_ 1140 BattTracPw_Pc_Avail 1;
BA_ "U_V713N_MY2022_Rx" SG_ 1140 RgenLongTerm_L_Dsply 1;
BA_ "U_V713AV_MY2022_Rx" SG_ 1140 RgenLongTerm_L_Dsply 1;
BA_ "U_P708_MY2023_Rx" SG_ 1140 RgenLongTerm_L_Dsply 1;
BA_ "U_V710_MY2023_Rx" SG_ 1140 RgenLongTerm_L_Dsply 1;
BA_ "U_P702_MY2024_Rx" SG_ 1140 RgenLongTerm_L_Dsply 1;
BA_ "U_V713N_MY2022_Rx" SG_ 1140 PreCondStat_D_Dsply 1;
BA_ "U_V713AV_MY2022_Rx" SG_ 1140 PreCondStat_D_Dsply 1;
BA_ "U_V713N_MY2022_Rx" SG_ 1140 RgenLongTerm_Pc_Dsply 1;
BA_ "U_V713AV_MY2022_Rx" SG_ 1140 RgenLongTerm_Pc_Dsply 1;
BA_ "U_P708_MY2023_Rx" SG_ 1140 RgenLongTerm_Pc_Dsply 1;
BA_ "U_V710_MY2023_Rx" SG_ 1140 RgenLongTerm_Pc_Dsply 1;
BA_ "U_P702_MY2024_Rx" SG_ 1140 RgenLongTerm_Pc_Dsply 1;
BA_ "GenSigStartValue" SG_ 1140 RgenEvntLvl_Pc_Dsply 1022;
BA_ "U_V713N_MY2022_Rx" SG_ 1140 RgenEvntLvl_Pc_Dsply 1;
BA_ "U_V713AV_MY2022_Rx" SG_ 1140 RgenEvntLvl_Pc_Dsply 1;
BA_ "U_V710_MY2023_Rx" SG_ 1140 RgenEvntLvl_Pc_Dsply 1;
BA_ "U_P708_MY2023_Rx" SG_ 1140 RgenEvntLvl_Pc_Dsply 1;
BA_ "U_P702_MY2024_Rx" SG_ 1140 RgenEvntLvl_Pc_Dsply 1;
BA_ "U_V713N_MY2022_Rx" SG_ 1140 BrkEvntComplt_B_Dsply 1;
BA_ "U_V713AV_MY2022_Rx" SG_ 1140 BrkEvntComplt_B_Dsply 1;
BA_ "U_V710_MY2023_Rx" SG_ 1140 BrkEvntComplt_B_Dsply 1;
BA_ "U_P708_MY2023_Rx" SG_ 1140 BrkEvntComplt_B_Dsply 1;
BA_ "U_P702_MY2024_Rx" SG_ 1140 BrkEvntComplt_B_Dsply 1;
BA_ "U_V713N_MY2022_Rx" SG_ 1140 ExtChrgrFalt_B_Dsply 1;
BA_ "U_V713AV_MY2022_Rx" SG_ 1140 ExtChrgrFalt_B_Dsply 1;
BA_ "U_V710_MY2023_Rx" SG_ 1140 ExtChrgrFalt_B_Dsply 1;
BA_ "U_P708_MY2023_Rx" SG_ 1140 ExtChrgrFalt_B_Dsply 1;
BA_ "U_P702_MY2024_Rx" SG_ 1140 ExtChrgrFalt_B_Dsply 1;
BA_ "GenSigStartValue" SG_ 873 PwWhlLvl_Pc_Dsply 511;
BA_ "U_V713AV_MY2022_Rx" SG_ 873 PwWhlLvl_Pc_Dsply 1;
BA_ "U_P708_MY2023_Rx" SG_ 873 PwWhlLvl_Pc_Dsply 1;
BA_ "U_V710_MY2023_Rx" SG_ 873 PwWhlLvl_Pc_Dsply 1;
BA_ "U_V713N_MY2022_Rx" SG_ 873 PwWhlLvl_Pc_Dsply 1;
BA_ "U_P702_MY2024_Rx" SG_ 873 PwWhlLvl_Pc_Dsply 1;
BA_ "U_V713AV_MY2022_Rx" SG_ 873 BattTracEMaint_B_Dsply 1;
BA_ "U_P708_MY2023_Rx" SG_ 873 BattTracEMaint_B_Dsply 1;
BA_ "U_V710_MY2023_Rx" SG_ 873 BattTracEMaint_B_Dsply 1;
BA_ "U_V713N_MY2022_Rx" SG_ 873 BattTracEMaint_B_Dsply 1;
BA_ "U_P702_MY2024_Rx" SG_ 873 BattTracEMaint_B_Dsply 1;
BA_ "U_V713N_MY2022_Rx" SG_ 873 BattPwLvl2_Pc_Dsply 1;
BA_ "U_V710_MY2023_Rx" SG_ 873 BattPwLvl2_Pc_Dsply 1;
BA_ "U_P708_MY2023_Rx" SG_ 873 BattPwLvl2_Pc_Dsply 1;
BA_ "U_P702_MY2024_Rx" SG_ 873 BattPwLvl2_Pc_Dsply 1;
BA_ "U_V713N_MY2022_Rx" SG_ 873 EffRelTrgtOn_B_Dsply 1;
BA_ "U_V713AV_MY2022_Rx" SG_ 873 EffRelTrgtOn_B_Dsply 1;
BA_ "U_P708_MY2023_Rx" SG_ 873 EffRelTrgtOn_B_Dsply 1;
BA_ "U_V710_MY2023_Rx" SG_ 873 EffRelTrgtOn_B_Dsply 1;
BA_ "U_P702_MY2024_Rx" SG_ 873 EffRelTrgtOn_B_Dsply 1;
BA_ "U_V713N_MY2022_Rx" SG_ 873 EffInstThres_Pc_Dsply 1;
BA_ "U_V713AV_MY2022_Rx" SG_ 873 EffInstThres_Pc_Dsply 1;
BA_ "U_P708_MY2023_Rx" SG_ 873 EffInstThres_Pc_Dsply 1;
BA_ "U_V710_MY2023_Rx" SG_ 873 EffInstThres_Pc_Dsply 1;
BA_ "U_P702_MY2024_Rx" SG_ 873 EffInstThres_Pc_Dsply 1;
BA_ "U_V713N_MY2022_Rx" SG_ 873 EffInstLvl_Pc_Dsply 1;
BA_ "U_V713AV_MY2022_Rx" SG_ 873 EffInstLvl_Pc_Dsply 1;
BA_ "U_P708_MY2023_Rx" SG_ 873 EffInstLvl_Pc_Dsply 1;
BA_ "U_V710_MY2023_Rx" SG_ 873 EffInstLvl_Pc_Dsply 1;
BA_ "U_P702_MY2024_Rx" SG_ 873 EffInstLvl_Pc_Dsply 1;
BA_ "U_V713N_MY2022_Rx" SG_ 873 GpsElMdeActv_B_Dsply 1;
BA_ "U_V710_MY2023_Rx" SG_ 873 GpsElMdeActv_B_Dsply 1;
BA_ "U_P708_MY2023_Rx" SG_ 873 GpsElMdeActv_B_Dsply 1;
BA_ "U_P702_MY2024_Rx" SG_ 873 GpsElMdeActv_B_Dsply 1;
BA_ "U_V713N_MY2022_Rx" SG_ 873 LoAirAmbPlgIn_B_Dsply 1;
BA_ "U_V713AV_MY2022_Rx" SG_ 873 LoAirAmbPlgIn_B_Dsply 1;
BA_ "U_P708_MY2023_Rx" SG_ 873 LoAirAmbPlgIn_B_Dsply 1;
BA_ "U_V710_MY2023_Rx" SG_ 873 LoAirAmbPlgIn_B_Dsply 1;
BA_ "U_P702_MY2024_Rx" SG_ 873 LoAirAmbPlgIn_B_Dsply 1;
BA_ "U_V713N_MY2022_Rx" SG_ 873 VehVAnimation_Pc_Dsply 1;
BA_ "U_V713AV_MY2022_Rx" SG_ 873 VehVAnimation_Pc_Dsply 1;
BA_ "U_P708_MY2023_Rx" SG_ 873 VehVAnimation_Pc_Dsply 1;
BA_ "U_V710_MY2023_Rx" SG_ 873 VehVAnimation_Pc_Dsply 1;
BA_ "U_P702_MY2024_Rx" SG_ 873 VehVAnimation_Pc_Dsply 1;
BA_ "U_V713N_MY2022_Rx" SG_ 871 BattChrgCmpltPt_T_Est 1;
BA_ "U_V713AV_MY2022_Rx" SG_ 871 BattChrgCmpltPt_T_Est 1;
BA_ "U_V713N_MY2022_Rx" SG_ 871 BattChrgTrgSocPt_T_Est 1;
BA_ "U_V713AV_MY2022_Rx" SG_ 871 BattChrgTrgSocPt_T_Est 1;
BA_ "U_V713N_MY2022_Rx" SG_ 871 BattChrgTrgtLPt_T_Est 1;
BA_ "U_V713AV_MY2022_Rx" SG_ 871 BattChrgTrgtLPt_T_Est 1;
BA_ "U_V713N_MY2022_Rx" SG_ 871 BattElecPerf_D_Actl 1;
BA_ "U_V713AV_MY2022_Rx" SG_ 871 BattElecPerf_D_Actl 1;
BA_ "U_P708_MY2023_Rx" SG_ 871 BattElecPerf_D_Actl 1;
BA_ "U_V710_MY2023_Rx" SG_ 871 BattElecPerf_D_Actl 1;
BA_ "U_P702_MY2024_Rx" SG_ 871 BattElecPerf_D_Actl 1;
BA_ "U_V713N_MY2022_Rx" SG_ 871 VehAAnimation_Pc_Dsply 1;
BA_ "U_V713AV_MY2022_Rx" SG_ 871 VehAAnimation_Pc_Dsply 1;
BA_ "U_P708_MY2023_Rx" SG_ 871 VehAAnimation_Pc_Dsply 1;
BA_ "U_V710_MY2023_Rx" SG_ 871 VehAAnimation_Pc_Dsply 1;
BA_ "U_P702_MY2024_Rx" SG_ 871 VehAAnimation_Pc_Dsply 1;
BA_ "U_V713N_MY2022_Rx" SG_ 871 DrvEffLvlIncDec_D_Cmd 1;
BA_ "U_V713AV_MY2022_Rx" SG_ 871 DrvEffLvlIncDec_D_Cmd 1;
BA_ "U_P708_MY2023_Rx" SG_ 871 DrvEffLvlIncDec_D_Cmd 1;
BA_ "U_V710_MY2023_Rx" SG_ 871 DrvEffLvlIncDec_D_Cmd 1;
BA_ "U_P702_MY2024_Rx" SG_ 871 DrvEffLvlIncDec_D_Cmd 1;
BA_ "U_V713N_MY2022_Rx" SG_ 870 EngMdeMsgTxt_D_Rq 1;
BA_ "U_V713AV_MY2022_Rx" SG_ 870 EngMdeMsgTxt_D_Rq 1;
BA_ "U_V710_MY2023_Rx" SG_ 870 EngMdeMsgTxt_D_Rq 1;
BA_ "U_P708_MY2023_Rx" SG_ 870 EngMdeMsgTxt_D_Rq 1;
BA_ "U_P702_MY2024_Rx" SG_ 870 EngMdeMsgTxt_D_Rq 1;
BA_ "U_V713N_MY2022_Rx" SG_ 870 HybMdeMsgTxt_D2_Rq 1;
BA_ "U_V713AV_MY2022_Rx" SG_ 870 HybMdeMsgTxt_D2_Rq 1;
BA_ "U_V710_MY2023_Rx" SG_ 870 HybMdeMsgTxt_D2_Rq 1;
BA_ "U_P708_MY2023_Rx" SG_ 870 HybMdeMsgTxt_D2_Rq 1;
BA_ "U_P702_MY2024_Rx" SG_ 870 HybMdeMsgTxt_D2_Rq 1;
BA_ "U_V713N_MY2022_Rx" SG_ 870 PolicePurstMde_B_Stat 1;
BA_ "U_V713AV_MY2022_Rx" SG_ 870 PolicePurstMde_B_Stat 1;
BA_ "U_P708_MY2023_Rx" SG_ 870 PolicePurstMde_B_Stat 1;
BA_ "U_V710_MY2023_Rx" SG_ 870 PolicePurstMde_B_Stat 1;
BA_ "U_P702_MY2024_Rx" SG_ 870 PolicePurstMde_B_Stat 1;
BA_ "GenSigStartValue" SG_ 870 RngPerChrgInst_L_Dsply 4093;
BA_ "U_V713N_MY2022_Rx" SG_ 870 RngPerChrgInst_L_Dsply 1;
BA_ "U_V713AV_MY2022_Rx" SG_ 870 RngPerChrgInst_L_Dsply 1;
BA_ "U_P708_MY2023_Rx" SG_ 870 RngPerChrgInst_L_Dsply 1;
BA_ "U_V710_MY2023_Rx" SG_ 870 RngPerChrgInst_L_Dsply 1;
BA_ "U_P702_MY2024_Rx" SG_ 870 RngPerChrgInst_L_Dsply 1;
BA_ "U_V713N_MY2022_Rx" SG_ 870 ElFuelFlw_Vl_Dsply 1;
BA_ "U_V713AV_MY2022_Rx" SG_ 870 ElFuelFlw_Vl_Dsply 1;
BA_ "U_V710_MY2023_Rx" SG_ 870 ElFuelFlw_Vl_Dsply 1;
BA_ "U_P708_MY2023_Rx" SG_ 870 ElFuelFlw_Vl_Dsply 1;
BA_ "U_P702_MY2024_Rx" SG_ 870 ElFuelFlw_Vl_Dsply 1;
BA_ "U_V713N_MY2022_Rx" SG_ 870 HybMdeLimMsgTxt_D_Rq 1;
BA_ "U_V713AV_MY2022_Rx" SG_ 870 HybMdeLimMsgTxt_D_Rq 1;
BA_ "U_V710_MY2023_Rx" SG_ 870 HybMdeLimMsgTxt_D_Rq 1;
BA_ "U_P708_MY2023_Rx" SG_ 870 HybMdeLimMsgTxt_D_Rq 1;
BA_ "U_P702_MY2024_Rx" SG_ 870 HybMdeLimMsgTxt_D_Rq 1;
BA_ "U_V713N_MY2022_Rx" SG_ 870 BattPwWhl_Pc_Dsply 1;
BA_ "U_V713AV_MY2022_Rx" SG_ 870 BattPwWhl_Pc_Dsply 1;
BA_ "U_V710_MY2023_Rx" SG_ 870 BattPwWhl_Pc_Dsply 1;
BA_ "U_P708_MY2023_Rx" SG_ 870 BattPwWhl_Pc_Dsply 1;
BA_ "U_P702_MY2024_Rx" SG_ 870 BattPwWhl_Pc_Dsply 1;
BA_ "GenSigStartValue" SG_ 870 EffRgenThres_Pc_Dsply 1023;
BA_ "U_V713N_MY2022_Rx" SG_ 870 EffRgenThres_Pc_Dsply 1;
BA_ "U_V713AV_MY2022_Rx" SG_ 870 EffRgenThres_Pc_Dsply 1;
BA_ "U_V710_MY2023_Rx" SG_ 870 EffRgenThres_Pc_Dsply 1;
BA_ "U_P708_MY2023_Rx" SG_ 870 EffRgenThres_Pc_Dsply 1;
BA_ "U_P702_MY2024_Rx" SG_ 870 EffRgenThres_Pc_Dsply 1;
BA_ "U_V713N_MY2022_Rx" SG_ 870 ChkPlgtoStrt_D_Dsply 1;
BA_ "U_V713AV_MY2022_Rx" SG_ 870 ChkPlgtoStrt_D_Dsply 1;
BA_ "U_V710_MY2023_Rx" SG_ 870 ChkPlgtoStrt_D_Dsply 1;
BA_ "U_P708_MY2023_Rx" SG_ 870 ChkPlgtoStrt_D_Dsply 1;
BA_ "U_P702_MY2024_Rx" SG_ 870 ChkPlgtoStrt_D_Dsply 1;
BA_ "U_V713N_MY2022_Rx" SG_ 870 ShifOutNtrlMsgTxt_D_Rq 1;
BA_ "U_V713AV_MY2022_Rx" SG_ 870 ShifOutNtrlMsgTxt_D_Rq 1;
BA_ "U_V710_MY2023_Rx" SG_ 870 ShifOutNtrlMsgTxt_D_Rq 1;
BA_ "U_P708_MY2023_Rx" SG_ 870 ShifOutNtrlMsgTxt_D_Rq 1;
BA_ "U_P702_MY2024_Rx" SG_ 870 ShifOutNtrlMsgTxt_D_Rq 1;
BA_ "U_V713N_MY2022_Rx" SG_ 869 PwrFlowTxt_D_Dsply 1;
BA_ "U_V713AV_MY2022_Rx" SG_ 869 PwrFlowTxt_D_Dsply 1;
BA_ "U_V710_MY2023_Rx" SG_ 869 PwrFlowTxt_D_Dsply 1;
BA_ "U_P708_MY2023_Rx" SG_ 869 PwrFlowTxt_D_Dsply 1;
BA_ "U_P702_MY2024_Rx" SG_ 869 PwrFlowTxt_D_Dsply 1;
BA_ "U_V713N_MY2022_Rx" SG_ 869 EngOnMsg2_D_Dsply 1;
BA_ "U_V713AV_MY2022_Rx" SG_ 869 EngOnMsg2_D_Dsply 1;
BA_ "U_V710_MY2023_Rx" SG_ 869 EngOnMsg2_D_Dsply 1;
BA_ "U_P708_MY2023_Rx" SG_ 869 EngOnMsg2_D_Dsply 1;
BA_ "U_P702_MY2024_Rx" SG_ 869 EngOnMsg2_D_Dsply 1;
BA_ "U_V713N_MY2022_Rx" SG_ 869 EngOnMsg1_D_Dsply 1;
BA_ "U_V713AV_MY2022_Rx" SG_ 869 EngOnMsg1_D_Dsply 1;
BA_ "U_V710_MY2023_Rx" SG_ 869 EngOnMsg1_D_Dsply 1;
BA_ "U_P708_MY2023_Rx" SG_ 869 EngOnMsg1_D_Dsply 1;
BA_ "U_P702_MY2024_Rx" SG_ 869 EngOnMsg1_D_Dsply 1;
BA_ "U_V713N_MY2022_Rx" SG_ 869 FuelMaintMde_D_Dsply 1;
BA_ "U_V713AV_MY2022_Rx" SG_ 869 FuelMaintMde_D_Dsply 1;
BA_ "U_V710_MY2023_Rx" SG_ 869 FuelMaintMde_D_Dsply 1;
BA_ "U_P708_MY2023_Rx" SG_ 869 FuelMaintMde_D_Dsply 1;
BA_ "U_P702_MY2024_Rx" SG_ 869 FuelMaintMde_D_Dsply 1;
BA_ "U_V713N_MY2022_Rx" SG_ 869 EffWhlLvl2_Pc_Dsply 1;
BA_ "U_V713AV_MY2022_Rx" SG_ 869 EffWhlLvl2_Pc_Dsply 1;
BA_ "U_V710_MY2023_Rx" SG_ 869 EffWhlLvl2_Pc_Dsply 1;
BA_ "U_P708_MY2023_Rx" SG_ 869 EffWhlLvl2_Pc_Dsply 1;
BA_ "U_P702_MY2024_Rx" SG_ 869 EffWhlLvl2_Pc_Dsply 1;
BA_ "U_V713N_MY2022_Rx" SG_ 869 RgenActv_B_Dsply 1;
BA_ "U_V713AV_MY2022_Rx" SG_ 869 RgenActv_B_Dsply 1;
BA_ "U_P708_MY2023_Rx" SG_ 869 RgenActv_B_Dsply 1;
BA_ "U_V710_MY2023_Rx" SG_ 869 RgenActv_B_Dsply 1;
BA_ "U_P702_MY2024_Rx" SG_ 869 RgenActv_B_Dsply 1;
BA_ "U_V713N_MY2022_Rx" SG_ 869 EffWhlThres_Pc_Dsply 1;
BA_ "U_V713AV_MY2022_Rx" SG_ 869 EffWhlThres_Pc_Dsply 1;
BA_ "U_V710_MY2023_Rx" SG_ 869 EffWhlThres_Pc_Dsply 1;
BA_ "U_P708_MY2023_Rx" SG_ 869 EffWhlThres_Pc_Dsply 1;
BA_ "U_P702_MY2024_Rx" SG_ 869 EffWhlThres_Pc_Dsply 1;
BA_ "U_V713N_MY2022_Rx" SG_ 869 EffEAvg_Pc_Dsply 1;
BA_ "U_V713AV_MY2022_Rx" SG_ 869 EffEAvg_Pc_Dsply 1;
BA_ "U_V710_MY2023_Rx" SG_ 869 EffEAvg_Pc_Dsply 1;
BA_ "U_P708_MY2023_Rx" SG_ 869 EffEAvg_Pc_Dsply 1;
BA_ "U_P702_MY2024_Rx" SG_ 869 EffEAvg_Pc_Dsply 1;
BA_ "U_V713N_MY2022_Rx" SG_ 869 EngPwLvl_Pc_Dsply 1;
BA_ "U_V713AV_MY2022_Rx" SG_ 869 EngPwLvl_Pc_Dsply 1;
BA_ "U_V710_MY2023_Rx" SG_ 869 EngPwLvl_Pc_Dsply 1;
BA_ "U_P708_MY2023_Rx" SG_ 869 EngPwLvl_Pc_Dsply 1;
BA_ "U_P702_MY2024_Rx" SG_ 869 EngPwLvl_Pc_Dsply 1;
BA_ "U_V713N_MY2022_Rx" SG_ 869 EngOffTe_B_Dsply 1;
BA_ "U_V713AV_MY2022_Rx" SG_ 869 EngOffTe_B_Dsply 1;
BA_ "U_P708_MY2023_Rx" SG_ 869 EngOffTe_B_Dsply 1;
BA_ "U_V710_MY2023_Rx" SG_ 869 EngOffTe_B_Dsply 1;
BA_ "U_P702_MY2024_Rx" SG_ 869 EngOffTe_B_Dsply 1;
BA_ "U_V713N_MY2022_Rx" SG_ 869 EngActv_B_Dsply 1;
BA_ "U_V713AV_MY2022_Rx" SG_ 869 EngActv_B_Dsply 1;
BA_ "U_V710_MY2023_Rx" SG_ 869 EngActv_B_Dsply 1;
BA_ "U_P708_MY2023_Rx" SG_ 869 EngActv_B_Dsply 1;
BA_ "U_P702_MY2024_Rx" SG_ 869 EngActv_B_Dsply 1;
BA_ "U_V713N_MY2022_Rx" SG_ 869 EffWhlThresOn_B_Dsply 1;
BA_ "U_V713AV_MY2022_Rx" SG_ 869 EffWhlThresOn_B_Dsply 1;
BA_ "U_P708_MY2023_Rx" SG_ 869 EffWhlThresOn_B_Dsply 1;
BA_ "U_V710_MY2023_Rx" SG_ 869 EffWhlThresOn_B_Dsply 1;
BA_ "U_P702_MY2024_Rx" SG_ 869 EffWhlThresOn_B_Dsply 1;
BA_ "U_V713N_MY2022_Rx" SG_ 869 DchrgActv_B_Dsply 1;
BA_ "U_V713AV_MY2022_Rx" SG_ 869 DchrgActv_B_Dsply 1;
BA_ "U_P708_MY2023_Rx" SG_ 869 DchrgActv_B_Dsply 1;
BA_ "U_V710_MY2023_Rx" SG_ 869 DchrgActv_B_Dsply 1;
BA_ "U_P702_MY2024_Rx" SG_ 869 DchrgActv_B_Dsply 1;
BA_ "U_V713N_MY2022_Rx" SG_ 869 ChrgActv_B_Dsply 1;
BA_ "U_V713AV_MY2022_Rx" SG_ 869 ChrgActv_B_Dsply 1;
BA_ "U_P708_MY2023_Rx" SG_ 869 ChrgActv_B_Dsply 1;
BA_ "U_V710_MY2023_Rx" SG_ 869 ChrgActv_B_Dsply 1;
BA_ "U_P702_MY2024_Rx" SG_ 869 ChrgActv_B_Dsply 1;
BA_ "GenSigStartValue" SG_ 786 VehElRnge_L2_Dsply 8191;
BA_ "U_V713N_MY2022_Rx" SG_ 786 VehElRnge_L2_Dsply 1;
BA_ "U_V713AV_MY2022_Rx" SG_ 786 VehElRnge_L2_Dsply 1;
BA_ "U_V710_MY2023_Rx" SG_ 786 VehElRnge_L2_Dsply 1;
BA_ "U_P708_MY2023_Rx" SG_ 786 VehElRnge_L2_Dsply 1;
BA_ "U_P702_MY2024_Rx" SG_ 786 VehElRnge_L2_Dsply 1;
BA_ "U_V713N_MY2022_Rx" SG_ 786 RgenTrip_Pc_Dsply 1;
BA_ "U_V713AV_MY2022_Rx" SG_ 786 RgenTrip_Pc_Dsply 1;
BA_ "U_P708_MY2023_Rx" SG_ 786 RgenTrip_Pc_Dsply 1;
BA_ "U_V710_MY2023_Rx" SG_ 786 RgenTrip_Pc_Dsply 1;
BA_ "U_P702_MY2024_Rx" SG_ 786 RgenTrip_Pc_Dsply 1;
BA_ "GenSigStartValue" SG_ 786 RgenTrip_L_Dsply 65535;
BA_ "U_V713N_MY2022_Rx" SG_ 786 RgenTrip_L_Dsply 1;
BA_ "U_V713AV_MY2022_Rx" SG_ 786 RgenTrip_L_Dsply 1;
BA_ "U_P708_MY2023_Rx" SG_ 786 RgenTrip_L_Dsply 1;
BA_ "U_V710_MY2023_Rx" SG_ 786 RgenTrip_L_Dsply 1;
BA_ "U_P702_MY2024_Rx" SG_ 786 RgenTrip_L_Dsply 1;
BA_ "U_V710_MY2023_Rx" SG_ 786 VehElRngeCyc_L_Dsply 1;
BA_ "U_P708_MY2023_Rx" SG_ 786 VehElRngeCyc_L_Dsply 1;
BA_ "U_P702_MY2024_Rx" SG_ 786 VehElRngeCyc_L_Dsply 1;
BA_ "U_V713N_MY2022_Rx" SG_ 786 ChrgStat_D_Dsply 1;
BA_ "U_V713AV_MY2022_Rx" SG_ 786 ChrgStat_D_Dsply 1;
BA_ "U_V710_MY2023_Rx" SG_ 786 ChrgStat_D_Dsply 1;
BA_ "U_P708_MY2023_Rx" SG_ 786 ChrgStat_D_Dsply 1;
BA_ "U_P702_MY2024_Rx" SG_ 786 ChrgStat_D_Dsply 1;
BA_ "U_V710_MY2023_Rx" SG_ 1095 Pers4Phone_D_Stat 1;
BA_ "U_P708_MY2023_Rx" SG_ 1095 Pers4Phone_D_Stat 1;
BA_ "U_P702_MY2024_Rx" SG_ 1095 Pers4Phone_D_Stat 1;
BA_ "U_V710_MY2023_Rx" SG_ 1095 Pers3Phone_D_Stat 1;
BA_ "U_P708_MY2023_Rx" SG_ 1095 Pers3Phone_D_Stat 1;
BA_ "U_P702_MY2024_Rx" SG_ 1095 Pers3Phone_D_Stat 1;
BA_ "U_V710_MY2023_Rx" SG_ 1095 Pers2Phone_D_Stat 1;
BA_ "U_P708_MY2023_Rx" SG_ 1095 Pers2Phone_D_Stat 1;
BA_ "U_P702_MY2024_Rx" SG_ 1095 Pers2Phone_D_Stat 1;
BA_ "U_V710_MY2023_Rx" SG_ 1095 Pers1Phone_D_Stat 1;
BA_ "U_P708_MY2023_Rx" SG_ 1095 Pers1Phone_D_Stat 1;
BA_ "U_P702_MY2024_Rx" SG_ 1095 Pers1Phone_D_Stat 1;
BA_ "WakeupSignal" SG_ 1095 HeadLghtOn_D_Rq 1;
BA_ "GenSigStartValue" SG_ 1095 HeadLghtOn_D_Rq 1;
BA_ "U_V713N_MY2022_Rx" SG_ 684 MC_RDISP_WORD_Rx 1;
BA_ "U_V713AV_MY2022_Rx" SG_ 684 MC_RDISP_WORD_Rx 1;
BA_ "U_P708_MY2023_Rx" SG_ 684 MC_RDISP_WORD_Rx 1;
BA_ "U_P708_MY2023_Tx" SG_ 684 MC_RDISP_WORD_Rx 1;
BA_ "U_V713N_MY2022_Rx" SG_ 872 PwFlowPlgBatt_D_Dsply 1;
BA_ "U_V713AV_MY2022_Rx" SG_ 872 PwFlowPlgBatt_D_Dsply 1;
BA_ "U_V710_MY2023_Rx" SG_ 872 PwFlowPlgBatt_D_Dsply 1;
BA_ "U_P708_MY2023_Rx" SG_ 872 PwFlowPlgBatt_D_Dsply 1;
BA_ "U_P702_MY2024_Rx" SG_ 872 PwFlowPlgBatt_D_Dsply 1;
BA_ "U_V713N_MY2022_Rx" SG_ 872 PwFlowMtrDrv_D_Dsply 1;
BA_ "U_V713AV_MY2022_Rx" SG_ 872 PwFlowMtrDrv_D_Dsply 1;
BA_ "U_V710_MY2023_Rx" SG_ 872 PwFlowMtrDrv_D_Dsply 1;
BA_ "U_P708_MY2023_Rx" SG_ 872 PwFlowMtrDrv_D_Dsply 1;
BA_ "U_P702_MY2024_Rx" SG_ 872 PwFlowMtrDrv_D_Dsply 1;
BA_ "U_V713N_MY2022_Rx" SG_ 872 PwFlowEngMtr_D_Dsply 1;
BA_ "U_V713AV_MY2022_Rx" SG_ 872 PwFlowEngMtr_D_Dsply 1;
BA_ "U_V710_MY2023_Rx" SG_ 872 PwFlowEngMtr_D_Dsply 1;
BA_ "U_P708_MY2023_Rx" SG_ 872 PwFlowEngMtr_D_Dsply 1;
BA_ "U_P702_MY2024_Rx" SG_ 872 PwFlowEngMtr_D_Dsply 1;
BA_ "U_V713N_MY2022_Rx" SG_ 872 PwFlowEngFuel_D_Dsply 1;
BA_ "U_V713AV_MY2022_Rx" SG_ 872 PwFlowEngFuel_D_Dsply 1;
BA_ "U_V710_MY2023_Rx" SG_ 872 PwFlowEngFuel_D_Dsply 1;
BA_ "U_P708_MY2023_Rx" SG_ 872 PwFlowEngFuel_D_Dsply 1;
BA_ "U_P702_MY2024_Rx" SG_ 872 PwFlowEngFuel_D_Dsply 1;
BA_ "U_V713N_MY2022_Rx" SG_ 872 PwFlowEngDrv_D_Dsply 1;
BA_ "U_V713AV_MY2022_Rx" SG_ 872 PwFlowEngDrv_D_Dsply 1;
BA_ "U_V710_MY2023_Rx" SG_ 872 PwFlowEngDrv_D_Dsply 1;
BA_ "U_P708_MY2023_Rx" SG_ 872 PwFlowEngDrv_D_Dsply 1;
BA_ "U_P702_MY2024_Rx" SG_ 872 PwFlowEngDrv_D_Dsply 1;
BA_ "U_V713N_MY2022_Rx" SG_ 872 PwFlowBattMtr_D_Dsply 1;
BA_ "U_V713AV_MY2022_Rx" SG_ 872 PwFlowBattMtr_D_Dsply 1;
BA_ "U_V710_MY2023_Rx" SG_ 872 PwFlowBattMtr_D_Dsply 1;
BA_ "U_P708_MY2023_Rx" SG_ 872 PwFlowBattMtr_D_Dsply 1;
BA_ "U_P702_MY2024_Rx" SG_ 872 PwFlowBattMtr_D_Dsply 1;
BA_ "U_V713N_MY2022_Rx" SG_ 872 MtrPwLvl_Pc_Dsply 1;
BA_ "U_V713AV_MY2022_Rx" SG_ 872 MtrPwLvl_Pc_Dsply 1;
BA_ "U_V710_MY2023_Rx" SG_ 872 MtrPwLvl_Pc_Dsply 1;
BA_ "U_P708_MY2023_Rx" SG_ 872 MtrPwLvl_Pc_Dsply 1;
BA_ "U_P702_MY2024_Rx" SG_ 872 MtrPwLvl_Pc_Dsply 1;
BA_ "U_V713N_MY2022_Rx" SG_ 872 HybMdeStat_D_Dsply 1;
BA_ "U_V713AV_MY2022_Rx" SG_ 872 HybMdeStat_D_Dsply 1;
BA_ "U_V710_MY2023_Rx" SG_ 872 HybMdeStat_D_Dsply 1;
BA_ "U_P708_MY2023_Rx" SG_ 872 HybMdeStat_D_Dsply 1;
BA_ "U_P702_MY2024_Rx" SG_ 872 HybMdeStat_D_Dsply 1;
BA_ "U_V713N_MY2022_Rx" SG_ 872 PlgActvArb_B_Dsply 1;
BA_ "U_V713AV_MY2022_Rx" SG_ 872 PlgActvArb_B_Dsply 1;
BA_ "U_V710_MY2023_Rx" SG_ 872 PlgActvArb_B_Dsply 1;
BA_ "U_P708_MY2023_Rx" SG_ 872 PlgActvArb_B_Dsply 1;
BA_ "U_P702_MY2024_Rx" SG_ 872 PlgActvArb_B_Dsply 1;
BA_ "U_V713N_MY2022_Rx" SG_ 872 LvAcsyPwLvl_Pc_Dsply 1;
BA_ "U_V713AV_MY2022_Rx" SG_ 872 LvAcsyPwLvl_Pc_Dsply 1;
BA_ "U_V710_MY2023_Rx" SG_ 872 LvAcsyPwLvl_Pc_Dsply 1;
BA_ "U_P708_MY2023_Rx" SG_ 872 LvAcsyPwLvl_Pc_Dsply 1;
BA_ "U_P702_MY2024_Rx" SG_ 872 LvAcsyPwLvl_Pc_Dsply 1;
BA_ "U_V713N_MY2022_Rx" SG_ 872 ClimPwLvl_Pc_Dsply 1;
BA_ "U_V713AV_MY2022_Rx" SG_ 872 ClimPwLvl_Pc_Dsply 1;
BA_ "U_V710_MY2023_Rx" SG_ 872 ClimPwLvl_Pc_Dsply 1;
BA_ "U_P708_MY2023_Rx" SG_ 872 ClimPwLvl_Pc_Dsply 1;
BA_ "U_P702_MY2024_Rx" SG_ 872 ClimPwLvl_Pc_Dsply 1;
BA_ "GenSigStartValue" SG_ 872 DcdcIn_Pw_Mx 115;
BA_ "U_V713N_MY2022_Rx" SG_ 872 EcoMode_B_Stat 1;
BA_ "U_V713AV_MY2022_Rx" SG_ 872 EcoMode_B_Stat 1;
BA_ "U_P702_MY2024_Rx" SG_ 872 EcoMode_B_Stat 1;
BA_ "U_V713N_MY2022_Rx" SG_ 872 MildHybStat_D_Dsply 1;
BA_ "U_V713AV_MY2022_Rx" SG_ 872 MildHybStat_D_Dsply 1;
BA_ "U_V710_MY2023_Rx" SG_ 872 MildHybStat_D_Dsply 1;
BA_ "U_P708_MY2023_Rx" SG_ 872 MildHybStat_D_Dsply 1;
BA_ "U_P702_MY2024_Rx" SG_ 872 MildHybStat_D_Dsply 1;
BA_ "GenSigStartValue" SG_ 791 StopStrtVThres_D_RqMnu 1;
BA_ "GenSigSendType" SG_ 791 StopStrtVThres_D_RqMnu 3;
BA_ "U_V713AV_MY2022_Tx" SG_ 791 StopStrtVThres_D_RqMnu 1;
BA_ "U_P708_MY2023_Tx" SG_ 791 StopStrtVThres_D_RqMnu 1;
BA_ "U_V710_MY2023_Tx" SG_ 791 StopStrtVThres_D_RqMnu 1;
BA_ "U_V713N_MY2022_Tx" SG_ 791 StopStrtVThres_D_RqMnu 1;
BA_ "U_P702_MY2024_Tx" SG_ 791 StopStrtVThres_D_RqMnu 1;
BA_ "GenSigSendType" SG_ 791 AwdDrvMde_D2_Rq 3;
BA_ "U_V713AV_MY2022_Tx" SG_ 791 AwdDrvMde_D2_Rq 1;
BA_ "U_P708_MY2023_Tx" SG_ 791 AwdDrvMde_D2_Rq 1;
BA_ "U_V710_MY2023_Tx" SG_ 791 AwdDrvMde_D2_Rq 1;
BA_ "U_V713N_MY2022_Tx" SG_ 791 AwdDrvMde_D2_Rq 1;
BA_ "U_P702_MY2024_Tx" SG_ 791 AwdDrvMde_D2_Rq 1;
BA_ "GenSigSendType" SG_ 791 EngAirFilt_B_RqReset 3;
BA_ "U_V713N_MY2022_Tx" SG_ 791 EngAirFilt_B_RqReset 1;
BA_ "U_V713AV_MY2022_Tx" SG_ 791 EngAirFilt_B_RqReset 1;
BA_ "U_V710_MY2023_Tx" SG_ 791 EngAirFilt_B_RqReset 1;
BA_ "U_P708_MY2023_Tx" SG_ 791 EngAirFilt_B_RqReset 1;
BA_ "U_P702_MY2024_Tx" SG_ 791 EngAirFilt_B_RqReset 1;
BA_ "GenSigStartValue" SG_ 791 BattElEmotive_Pc_Dsply 1022;
BA_ "U_P708_MY2023_Rx" SG_ 791 BattElEmotive_Pc_Dsply 1;
BA_ "U_V713AV_MY2022_Tx" SG_ 791 BattElEmotive_Pc_Dsply 1;
BA_ "U_P708_MY2023_Tx" SG_ 791 BattElEmotive_Pc_Dsply 1;
BA_ "U_V710_MY2023_Tx" SG_ 791 BattElEmotive_Pc_Dsply 1;
BA_ "U_V713N_MY2022_Tx" SG_ 791 BattElEmotive_Pc_Dsply 1;
BA_ "GenSigSendType" SG_ 791 VehElEffTrip2Reset_B_Rq 3;
BA_ "U_V713N_MY2022_Tx" SG_ 791 VehElEffTrip2Reset_B_Rq 1;
BA_ "U_V713AV_MY2022_Tx" SG_ 791 VehElEffTrip2Reset_B_Rq 1;
BA_ "U_V710_MY2023_Tx" SG_ 791 VehElEffTrip2Reset_B_Rq 1;
BA_ "U_P708_MY2023_Tx" SG_ 791 VehElEffTrip2Reset_B_Rq 1;
BA_ "U_P702_MY2024_Tx" SG_ 791 VehElEffTrip2Reset_B_Rq 1;
BA_ "GenSigSendType" SG_ 791 VehElEffTrip1Reset_B_Rq 3;
BA_ "U_V713N_MY2022_Tx" SG_ 791 VehElEffTrip1Reset_B_Rq 1;
BA_ "U_V713AV_MY2022_Tx" SG_ 791 VehElEffTrip1Reset_B_Rq 1;
BA_ "U_V710_MY2023_Tx" SG_ 791 VehElEffTrip1Reset_B_Rq 1;
BA_ "U_P708_MY2023_Tx" SG_ 791 VehElEffTrip1Reset_B_Rq 1;
BA_ "U_P702_MY2024_Tx" SG_ 791 VehElEffTrip1Reset_B_Rq 1;
BA_ "GenSigSendType" SG_ 791 HybMdeOvrrd_D_Rq 3;
BA_ "U_V713AV_MY2022_Tx" SG_ 791 HybMdeOvrrd_D_Rq 1;
BA_ "U_P708_MY2023_Tx" SG_ 791 HybMdeOvrrd_D_Rq 1;
BA_ "U_V710_MY2023_Tx" SG_ 791 HybMdeOvrrd_D_Rq 1;
BA_ "U_V713N_MY2022_Tx" SG_ 791 HybMdeOvrrd_D_Rq 1;
BA_ "U_P702_MY2024_Tx" SG_ 791 HybMdeOvrrd_D_Rq 1;
BA_ "GenSigSendType" SG_ 791 GpsElMdeSel_B_Rq 3;
BA_ "U_V713AV_MY2022_Tx" SG_ 791 GpsElMdeSel_B_Rq 1;
BA_ "U_P708_MY2023_Tx" SG_ 791 GpsElMdeSel_B_Rq 1;
BA_ "U_V710_MY2023_Tx" SG_ 791 GpsElMdeSel_B_Rq 1;
BA_ "U_V713N_MY2022_Tx" SG_ 791 GpsElMdeSel_B_Rq 1;
BA_ "U_P702_MY2024_Tx" SG_ 791 GpsElMdeSel_B_Rq 1;
BA_ "GenSigSendType" SG_ 791 LongTermReset_B_Rq 3;
BA_ "U_V713AV_MY2022_Tx" SG_ 791 LongTermReset_B_Rq 1;
BA_ "U_P708_MY2023_Tx" SG_ 791 LongTermReset_B_Rq 1;
BA_ "U_V710_MY2023_Tx" SG_ 791 LongTermReset_B_Rq 1;
BA_ "U_V713N_MY2022_Tx" SG_ 791 LongTermReset_B_Rq 1;
BA_ "U_P702_MY2024_Tx" SG_ 791 LongTermReset_B_Rq 1;
BA_ "GenSigSendType" SG_ 791 EcoCcActv_B_Rq 3;
BA_ "U_V713AV_MY2022_Tx" SG_ 791 EcoCcActv_B_Rq 1;
BA_ "U_P708_MY2023_Tx" SG_ 791 EcoCcActv_B_Rq 1;
BA_ "U_V710_MY2023_Tx" SG_ 791 EcoCcActv_B_Rq 1;
BA_ "U_V713N_MY2022_Tx" SG_ 791 EcoCcActv_B_Rq 1;
BA_ "U_P702_MY2024_Tx" SG_ 791 EcoCcActv_B_Rq 1;
BA_ "U_P708_MY2023_Rx" SG_ 791 DrvEffLvl_No_Stat 1;
BA_ "U_P702_MY2024_Rx" SG_ 791 DrvEffLvl_No_Stat 1;
BA_ "U_V713AV_MY2022_Tx" SG_ 791 DrvEffLvl_No_Stat 1;
BA_ "U_P708_MY2023_Tx" SG_ 791 DrvEffLvl_No_Stat 1;
BA_ "U_V710_MY2023_Tx" SG_ 791 DrvEffLvl_No_Stat 1;
BA_ "U_V713N_MY2022_Tx" SG_ 791 DrvEffLvl_No_Stat 1;
BA_ "U_P702_MY2024_Tx" SG_ 791 DrvEffLvl_No_Stat 1;
BA_ "WakeupSignal" SG_ 791 ChargeProfIDPref_Rq 1;
BA_ "GenSigSendType" SG_ 791 ChargeProfIDPref_Rq 3;
BA_ "U_V713AV_MY2022_Tx" SG_ 791 ChargeProfIDPref_Rq 1;
BA_ "U_P708_MY2023_Tx" SG_ 791 ChargeProfIDPref_Rq 1;
BA_ "U_V710_MY2023_Tx" SG_ 791 ChargeProfIDPref_Rq 1;
BA_ "U_V713N_MY2022_Tx" SG_ 791 ChargeProfIDPref_Rq 1;
BA_ "U_P702_MY2024_Tx" SG_ 791 ChargeProfIDPref_Rq 1;
BA_ "ECGUsedRxSignal" SG_ 791 ConsAvgTrip_Fe_Dsply 1;
BA_ "U_V713N_MY2022_Rx" SG_ 791 ConsAvgTrip_Fe_Dsply 1;
BA_ "U_V713AV_MY2022_Rx" SG_ 791 ConsAvgTrip_Fe_Dsply 1;
BA_ "U_P708_MY2023_Rx" SG_ 791 ConsAvgTrip_Fe_Dsply 1;
BA_ "U_CDX74X_MY2024_Rx" SG_ 791 ConsAvgTrip_Fe_Dsply 1;
BA_ "U_V710_MY2023_Rx" SG_ 791 ConsAvgTrip_Fe_Dsply 1;
BA_ "U_V713AV_MY2022_Tx" SG_ 791 ConsAvgTrip_Fe_Dsply 1;
BA_ "U_P708_MY2023_Tx" SG_ 791 ConsAvgTrip_Fe_Dsply 1;
BA_ "U_V710_MY2023_Tx" SG_ 791 ConsAvgTrip_Fe_Dsply 1;
BA_ "U_V713N_MY2022_Tx" SG_ 791 ConsAvgTrip_Fe_Dsply 1;
BA_ "U_P702_MY2024_Tx" SG_ 791 ConsAvgTrip_Fe_Dsply 1;
BA_ "U_V713AV_MY2022_Tx" SG_ 791 GrdAsstAllw_D_RqMnu 1;
BA_ "U_P708_MY2023_Tx" SG_ 791 GrdAsstAllw_D_RqMnu 1;
BA_ "U_V710_MY2023_Tx" SG_ 791 GrdAsstAllw_D_RqMnu 1;
BA_ "U_V713N_MY2022_Tx" SG_ 791 GrdAsstAllw_D_RqMnu 1;
BA_ "U_P702_MY2024_Tx" SG_ 791 GrdAsstAllw_D_RqMnu 1;
BA_ "GenSigSendType" SG_ 791 PlgOvrrdStrt_D_Cmd 3;
BA_ "U_V713AV_MY2022_Tx" SG_ 791 PlgOvrrdStrt_D_Cmd 1;
BA_ "U_P708_MY2023_Tx" SG_ 791 PlgOvrrdStrt_D_Cmd 1;
BA_ "U_V710_MY2023_Tx" SG_ 791 PlgOvrrdStrt_D_Cmd 1;
BA_ "U_V713N_MY2022_Tx" SG_ 791 PlgOvrrdStrt_D_Cmd 1;
BA_ "U_P702_MY2024_Tx" SG_ 791 PlgOvrrdStrt_D_Cmd 1;
BA_ "GenSigStartValue" SG_ 791 EcoMde_D_RqMnu 1;
BA_ "GenSigSendType" SG_ 791 EcoMde_D_RqMnu 3;
BA_ "U_V713AV_MY2022_Tx" SG_ 791 EcoMde_D_RqMnu 1;
BA_ "U_P708_MY2023_Tx" SG_ 791 EcoMde_D_RqMnu 1;
BA_ "U_V710_MY2023_Tx" SG_ 791 EcoMde_D_RqMnu 1;
BA_ "U_V713N_MY2022_Tx" SG_ 791 EcoMde_D_RqMnu 1;
BA_ "U_P702_MY2024_Tx" SG_ 791 EcoMde_D_RqMnu 1;
BA_ "GenSigSendType" SG_ 791 EmotiveType_D_Dsply 3;
BA_ "U_P708_MY2023_Rx" SG_ 791 EmotiveType_D_Dsply 1;
BA_ "U_V713AV_MY2022_Tx" SG_ 791 EmotiveType_D_Dsply 1;
BA_ "U_P708_MY2023_Tx" SG_ 791 EmotiveType_D_Dsply 1;
BA_ "U_V710_MY2023_Tx" SG_ 791 EmotiveType_D_Dsply 1;
BA_ "U_V713N_MY2022_Tx" SG_ 791 EmotiveType_D_Dsply 1;
BA_ "U_V713N_MY2022_Rx" SG_ 358 StopStrtStdby_D_Indic 1;
BA_ "U_V713AV_MY2022_Rx" SG_ 358 StopStrtStdby_D_Indic 1;
BA_ "U_P708_MY2023_Rx" SG_ 358 StopStrtStdby_D_Indic 1;
BA_ "U_V710_MY2023_Rx" SG_ 358 StopStrtStdby_D_Indic 1;
BA_ "U_P702_MY2024_Rx" SG_ 358 StopStrtStdby_D_Indic 1;
BA_ "U_V713N_MY2022_Rx" SG_ 358 StopStrtIODTxt_D_Rq 1;
BA_ "U_V713AV_MY2022_Rx" SG_ 358 StopStrtIODTxt_D_Rq 1;
BA_ "U_P708_MY2023_Rx" SG_ 358 StopStrtIODTxt_D_Rq 1;
BA_ "U_V710_MY2023_Rx" SG_ 358 StopStrtIODTxt_D_Rq 1;
BA_ "U_P702_MY2024_Rx" SG_ 358 StopStrtIODTxt_D_Rq 1;
BA_ "U_V713N_MY2022_Rx" SG_ 358 StopStrtDrvMde_D_Indic 1;
BA_ "U_V713AV_MY2022_Rx" SG_ 358 StopStrtDrvMde_D_Indic 1;
BA_ "U_P708_MY2023_Rx" SG_ 358 StopStrtDrvMde_D_Indic 1;
BA_ "U_V710_MY2023_Rx" SG_ 358 StopStrtDrvMde_D_Indic 1;
BA_ "U_P702_MY2024_Rx" SG_ 358 StopStrtDrvMde_D_Indic 1;
BA_ "U_V713N_MY2022_Rx" SG_ 358 StopStrtMsgTxt_D_Rq 1;
BA_ "U_V713AV_MY2022_Rx" SG_ 358 StopStrtMsgTxt_D_Rq 1;
BA_ "U_P708_MY2023_Rx" SG_ 358 StopStrtMsgTxt_D_Rq 1;
BA_ "U_V710_MY2023_Rx" SG_ 358 StopStrtMsgTxt_D_Rq 1;
BA_ "U_P702_MY2024_Rx" SG_ 358 StopStrtMsgTxt_D_Rq 1;
BA_ "U_V713N_MY2022_Rx" SG_ 358 OdoTripVerify_L_Actl 1;
BA_ "U_V713AV_MY2022_Rx" SG_ 358 OdoTripVerify_L_Actl 1;
BA_ "U_P708_MY2023_Rx" SG_ 358 OdoTripVerify_L_Actl 1;
BA_ "U_V710_MY2023_Rx" SG_ 358 OdoTripVerify_L_Actl 1;
BA_ "U_P702_MY2024_Rx" SG_ 358 OdoTripVerify_L_Actl 1;
BA_ "WakeupSignal" SG_ 945 AdasRelay_B_Stat2 1;
BA_ "U_P708_MY2023_Rx" SG_ 945 StrtrMtrCtlMsgTxt_D_Rq2 1;
BA_ "U_P702_MY2024_Rx" SG_ 945 StrtrMtrCtlMsgTxt_D_Rq2 1;
BA_ "WakeupSignal" SG_ 945 PrkLckCtlMsgTxt_D2_Rq 1;
BA_ "U_P708_MY2023_Rx" SG_ 945 PrkLckCtlMsgTxt_D2_Rq 1;
BA_ "U_V710_MY2023_Rx" SG_ 945 PrkLckCtlMsgTxt_D2_Rq 1;
BA_ "U_P702_MY2024_Rx" SG_ 945 PrkLckCtlMsgTxt_D2_Rq 1;
BA_ "WakeupSignal" SG_ 945 PwLoApim_T_Actl 1;
BA_ "U_P708_MY2023_Rx" SG_ 945 PwLoApim_T_Actl 1;
BA_ "U_V710_MY2023_Rx" SG_ 945 PwLoApim_T_Actl 1;
BA_ "U_P702_MY2024_Rx" SG_ 945 PwLoApim_T_Actl 1;
BA_ "U_P708_MY2023_Rx" SG_ 945 KeyPadCodeDgt7_D_Dsply 1;
BA_ "WakeupSignal" SG_ 945 KeyPadCodeDgt6_D_Dsply 1;
BA_ "U_P708_MY2023_Rx" SG_ 945 KeyPadCodeDgt6_D_Dsply 1;
BA_ "WakeupSignal" SG_ 945 KeyPadCodeDgt5_D_Dsply 1;
BA_ "U_P708_MY2023_Rx" SG_ 945 KeyPadCodeDgt5_D_Dsply 1;
BA_ "WakeupSignal" SG_ 945 KeyPadCodeDgt4_D_Dsply 1;
BA_ "U_P708_MY2023_Rx" SG_ 945 KeyPadCodeDgt4_D_Dsply 1;
BA_ "WakeupSignal" SG_ 945 KeyPadCodeDgt3_D_Dsply 1;
BA_ "U_P708_MY2023_Rx" SG_ 945 KeyPadCodeDgt3_D_Dsply 1;
BA_ "WakeupSignal" SG_ 945 KeyPadCodeDgt2_D_Dsply 1;
BA_ "U_P708_MY2023_Rx" SG_ 945 KeyPadCodeDgt2_D_Dsply 1;
BA_ "WakeupSignal" SG_ 945 KeyPadCodeDgt1_D_Dsply 1;
BA_ "U_P708_MY2023_Rx" SG_ 945 KeyPadCodeDgt1_D_Dsply 1;
BA_ "U_P708_MY2023_Rx" SG_ 945 KeyOffMde_D_Actl 1;
BA_ "U_CDX707_MY2023_Rx" SG_ 945 KeyOffMde_D_Actl 1;
BA_ "U_CDX74X_MY2024_Rx" SG_ 945 KeyOffMde_D_Actl 1;
BA_ "U_V710_MY2023_Rx" SG_ 945 KeyOffMde_D_Actl 1;
BA_ "U_P702_MY2024_Rx" SG_ 945 KeyOffMde_D_Actl 1;
BA_ "U_V713N_MY2022_Rx" SG_ 945 KeyOffMde_D_Actl 1;
BA_ "U_V713AV_MY2022_Rx" SG_ 945 KeyOffMde_D_Actl 1;
BA_ "U_V713N_MY2022_Rx" SG_ 945 PrkLckCtlLatch_B_Rq 1;
BA_ "U_V710_MY2023_Rx" SG_ 945 PrkLckCtlLatch_B_Rq 1;
BA_ "U_V713AV_MY2022_Rx" SG_ 945 PrkLckCtlLatch_B_Rq 1;
BA_ "U_P708_MY2023_Rx" SG_ 945 PrkLckCtlLatch_B_Rq 1;
BA_ "U_P702_MY2024_Rx" SG_ 945 PrkLckCtlLatch_B_Rq 1;
BA_ "GenSigSendType" SG_ 740 EmgcyAsstActv_D_Stat 3;
BA_ "U_V713N_MY2022_Tx" SG_ 740 EmgcyAsstActv_D_Stat 1;
BA_ "U_V713AV_MY2022_Tx" SG_ 740 EmgcyAsstActv_D_Stat 1;
BA_ "U_P708_MY2023_Tx" SG_ 740 EmgcyAsstActv_D_Stat 1;
BA_ "U_V710_MY2023_Tx" SG_ 740 EmgcyAsstActv_D_Stat 1;
BA_ "U_V713AV_MY2022_Rx" SG_ 1055 EcoCochInstNeg_B_Dsply 1;
BA_ "U_P708_MY2023_Rx" SG_ 1055 EcoCochInstNeg_B_Dsply 1;
BA_ "U_V710_MY2023_Rx" SG_ 1055 EcoCochInstNeg_B_Dsply 1;
BA_ "U_V713N_MY2022_Rx" SG_ 1055 EcoCochInstNeg_B_Dsply 1;
BA_ "U_P702_MY2024_Rx" SG_ 1055 EcoCochInstNeg_B_Dsply 1;
BA_ "GenSigStartValue" SG_ 1055 EcoCochShif_Pc_Dsply 255;
BA_ "U_V713N_MY2022_Rx" SG_ 1055 EcoCochShif_Pc_Dsply 1;
BA_ "U_V713AV_MY2022_Rx" SG_ 1055 EcoCochShif_Pc_Dsply 1;
BA_ "U_P708_MY2023_Rx" SG_ 1055 EcoCochShif_Pc_Dsply 1;
BA_ "U_V710_MY2023_Rx" SG_ 1055 EcoCochShif_Pc_Dsply 1;
BA_ "U_P702_MY2024_Rx" SG_ 1055 EcoCochShif_Pc_Dsply 1;
BA_ "GenSigStartValue" SG_ 1055 EcoCochInst_Pc_Dsply 100;
BA_ "U_V713N_MY2022_Rx" SG_ 1055 EcoCochInst_Pc_Dsply 1;
BA_ "U_V713AV_MY2022_Rx" SG_ 1055 EcoCochInst_Pc_Dsply 1;
BA_ "U_P708_MY2023_Rx" SG_ 1055 EcoCochInst_Pc_Dsply 1;
BA_ "U_V710_MY2023_Rx" SG_ 1055 EcoCochInst_Pc_Dsply 1;
BA_ "U_P702_MY2024_Rx" SG_ 1055 EcoCochInst_Pc_Dsply 1;
BA_ "GenSigStartValue" SG_ 1055 EcoCochIdlFuel_Pc_Dsply 255;
BA_ "U_V713N_MY2022_Rx" SG_ 1055 EcoCochIdlFuel_Pc_Dsply 1;
BA_ "U_V713AV_MY2022_Rx" SG_ 1055 EcoCochIdlFuel_Pc_Dsply 1;
BA_ "U_P708_MY2023_Rx" SG_ 1055 EcoCochIdlFuel_Pc_Dsply 1;
BA_ "U_V710_MY2023_Rx" SG_ 1055 EcoCochIdlFuel_Pc_Dsply 1;
BA_ "U_P702_MY2024_Rx" SG_ 1055 EcoCochIdlFuel_Pc_Dsply 1;
BA_ "GenSigStartValue" SG_ 1055 EcoCochDecel_Pc_Dsply 255;
BA_ "U_V713N_MY2022_Rx" SG_ 1055 EcoCochDecel_Pc_Dsply 1;
BA_ "U_V713AV_MY2022_Rx" SG_ 1055 EcoCochDecel_Pc_Dsply 1;
BA_ "U_P708_MY2023_Rx" SG_ 1055 EcoCochDecel_Pc_Dsply 1;
BA_ "U_V710_MY2023_Rx" SG_ 1055 EcoCochDecel_Pc_Dsply 1;
BA_ "U_P702_MY2024_Rx" SG_ 1055 EcoCochDecel_Pc_Dsply 1;
BA_ "GenSigStartValue" SG_ 1055 EcoCochCrus_Pc_Dsply 255;
BA_ "U_V713N_MY2022_Rx" SG_ 1055 EcoCochCrus_Pc_Dsply 1;
BA_ "U_V713AV_MY2022_Rx" SG_ 1055 EcoCochCrus_Pc_Dsply 1;
BA_ "U_P708_MY2023_Rx" SG_ 1055 EcoCochCrus_Pc_Dsply 1;
BA_ "U_V710_MY2023_Rx" SG_ 1055 EcoCochCrus_Pc_Dsply 1;
BA_ "U_P702_MY2024_Rx" SG_ 1055 EcoCochCrus_Pc_Dsply 1;
BA_ "GenSigStartValue" SG_ 1055 EcoCochA_Pc_Dsply 255;
BA_ "U_V713N_MY2022_Rx" SG_ 1055 EcoCochA_Pc_Dsply 1;
BA_ "U_V713AV_MY2022_Rx" SG_ 1055 EcoCochA_Pc_Dsply 1;
BA_ "U_P708_MY2023_Rx" SG_ 1055 EcoCochA_Pc_Dsply 1;
BA_ "U_V710_MY2023_Rx" SG_ 1055 EcoCochA_Pc_Dsply 1;
BA_ "U_P702_MY2024_Rx" SG_ 1055 EcoCochA_Pc_Dsply 1;
BA_ "U_V713N_MY2022_Rx" SG_ 360 GsmSrvcRqd_B_Rq 1;
BA_ "U_P708_MY2023_Rx" SG_ 360 GsmSrvcRqd_B_Rq 1;
BA_ "U_V710_MY2023_Rx" SG_ 360 GsmSrvcRqd_B_Rq 1;
BA_ "U_P702_MY2024_Rx" SG_ 360 GsmSrvcRqd_B_Rq 1;
BA_ "GenSigSendType" SG_ 1839 TesterPhysicalResACM 3;
BA_ "U_V713N_MY2022_Tx" SG_ 1839 TesterPhysicalResACM 1;
BA_ "U_V713AV_MY2022_Tx" SG_ 1839 TesterPhysicalResACM 1;
BA_ "U_P708_MY2023_Tx" SG_ 1839 TesterPhysicalResACM 1;
BA_ "U_V710_MY2023_Tx" SG_ 1839 TesterPhysicalResACM 1;
BA_ "GenSigSendType" SG_ 1831 TesterPhysicalReqACM 3;
BA_ "U_V713N_MY2022_Rx" SG_ 1831 TesterPhysicalReqACM 1;
BA_ "U_V713AV_MY2022_Rx" SG_ 1831 TesterPhysicalReqACM 1;
BA_ "U_P708_MY2023_Rx" SG_ 1831 TesterPhysicalReqACM 1;
BA_ "U_V710_MY2023_Rx" SG_ 1831 TesterPhysicalReqACM 1;
BA_ "GenSigStartValue" SG_ 1056 VehVActlBrk_No_Corr 254;
BA_ "U_V710_MY2023_Rx" SG_ 1056 AutoEpbButtnOn_B_Stat 1;
BA_ "U_P708_MY2023_Rx" SG_ 1056 AutoEpbButtnOn_B_Stat 1;
BA_ "U_P702_MY2024_Rx" SG_ 1056 AutoEpbButtnOn_B_Stat 1;
BA_ "U_V710_MY2023_Rx" SG_ 1056 AutoEpbMsgTxt_D_Rq 1;
BA_ "U_P708_MY2023_Rx" SG_ 1056 AutoEpbMsgTxt_D_Rq 1;
BA_ "U_P702_MY2024_Rx" SG_ 1056 AutoEpbMsgTxt_D_Rq 1;
BA_ "U_V710_MY2023_Rx" SG_ 1056 AutoEpbDsply_D_Stat 1;
BA_ "U_P708_MY2023_Rx" SG_ 1056 AutoEpbDsply_D_Stat 1;
BA_ "U_P702_MY2024_Rx" SG_ 1056 AutoEpbDsply_D_Stat 1;
BA_ "U_V713N_MY2022_Rx" SG_ 1056 SelDrvMdePos12_B_Avail 1;
BA_ "U_V713AV_MY2022_Rx" SG_ 1056 SelDrvMdePos12_B_Avail 1;
BA_ "U_P708_MY2023_Rx" SG_ 1056 SelDrvMdePos12_B_Avail 1;
BA_ "U_V710_MY2023_Rx" SG_ 1056 SelDrvMdePos12_B_Avail 1;
BA_ "U_P702_MY2024_Rx" SG_ 1056 SelDrvMdePos12_B_Avail 1;
BA_ "U_V713N_MY2022_Rx" SG_ 1056 SelDrvMdePos11_B_Avail 1;
BA_ "U_V713AV_MY2022_Rx" SG_ 1056 SelDrvMdePos11_B_Avail 1;
BA_ "U_P708_MY2023_Rx" SG_ 1056 SelDrvMdePos11_B_Avail 1;
BA_ "U_V710_MY2023_Rx" SG_ 1056 SelDrvMdePos11_B_Avail 1;
BA_ "U_P702_MY2024_Rx" SG_ 1056 SelDrvMdePos11_B_Avail 1;
BA_ "U_V713N_MY2022_Rx" SG_ 1056 SelDrvMdePos10_B_Avail 1;
BA_ "U_V713AV_MY2022_Rx" SG_ 1056 SelDrvMdePos10_B_Avail 1;
BA_ "U_P708_MY2023_Rx" SG_ 1056 SelDrvMdePos10_B_Avail 1;
BA_ "U_V710_MY2023_Rx" SG_ 1056 SelDrvMdePos10_B_Avail 1;
BA_ "U_P702_MY2024_Rx" SG_ 1056 SelDrvMdePos10_B_Avail 1;
BA_ "U_V713N_MY2022_Rx" SG_ 1056 SelDrvMdePos09_B_Avail 1;
BA_ "U_V713AV_MY2022_Rx" SG_ 1056 SelDrvMdePos09_B_Avail 1;
BA_ "U_P708_MY2023_Rx" SG_ 1056 SelDrvMdePos09_B_Avail 1;
BA_ "U_V710_MY2023_Rx" SG_ 1056 SelDrvMdePos09_B_Avail 1;
BA_ "U_P702_MY2024_Rx" SG_ 1056 SelDrvMdePos09_B_Avail 1;
BA_ "U_V713N_MY2022_Rx" SG_ 1056 SelDrvMdePos08_B_Avail 1;
BA_ "U_V713AV_MY2022_Rx" SG_ 1056 SelDrvMdePos08_B_Avail 1;
BA_ "U_P708_MY2023_Rx" SG_ 1056 SelDrvMdePos08_B_Avail 1;
BA_ "U_V710_MY2023_Rx" SG_ 1056 SelDrvMdePos08_B_Avail 1;
BA_ "U_P702_MY2024_Rx" SG_ 1056 SelDrvMdePos08_B_Avail 1;
BA_ "U_V713N_MY2022_Rx" SG_ 1056 SelDrvMdePos07_B_Avail 1;
BA_ "U_V713AV_MY2022_Rx" SG_ 1056 SelDrvMdePos07_B_Avail 1;
BA_ "U_P708_MY2023_Rx" SG_ 1056 SelDrvMdePos07_B_Avail 1;
BA_ "U_V710_MY2023_Rx" SG_ 1056 SelDrvMdePos07_B_Avail 1;
BA_ "U_P702_MY2024_Rx" SG_ 1056 SelDrvMdePos07_B_Avail 1;
BA_ "U_V713N_MY2022_Rx" SG_ 1056 SelDrvMdePos06_B_Avail 1;
BA_ "U_V713AV_MY2022_Rx" SG_ 1056 SelDrvMdePos06_B_Avail 1;
BA_ "U_P708_MY2023_Rx" SG_ 1056 SelDrvMdePos06_B_Avail 1;
BA_ "U_V710_MY2023_Rx" SG_ 1056 SelDrvMdePos06_B_Avail 1;
BA_ "U_P702_MY2024_Rx" SG_ 1056 SelDrvMdePos06_B_Avail 1;
BA_ "U_V713N_MY2022_Rx" SG_ 1056 SelDrvMdePos05_B_Avail 1;
BA_ "U_V713AV_MY2022_Rx" SG_ 1056 SelDrvMdePos05_B_Avail 1;
BA_ "U_P708_MY2023_Rx" SG_ 1056 SelDrvMdePos05_B_Avail 1;
BA_ "U_V710_MY2023_Rx" SG_ 1056 SelDrvMdePos05_B_Avail 1;
BA_ "U_P702_MY2024_Rx" SG_ 1056 SelDrvMdePos05_B_Avail 1;
BA_ "U_V713N_MY2022_Rx" SG_ 1056 SelDrvMdePos04_B_Avail 1;
BA_ "U_V713AV_MY2022_Rx" SG_ 1056 SelDrvMdePos04_B_Avail 1;
BA_ "U_P708_MY2023_Rx" SG_ 1056 SelDrvMdePos04_B_Avail 1;
BA_ "U_V710_MY2023_Rx" SG_ 1056 SelDrvMdePos04_B_Avail 1;
BA_ "U_P702_MY2024_Rx" SG_ 1056 SelDrvMdePos04_B_Avail 1;
BA_ "U_V713N_MY2022_Rx" SG_ 1056 SelDrvMdePos03_B_Avail 1;
BA_ "U_V713AV_MY2022_Rx" SG_ 1056 SelDrvMdePos03_B_Avail 1;
BA_ "U_P708_MY2023_Rx" SG_ 1056 SelDrvMdePos03_B_Avail 1;
BA_ "U_V710_MY2023_Rx" SG_ 1056 SelDrvMdePos03_B_Avail 1;
BA_ "U_P702_MY2024_Rx" SG_ 1056 SelDrvMdePos03_B_Avail 1;
BA_ "U_V713N_MY2022_Rx" SG_ 1056 SelDrvMdePos02_B_Avail 1;
BA_ "U_V713AV_MY2022_Rx" SG_ 1056 SelDrvMdePos02_B_Avail 1;
BA_ "U_P708_MY2023_Rx" SG_ 1056 SelDrvMdePos02_B_Avail 1;
BA_ "U_V710_MY2023_Rx" SG_ 1056 SelDrvMdePos02_B_Avail 1;
BA_ "U_P702_MY2024_Rx" SG_ 1056 SelDrvMdePos02_B_Avail 1;
BA_ "U_V713N_MY2022_Rx" SG_ 1056 SelDrvMdePos01_B_Avail 1;
BA_ "U_V713AV_MY2022_Rx" SG_ 1056 SelDrvMdePos01_B_Avail 1;
BA_ "U_P708_MY2023_Rx" SG_ 1056 SelDrvMdePos01_B_Avail 1;
BA_ "U_V710_MY2023_Rx" SG_ 1056 SelDrvMdePos01_B_Avail 1;
BA_ "U_P702_MY2024_Rx" SG_ 1056 SelDrvMdePos01_B_Avail 1;
BA_ "U_V710_MY2023_Rx" SG_ 1056 SelDrvMdeMsgTxt2_D_Rq 1;
BA_ "U_P708_MY2023_Rx" SG_ 1056 SelDrvMdeMsgTxt2_D_Rq 1;
BA_ "U_P702_MY2024_Rx" SG_ 1056 SelDrvMdeMsgTxt2_D_Rq 1;
BA_ "GenSigStartValue" SG_ 1056 ActvDrvMde_D2_Stat 31;
BA_ "U_V713N_MY2022_Rx" SG_ 1056 ActvDrvMde_D2_Stat 1;
BA_ "U_V713AV_MY2022_Rx" SG_ 1056 ActvDrvMde_D2_Stat 1;
BA_ "U_P708_MY2023_Rx" SG_ 1056 ActvDrvMde_D2_Stat 1;
BA_ "U_V710_MY2023_Rx" SG_ 1056 ActvDrvMde_D2_Stat 1;
BA_ "U_P702_MY2024_Rx" SG_ 1056 ActvDrvMde_D2_Stat 1;
BA_ "GenSigStartValue" SG_ 1056 SelDrvMde_D2_Rq 31;
BA_ "U_V713N_MY2022_Rx" SG_ 1056 SelDrvMde_D2_Rq 1;
BA_ "U_V713AV_MY2022_Rx" SG_ 1056 SelDrvMde_D2_Rq 1;
BA_ "U_P708_MY2023_Rx" SG_ 1056 SelDrvMde_D2_Rq 1;
BA_ "U_V710_MY2023_Rx" SG_ 1056 SelDrvMde_D2_Rq 1;
BA_ "U_P702_MY2024_Rx" SG_ 1056 SelDrvMde_D2_Rq 1;
BA_ "GenSigStartValue" SG_ 1056 AwdMde_D_RqBrk 5;
BA_ "U_V713N_MY2022_Rx" SG_ 1056 SelDrvMdeMsgTxt_D_Rq 1;
BA_ "U_V713AV_MY2022_Rx" SG_ 1056 SelDrvMdeMsgTxt_D_Rq 1;
BA_ "U_P708_MY2023_Rx" SG_ 1056 SelDrvMdeMsgTxt_D_Rq 1;
BA_ "U_V710_MY2023_Rx" SG_ 1056 SelDrvMdeMsgTxt_D_Rq 1;
BA_ "U_P702_MY2024_Rx" SG_ 1056 SelDrvMdeMsgTxt_D_Rq 1;
BA_ "U_V713N_MY2022_Rx" SG_ 1056 SelDrvMde_D_Stat 1;
BA_ "U_V713AV_MY2022_Rx" SG_ 1056 SelDrvMde_D_Stat 1;
BA_ "U_P708_MY2023_Rx" SG_ 1056 SelDrvMde_D_Stat 1;
BA_ "U_V710_MY2023_Rx" SG_ 1056 SelDrvMde_D_Stat 1;
BA_ "U_P702_MY2024_Rx" SG_ 1056 SelDrvMde_D_Stat 1;
BA_ "U_P702_MY2024_Rx" SG_ 1060 EngExhBrkLvl_Pc_Dsply 1;
BA_ "U_V713N_MY2022_Rx" SG_ 1060 FuelLvl_Pc_DsplyEng 1;
BA_ "U_V713AV_MY2022_Rx" SG_ 1060 FuelLvl_Pc_DsplyEng 1;
BA_ "U_P708_MY2023_Rx" SG_ 1060 FuelLvl_Pc_DsplyEng 1;
BA_ "U_V710_MY2023_Rx" SG_ 1060 FuelLvl_Pc_DsplyEng 1;
BA_ "U_P702_MY2024_Rx" SG_ 1060 FuelLvl_Pc_DsplyEng 1;
BA_ "GenSigSendType" SG_ 1060 FuelLvlWarn_D_ActlEng 3;
BA_ "U_V713N_MY2022_Rx" SG_ 1060 FuelLvlWarn_D_ActlEng 1;
BA_ "U_V713AV_MY2022_Rx" SG_ 1060 FuelLvlWarn_D_ActlEng 1;
BA_ "U_P708_MY2023_Rx" SG_ 1060 FuelLvlWarn_D_ActlEng 1;
BA_ "U_V710_MY2023_Rx" SG_ 1060 FuelLvlWarn_D_ActlEng 1;
BA_ "U_P702_MY2024_Rx" SG_ 1060 FuelLvlWarn_D_ActlEng 1;
BA_ "U_V713N_MY2022_Rx" SG_ 1060 FuelRange_L_DsplyEng 1;
BA_ "U_V713AV_MY2022_Rx" SG_ 1060 FuelRange_L_DsplyEng 1;
BA_ "U_P708_MY2023_Rx" SG_ 1060 FuelRange_L_DsplyEng 1;
BA_ "U_V710_MY2023_Rx" SG_ 1060 FuelRange_L_DsplyEng 1;
BA_ "U_P702_MY2024_Rx" SG_ 1060 FuelRange_L_DsplyEng 1;
BA_ "GenSigSendType" SG_ 1060 RearDiffOilTeWarn_B_Rq 3;
BA_ "U_V713N_MY2022_Rx" SG_ 1060 RearDiffOilTeWarn_B_Rq 1;
BA_ "U_V713AV_MY2022_Rx" SG_ 1060 RearDiffOilTeWarn_B_Rq 1;
BA_ "U_P708_MY2023_Rx" SG_ 1060 RearDiffOilTeWarn_B_Rq 1;
BA_ "U_V710_MY2023_Rx" SG_ 1060 RearDiffOilTeWarn_B_Rq 1;
BA_ "U_P702_MY2024_Rx" SG_ 1060 RearDiffOilTeWarn_B_Rq 1;
BA_ "U_V713N_MY2022_Rx" SG_ 1060 EngMxTqCurr_Pc_Dsply 1;
BA_ "U_V713AV_MY2022_Rx" SG_ 1060 EngMxTqCurr_Pc_Dsply 1;
BA_ "U_P708_MY2023_Rx" SG_ 1060 EngMxTqCurr_Pc_Dsply 1;
BA_ "U_V710_MY2023_Rx" SG_ 1060 EngMxTqCurr_Pc_Dsply 1;
BA_ "U_P702_MY2024_Rx" SG_ 1060 EngMxTqCurr_Pc_Dsply 1;
BA_ "GenSigStartValue" SG_ 1060 EngExhMdeQuiet_D_Stat 2;
BA_ "GenSigSendType" SG_ 1060 EngExhMdeQuiet_D_Stat 3;
BA_ "U_V713N_MY2022_Rx" SG_ 1060 EngExhMdeQuiet_D_Stat 1;
BA_ "U_V713AV_MY2022_Rx" SG_ 1060 EngExhMdeQuiet_D_Stat 1;
BA_ "U_P708_MY2023_Rx" SG_ 1060 EngExhMdeQuiet_D_Stat 1;
BA_ "U_V710_MY2023_Rx" SG_ 1060 EngExhMdeQuiet_D_Stat 1;
BA_ "U_P702_MY2024_Rx" SG_ 1060 EngExhMdeQuiet_D_Stat 1;
BA_ "GenSigStartValue" SG_ 1060 RearDiffOil_Te_Actl 77;
BA_ "U_V713N_MY2022_Rx" SG_ 1060 RearDiffOil_Te_Actl 1;
BA_ "U_V713AV_MY2022_Rx" SG_ 1060 RearDiffOil_Te_Actl 1;
BA_ "U_V710_MY2023_Rx" SG_ 1060 RearDiffOil_Te_Actl 1;
BA_ "U_P708_MY2023_Rx" SG_ 1060 RearDiffOil_Te_Actl 1;
BA_ "U_P702_MY2024_Rx" SG_ 1060 RearDiffOil_Te_Actl 1;
BA_ "GenSigSendType" SG_ 1060 BpedDrvMsgTxt_B_Dsply 3;
BA_ "U_V713N_MY2022_Rx" SG_ 1060 BpedDrvMsgTxt_B_Dsply 1;
BA_ "U_V713AV_MY2022_Rx" SG_ 1060 BpedDrvMsgTxt_B_Dsply 1;
BA_ "U_P708_MY2023_Rx" SG_ 1060 BpedDrvMsgTxt_B_Dsply 1;
BA_ "U_V710_MY2023_Rx" SG_ 1060 BpedDrvMsgTxt_B_Dsply 1;
BA_ "U_P702_MY2024_Rx" SG_ 1060 BpedDrvMsgTxt_B_Dsply 1;
BA_ "GenSigSendType" SG_ 1060 SelDrvMdePt_D_Stat 3;
BA_ "U_V713N_MY2022_Rx" SG_ 132 GlblClkYr_No_Actl 1;
BA_ "U_V713AV_MY2022_Rx" SG_ 132 GlblClkYr_No_Actl 1;
BA_ "U_P708_MY2023_Rx" SG_ 132 GlblClkYr_No_Actl 1;
BA_ "U_V710_MY2023_Rx" SG_ 132 GlblClkYr_No_Actl 1;
BA_ "U_P702_MY2024_Rx" SG_ 132 GlblClkYr_No_Actl 1;
BA_ "U_CDX74X_MY2024_Rx" SG_ 132 GlblClkYr_No_Actl 1;
BA_ "U_V713N_MY2022_Rx" SG_ 132 GlblClkScnd_No_Actl 1;
BA_ "U_V713AV_MY2022_Rx" SG_ 132 GlblClkScnd_No_Actl 1;
BA_ "U_P708_MY2023_Rx" SG_ 132 GlblClkScnd_No_Actl 1;
BA_ "U_P702_MY2024_Rx" SG_ 132 GlblClkScnd_No_Actl 1;
BA_ "U_CDX74X_MY2024_Rx" SG_ 132 GlblClkScnd_No_Actl 1;
BA_ "U_V710_MY2023_Rx" SG_ 132 GlblClkScnd_No_Actl 1;
BA_ "U_V713N_MY2022_Rx" SG_ 132 GlblClkMnte_No_Actl 1;
BA_ "U_V713AV_MY2022_Rx" SG_ 132 GlblClkMnte_No_Actl 1;
BA_ "U_P708_MY2023_Rx" SG_ 132 GlblClkMnte_No_Actl 1;
BA_ "U_V710_MY2023_Rx" SG_ 132 GlblClkMnte_No_Actl 1;
BA_ "U_P702_MY2024_Rx" SG_ 132 GlblClkMnte_No_Actl 1;
BA_ "U_CDX74X_MY2024_Rx" SG_ 132 GlblClkMnte_No_Actl 1;
BA_ "U_V713N_MY2022_Rx" SG_ 132 GlblClkHr_No_Actl 1;
BA_ "U_V713AV_MY2022_Rx" SG_ 132 GlblClkHr_No_Actl 1;
BA_ "U_P708_MY2023_Rx" SG_ 132 GlblClkHr_No_Actl 1;
BA_ "U_V710_MY2023_Rx" SG_ 132 GlblClkHr_No_Actl 1;
BA_ "U_P702_MY2024_Rx" SG_ 132 GlblClkHr_No_Actl 1;
BA_ "U_CDX74X_MY2024_Rx" SG_ 132 GlblClkHr_No_Actl 1;
BA_ "U_V713N_MY2022_Rx" SG_ 132 GlblClkDay_No_Actl 1;
BA_ "U_V713AV_MY2022_Rx" SG_ 132 GlblClkDay_No_Actl 1;
BA_ "U_P708_MY2023_Rx" SG_ 132 GlblClkDay_No_Actl 1;
BA_ "U_V710_MY2023_Rx" SG_ 132 GlblClkDay_No_Actl 1;
BA_ "U_P702_MY2024_Rx" SG_ 132 GlblClkDay_No_Actl 1;
BA_ "U_CDX74X_MY2024_Rx" SG_ 132 GlblClkDay_No_Actl 1;
BA_ "WakeupSignal" SG_ 135 McGlblClkDay_No_Rq 1;
BA_ "U_V713N_MY2022_Tx" SG_ 135 McGlblClkDay_No_Rq 1;
BA_ "U_V713AV_MY2022_Tx" SG_ 135 McGlblClkDay_No_Rq 1;
BA_ "U_V710_MY2023_Tx" SG_ 135 McGlblClkDay_No_Rq 1;
BA_ "WakeupSignal" SG_ 135 McGlblClkYr_No_Rq 1;
BA_ "U_V713N_MY2022_Tx" SG_ 135 McGlblClkYr_No_Rq 1;
BA_ "U_V713AV_MY2022_Tx" SG_ 135 McGlblClkYr_No_Rq 1;
BA_ "U_V710_MY2023_Tx" SG_ 135 McGlblClkYr_No_Rq 1;
BA_ "WakeupSignal" SG_ 135 McGlblClkScnd_No_Rq 1;
BA_ "U_V713N_MY2022_Tx" SG_ 135 McGlblClkScnd_No_Rq 1;
BA_ "U_V713AV_MY2022_Tx" SG_ 135 McGlblClkScnd_No_Rq 1;
BA_ "U_V710_MY2023_Tx" SG_ 135 McGlblClkScnd_No_Rq 1;
BA_ "WakeupSignal" SG_ 135 McGlblClkMnte_No_Rq 1;
BA_ "U_V713N_MY2022_Tx" SG_ 135 McGlblClkMnte_No_Rq 1;
BA_ "U_V713AV_MY2022_Tx" SG_ 135 McGlblClkMnte_No_Rq 1;
BA_ "U_V710_MY2023_Tx" SG_ 135 McGlblClkMnte_No_Rq 1;
BA_ "WakeupSignal" SG_ 135 McGlblClkHr_No_Rq 1;
BA_ "U_V713N_MY2022_Tx" SG_ 135 McGlblClkHr_No_Rq 1;
BA_ "U_V713AV_MY2022_Tx" SG_ 135 McGlblClkHr_No_Rq 1;
BA_ "U_V710_MY2023_Tx" SG_ 135 McGlblClkHr_No_Rq 1;
BA_ "WakeupSignal" SG_ 135 McGlblClkAdj_B_Rq 1;
BA_ "GenSigSendType" SG_ 135 McGlblClkAdj_B_Rq 3;
BA_ "U_V713N_MY2022_Tx" SG_ 135 McGlblClkAdj_B_Rq 1;
BA_ "U_V713AV_MY2022_Tx" SG_ 135 McGlblClkAdj_B_Rq 1;
BA_ "U_V710_MY2023_Tx" SG_ 135 McGlblClkAdj_B_Rq 1;
BA_ "WakeupSignal" SG_ 134 DispGlblClkYr_No_Rq 1;
BA_ "U_V713N_MY2022_Rx" SG_ 134 DispGlblClkYr_No_Rq 1;
BA_ "U_V713AV_MY2022_Rx" SG_ 134 DispGlblClkYr_No_Rq 1;
BA_ "U_V710_MY2023_Tx" SG_ 134 DispGlblClkYr_No_Rq 1;
BA_ "U_P708_MY2023_Tx" SG_ 134 DispGlblClkYr_No_Rq 1;
BA_ "U_P702_MY2024_Tx" SG_ 134 DispGlblClkYr_No_Rq 1;
BA_ "WakeupSignal" SG_ 134 DispGlblClkScnd_No_Rq 1;
BA_ "U_V713N_MY2022_Rx" SG_ 134 DispGlblClkScnd_No_Rq 1;
BA_ "U_V713AV_MY2022_Rx" SG_ 134 DispGlblClkScnd_No_Rq 1;
BA_ "U_V710_MY2023_Tx" SG_ 134 DispGlblClkScnd_No_Rq 1;
BA_ "U_P708_MY2023_Tx" SG_ 134 DispGlblClkScnd_No_Rq 1;
BA_ "U_P702_MY2024_Tx" SG_ 134 DispGlblClkScnd_No_Rq 1;
BA_ "WakeupSignal" SG_ 134 DispGlblClkMnte_No_Rq 1;
BA_ "U_V713N_MY2022_Rx" SG_ 134 DispGlblClkMnte_No_Rq 1;
BA_ "U_V713AV_MY2022_Rx" SG_ 134 DispGlblClkMnte_No_Rq 1;
BA_ "U_V710_MY2023_Tx" SG_ 134 DispGlblClkMnte_No_Rq 1;
BA_ "U_P708_MY2023_Tx" SG_ 134 DispGlblClkMnte_No_Rq 1;
BA_ "U_P702_MY2024_Tx" SG_ 134 DispGlblClkMnte_No_Rq 1;
BA_ "WakeupSignal" SG_ 134 DispGlblClkHr_No_Rq 1;
BA_ "U_V713N_MY2022_Rx" SG_ 134 DispGlblClkHr_No_Rq 1;
BA_ "U_V713AV_MY2022_Rx" SG_ 134 DispGlblClkHr_No_Rq 1;
BA_ "U_V710_MY2023_Tx" SG_ 134 DispGlblClkHr_No_Rq 1;
BA_ "U_P708_MY2023_Tx" SG_ 134 DispGlblClkHr_No_Rq 1;
BA_ "U_P702_MY2024_Tx" SG_ 134 DispGlblClkHr_No_Rq 1;
BA_ "WakeupSignal" SG_ 134 DispGlblClkDay_No_Rq 1;
BA_ "U_V713N_MY2022_Rx" SG_ 134 DispGlblClkDay_No_Rq 1;
BA_ "U_V713AV_MY2022_Rx" SG_ 134 DispGlblClkDay_No_Rq 1;
BA_ "U_V710_MY2023_Tx" SG_ 134 DispGlblClkDay_No_Rq 1;
BA_ "U_P708_MY2023_Tx" SG_ 134 DispGlblClkDay_No_Rq 1;
BA_ "U_P702_MY2024_Tx" SG_ 134 DispGlblClkDay_No_Rq 1;
BA_ "WakeupSignal" SG_ 134 DispGlblClkAdj_B_Rq 1;
BA_ "GenSigSendType" SG_ 134 DispGlblClkAdj_B_Rq 3;
BA_ "U_V713N_MY2022_Rx" SG_ 134 DispGlblClkAdj_B_Rq 1;
BA_ "U_V713AV_MY2022_Rx" SG_ 134 DispGlblClkAdj_B_Rq 1;
BA_ "U_P708_MY2023_Rx" SG_ 134 DispGlblClkAdj_B_Rq 1;
BA_ "U_V710_MY2023_Rx" SG_ 134 DispGlblClkAdj_B_Rq 1;
BA_ "U_V710_MY2023_Tx" SG_ 134 DispGlblClkAdj_B_Rq 1;
BA_ "U_P708_MY2023_Tx" SG_ 134 DispGlblClkAdj_B_Rq 1;
BA_ "U_P702_MY2024_Tx" SG_ 134 DispGlblClkAdj_B_Rq 1;
BA_ "GenSigSendType" SG_ 559 EhData2_No_Actl 1;
BA_ "U_P708_MY2023_Rx" SG_ 559 EhData2_No_Actl 1;
BA_ "U_P702_MY2024_Rx" SG_ 559 EhData2_No_Actl 1;
BA_ "U_V710_MY2023_Tx" SG_ 559 EhData2_No_Actl 1;
BA_ "U_P708_MY2023_Tx" SG_ 559 EhData2_No_Actl 1;
BA_ "U_P702_MY2024_Tx" SG_ 559 EhData2_No_Actl 1;
BA_ "GenSigSendType" SG_ 558 EhData1_No_Actl 1;
BA_ "U_P708_MY2023_Rx" SG_ 558 EhData1_No_Actl 1;
BA_ "U_P702_MY2024_Rx" SG_ 558 EhData1_No_Actl 1;
BA_ "U_V710_MY2023_Tx" SG_ 558 EhData1_No_Actl 1;
BA_ "U_P708_MY2023_Tx" SG_ 558 EhData1_No_Actl 1;
BA_ "U_P702_MY2024_Tx" SG_ 558 EhData1_No_Actl 1;
BA_ "U_P702_MY2024_Rx" SG_ 939 DrTgateMde_D_Stat 1;
BA_ "U_V713N_MY2022_Rx" SG_ 939 ResPrkAidSnsRlSide_D_Stat 1;
BA_ "U_V713AV_MY2022_Rx" SG_ 939 ResPrkAidSnsRlSide_D_Stat 1;
BA_ "U_V710_MY2023_Rx" SG_ 939 ResPrkAidSnsRlSide_D_Stat 1;
BA_ "U_P708_MY2023_Rx" SG_ 939 ResPrkAidSnsRlSide_D_Stat 1;
BA_ "U_P702_MY2024_Rx" SG_ 939 ResPrkAidSnsRlSide_D_Stat 1;
BA_ "U_V713N_MY2022_Rx" SG_ 939 SidePrkSnsR4_D_Stat 1;
BA_ "U_V713AV_MY2022_Rx" SG_ 939 SidePrkSnsR4_D_Stat 1;
BA_ "U_V710_MY2023_Rx" SG_ 939 SidePrkSnsR4_D_Stat 1;
BA_ "U_P708_MY2023_Rx" SG_ 939 SidePrkSnsR4_D_Stat 1;
BA_ "U_P702_MY2024_Rx" SG_ 939 SidePrkSnsR4_D_Stat 1;
BA_ "U_V713N_MY2022_Rx" SG_ 939 SidePrkSnsR3_D_Stat 1;
BA_ "U_V713AV_MY2022_Rx" SG_ 939 SidePrkSnsR3_D_Stat 1;
BA_ "U_V710_MY2023_Rx" SG_ 939 SidePrkSnsR3_D_Stat 1;
BA_ "U_P708_MY2023_Rx" SG_ 939 SidePrkSnsR3_D_Stat 1;
BA_ "U_P702_MY2024_Rx" SG_ 939 SidePrkSnsR3_D_Stat 1;
BA_ "U_V713N_MY2022_Rx" SG_ 939 SidePrkSnsL4_D_Stat 1;
BA_ "U_V713AV_MY2022_Rx" SG_ 939 SidePrkSnsL4_D_Stat 1;
BA_ "U_V710_MY2023_Rx" SG_ 939 SidePrkSnsL4_D_Stat 1;
BA_ "U_P708_MY2023_Rx" SG_ 939 SidePrkSnsL4_D_Stat 1;
BA_ "U_P702_MY2024_Rx" SG_ 939 SidePrkSnsL4_D_Stat 1;
BA_ "U_V713N_MY2022_Rx" SG_ 939 SidePrkSnsL3_D_Stat 1;
BA_ "U_V713AV_MY2022_Rx" SG_ 939 SidePrkSnsL3_D_Stat 1;
BA_ "U_V710_MY2023_Rx" SG_ 939 SidePrkSnsL3_D_Stat 1;
BA_ "U_P708_MY2023_Rx" SG_ 939 SidePrkSnsL3_D_Stat 1;
BA_ "U_P702_MY2024_Rx" SG_ 939 SidePrkSnsL3_D_Stat 1;
BA_ "U_V713N_MY2022_Rx" SG_ 939 PrkAidChime_D_Stat 1;
BA_ "U_V713AV_MY2022_Rx" SG_ 939 PrkAidChime_D_Stat 1;
BA_ "U_P708_MY2023_Rx" SG_ 939 PrkAidChime_D_Stat 1;
BA_ "U_V710_MY2023_Rx" SG_ 939 PrkAidChime_D_Stat 1;
BA_ "U_P702_MY2024_Rx" SG_ 939 PrkAidChime_D_Stat 1;
BA_ "U_V713N_MY2022_Rx" SG_ 939 PrkAidSnsRlCntr_D_Stat 1;
BA_ "U_V713AV_MY2022_Rx" SG_ 939 PrkAidSnsRlCntr_D_Stat 1;
BA_ "U_V710_MY2023_Rx" SG_ 939 PrkAidSnsRlCntr_D_Stat 1;
BA_ "U_P708_MY2023_Rx" SG_ 939 PrkAidSnsRlCntr_D_Stat 1;
BA_ "U_P702_MY2024_Rx" SG_ 939 PrkAidSnsRlCntr_D_Stat 1;
BA_ "U_V713N_MY2022_Rx" SG_ 939 PrkAidSnsRrCrnr_D_Stat 1;
BA_ "U_V713AV_MY2022_Rx" SG_ 939 PrkAidSnsRrCrnr_D_Stat 1;
BA_ "U_V710_MY2023_Rx" SG_ 939 PrkAidSnsRrCrnr_D_Stat 1;
BA_ "U_P708_MY2023_Rx" SG_ 939 PrkAidSnsRrCrnr_D_Stat 1;
BA_ "U_P702_MY2024_Rx" SG_ 939 PrkAidSnsRrCrnr_D_Stat 1;
BA_ "U_V713N_MY2022_Rx" SG_ 939 PrkAidSnsRrCntr_D_Stat 1;
BA_ "U_V713AV_MY2022_Rx" SG_ 939 PrkAidSnsRrCntr_D_Stat 1;
BA_ "U_V710_MY2023_Rx" SG_ 939 PrkAidSnsRrCntr_D_Stat 1;
BA_ "U_P708_MY2023_Rx" SG_ 939 PrkAidSnsRrCntr_D_Stat 1;
BA_ "U_P702_MY2024_Rx" SG_ 939 PrkAidSnsRrCntr_D_Stat 1;
BA_ "U_V713N_MY2022_Rx" SG_ 939 PrkAidSnsRlCrnr_D_Stat 1;
BA_ "U_V713AV_MY2022_Rx" SG_ 939 PrkAidSnsRlCrnr_D_Stat 1;
BA_ "U_V710_MY2023_Rx" SG_ 939 PrkAidSnsRlCrnr_D_Stat 1;
BA_ "U_P708_MY2023_Rx" SG_ 939 PrkAidSnsRlCrnr_D_Stat 1;
BA_ "U_P702_MY2024_Rx" SG_ 939 PrkAidSnsRlCrnr_D_Stat 1;
BA_ "U_V713N_MY2022_Rx" SG_ 939 PrkAidRear_D_Stat 1;
BA_ "U_V713AV_MY2022_Rx" SG_ 939 PrkAidRear_D_Stat 1;
BA_ "U_P708_MY2023_Rx" SG_ 939 PrkAidRear_D_Stat 1;
BA_ "U_V710_MY2023_Rx" SG_ 939 PrkAidRear_D_Stat 1;
BA_ "U_P702_MY2024_Rx" SG_ 939 PrkAidRear_D_Stat 1;
BA_ "U_V713N_MY2022_Rx" SG_ 939 PrkAidFront_D_Stat 1;
BA_ "U_V713AV_MY2022_Rx" SG_ 939 PrkAidFront_D_Stat 1;
BA_ "U_V710_MY2023_Rx" SG_ 939 PrkAidFront_D_Stat 1;
BA_ "U_P708_MY2023_Rx" SG_ 939 PrkAidFront_D_Stat 1;
BA_ "U_P702_MY2024_Rx" SG_ 939 PrkAidFront_D_Stat 1;
BA_ "U_V713N_MY2022_Rx" SG_ 939 PrkAid_D_Falt 1;
BA_ "U_V713AV_MY2022_Rx" SG_ 939 PrkAid_D_Falt 1;
BA_ "U_P708_MY2023_Rx" SG_ 939 PrkAid_D_Falt 1;
BA_ "U_V710_MY2023_Rx" SG_ 939 PrkAid_D_Falt 1;
BA_ "U_P702_MY2024_Rx" SG_ 939 PrkAid_D_Falt 1;
BA_ "U_V713N_MY2022_Rx" SG_ 939 ResPrkAidSnsRrSide_D_Stat 1;
BA_ "U_V713AV_MY2022_Rx" SG_ 939 ResPrkAidSnsRrSide_D_Stat 1;
BA_ "U_V710_MY2023_Rx" SG_ 939 ResPrkAidSnsRrSide_D_Stat 1;
BA_ "U_P708_MY2023_Rx" SG_ 939 ResPrkAidSnsRrSide_D_Stat 1;
BA_ "U_P702_MY2024_Rx" SG_ 939 ResPrkAidSnsRrSide_D_Stat 1;
BA_ "GenSigStartValue" SG_ 939 ApaBrk_A_Rq 255;
BA_ "U_V713N_MY2022_Rx" SG_ 938 SidePrkSnsR2_D_Stat 1;
BA_ "U_V713AV_MY2022_Rx" SG_ 938 SidePrkSnsR2_D_Stat 1;
BA_ "U_V710_MY2023_Rx" SG_ 938 SidePrkSnsR2_D_Stat 1;
BA_ "U_P708_MY2023_Rx" SG_ 938 SidePrkSnsR2_D_Stat 1;
BA_ "U_P702_MY2024_Rx" SG_ 938 SidePrkSnsR2_D_Stat 1;
BA_ "U_V713N_MY2022_Rx" SG_ 938 SidePrkSnsR1_D_Stat 1;
BA_ "U_V713AV_MY2022_Rx" SG_ 938 SidePrkSnsR1_D_Stat 1;
BA_ "U_V710_MY2023_Rx" SG_ 938 SidePrkSnsR1_D_Stat 1;
BA_ "U_P708_MY2023_Rx" SG_ 938 SidePrkSnsR1_D_Stat 1;
BA_ "U_P702_MY2024_Rx" SG_ 938 SidePrkSnsR1_D_Stat 1;
BA_ "U_V713N_MY2022_Rx" SG_ 938 SidePrkSnsL2_D_Stat 1;
BA_ "U_V713AV_MY2022_Rx" SG_ 938 SidePrkSnsL2_D_Stat 1;
BA_ "U_V710_MY2023_Rx" SG_ 938 SidePrkSnsL2_D_Stat 1;
BA_ "U_P708_MY2023_Rx" SG_ 938 SidePrkSnsL2_D_Stat 1;
BA_ "U_P702_MY2024_Rx" SG_ 938 SidePrkSnsL2_D_Stat 1;
BA_ "U_V713N_MY2022_Rx" SG_ 938 SidePrkSnsL1_D_Stat 1;
BA_ "U_V713AV_MY2022_Rx" SG_ 938 SidePrkSnsL1_D_Stat 1;
BA_ "U_V710_MY2023_Rx" SG_ 938 SidePrkSnsL1_D_Stat 1;
BA_ "U_P708_MY2023_Rx" SG_ 938 SidePrkSnsL1_D_Stat 1;
BA_ "U_P702_MY2024_Rx" SG_ 938 SidePrkSnsL1_D_Stat 1;
BA_ "U_V713N_MY2022_Rx" SG_ 938 ApaMde_D_Stat 1;
BA_ "U_V713AV_MY2022_Rx" SG_ 938 ApaMde_D_Stat 1;
BA_ "U_V710_MY2023_Rx" SG_ 938 ApaMde_D_Stat 1;
BA_ "U_P708_MY2023_Rx" SG_ 938 ApaMde_D_Stat 1;
BA_ "U_P702_MY2024_Rx" SG_ 938 ApaMde_D_Stat 1;
BA_ "GenSigStartValue" SG_ 938 ApaActvSd_D_Actl 1;
BA_ "U_V713N_MY2022_Rx" SG_ 938 ApaActvSd_D_Actl 1;
BA_ "U_V713AV_MY2022_Rx" SG_ 938 ApaActvSd_D_Actl 1;
BA_ "U_V710_MY2023_Rx" SG_ 938 ApaActvSd_D_Actl 1;
BA_ "U_P708_MY2023_Rx" SG_ 938 ApaActvSd_D_Actl 1;
BA_ "U_V713N_MY2022_Rx" SG_ 938 PrkAidSwtch_B_Stat 1;
BA_ "U_V713AV_MY2022_Rx" SG_ 938 PrkAidSwtch_B_Stat 1;
BA_ "U_P708_MY2023_Rx" SG_ 938 PrkAidSwtch_B_Stat 1;
BA_ "U_V710_MY2023_Rx" SG_ 938 PrkAidSwtch_B_Stat 1;
BA_ "U_P702_MY2024_Rx" SG_ 938 PrkAidSwtch_B_Stat 1;
BA_ "U_V713N_MY2022_Rx" SG_ 938 PrkAidMsgTxt_D_Rq 1;
BA_ "U_V713AV_MY2022_Rx" SG_ 938 PrkAidMsgTxt_D_Rq 1;
BA_ "U_P708_MY2023_Rx" SG_ 938 PrkAidMsgTxt_D_Rq 1;
BA_ "U_V710_MY2023_Rx" SG_ 938 PrkAidMsgTxt_D_Rq 1;
BA_ "U_P702_MY2024_Rx" SG_ 938 PrkAidMsgTxt_D_Rq 1;
BA_ "U_V710_MY2023_Rx" SG_ 938 ApaMde_D_Avail 1;
BA_ "U_P708_MY2023_Rx" SG_ 938 ApaMde_D_Avail 1;
BA_ "U_V713N_MY2022_Rx" SG_ 938 PrkAidSnsFrCrnr_D_Stat 1;
BA_ "U_V713AV_MY2022_Rx" SG_ 938 PrkAidSnsFrCrnr_D_Stat 1;
BA_ "U_V710_MY2023_Rx" SG_ 938 PrkAidSnsFrCrnr_D_Stat 1;
BA_ "U_P708_MY2023_Rx" SG_ 938 PrkAidSnsFrCrnr_D_Stat 1;
BA_ "U_P702_MY2024_Rx" SG_ 938 PrkAidSnsFrCrnr_D_Stat 1;
BA_ "U_V713N_MY2022_Rx" SG_ 938 PrkAidSnsFrCntr_D_Stat 1;
BA_ "U_V713AV_MY2022_Rx" SG_ 938 PrkAidSnsFrCntr_D_Stat 1;
BA_ "U_V710_MY2023_Rx" SG_ 938 PrkAidSnsFrCntr_D_Stat 1;
BA_ "U_P708_MY2023_Rx" SG_ 938 PrkAidSnsFrCntr_D_Stat 1;
BA_ "U_P702_MY2024_Rx" SG_ 938 PrkAidSnsFrCntr_D_Stat 1;
BA_ "U_V713N_MY2022_Rx" SG_ 938 PrkAidSnsFlCrnr_D_Stat 1;
BA_ "U_V713AV_MY2022_Rx" SG_ 938 PrkAidSnsFlCrnr_D_Stat 1;
BA_ "U_V710_MY2023_Rx" SG_ 938 PrkAidSnsFlCrnr_D_Stat 1;
BA_ "U_P708_MY2023_Rx" SG_ 938 PrkAidSnsFlCrnr_D_Stat 1;
BA_ "U_P702_MY2024_Rx" SG_ 938 PrkAidSnsFlCrnr_D_Stat 1;
BA_ "U_V713N_MY2022_Rx" SG_ 938 PrkAidSnsFlCntr_D_Stat 1;
BA_ "U_V713AV_MY2022_Rx" SG_ 938 PrkAidSnsFlCntr_D_Stat 1;
BA_ "U_V710_MY2023_Rx" SG_ 938 PrkAidSnsFlCntr_D_Stat 1;
BA_ "U_P708_MY2023_Rx" SG_ 938 PrkAidSnsFlCntr_D_Stat 1;
BA_ "U_P702_MY2024_Rx" SG_ 938 PrkAidSnsFlCntr_D_Stat 1;
BA_ "U_V713N_MY2022_Rx" SG_ 938 RpaChime_D_Rq 1;
BA_ "U_V713AV_MY2022_Rx" SG_ 938 RpaChime_D_Rq 1;
BA_ "U_P708_MY2023_Rx" SG_ 938 RpaChime_D_Rq 1;
BA_ "U_V710_MY2023_Rx" SG_ 938 RpaChime_D_Rq 1;
BA_ "U_P702_MY2024_Rx" SG_ 938 RpaChime_D_Rq 1;
BA_ "U_V713N_MY2022_Rx" SG_ 938 FpaChime_D_Rq 1;
BA_ "U_V713AV_MY2022_Rx" SG_ 938 FpaChime_D_Rq 1;
BA_ "U_P708_MY2023_Rx" SG_ 938 FpaChime_D_Rq 1;
BA_ "U_V710_MY2023_Rx" SG_ 938 FpaChime_D_Rq 1;
BA_ "U_P702_MY2024_Rx" SG_ 938 FpaChime_D_Rq 1;
BA_ "U_V713N_MY2022_Rx" SG_ 938 PrkAidAudioMute_B_Rq 1;
BA_ "U_V713AV_MY2022_Rx" SG_ 938 PrkAidAudioMute_B_Rq 1;
BA_ "U_P708_MY2023_Rx" SG_ 938 PrkAidAudioMute_B_Rq 1;
BA_ "U_V710_MY2023_Rx" SG_ 938 PrkAidAudioMute_B_Rq 1;
BA_ "U_P702_MY2024_Rx" SG_ 938 PrkAidAudioMute_B_Rq 1;
BA_ "U_V710_MY2023_Rx" SG_ 938 PrkBrkEl_B_RqFap 1;
BA_ "GenSigStartValue" SG_ 952 Tire_Press_IRR_Data 65533;
BA_ "U_V713N_MY2022_Rx" SG_ 952 Tire_Press_IRR_Data 1;
BA_ "U_V713AV_MY2022_Rx" SG_ 952 Tire_Press_IRR_Data 1;
BA_ "U_P708_MY2023_Rx" SG_ 952 Tire_Press_IRR_Data 1;
BA_ "U_V710_MY2023_Rx" SG_ 952 Tire_Press_IRR_Data 1;
BA_ "U_P702_MY2024_Rx" SG_ 952 Tire_Press_IRR_Data 1;
BA_ "GenSigStartValue" SG_ 952 Tire_Press_ILR_Data 65533;
BA_ "U_V713N_MY2022_Rx" SG_ 952 Tire_Press_ILR_Data 1;
BA_ "U_V713AV_MY2022_Rx" SG_ 952 Tire_Press_ILR_Data 1;
BA_ "U_P708_MY2023_Rx" SG_ 952 Tire_Press_ILR_Data 1;
BA_ "U_V710_MY2023_Rx" SG_ 952 Tire_Press_ILR_Data 1;
BA_ "U_P702_MY2024_Rx" SG_ 952 Tire_Press_ILR_Data 1;
BA_ "U_V710_MY2023_Rx" SG_ 845 SeatMasgPsngr_D_Stat 1;
BA_ "U_P708_MY2023_Rx" SG_ 845 SeatMasgPsngr_D_Stat 1;
BA_ "U_P702_MY2024_Rx" SG_ 845 SeatMasgPsngr_D_Stat 1;
BA_ "U_V710_MY2023_Rx" SG_ 845 SeatIntnsPsngr_D_Stat 1;
BA_ "U_P708_MY2023_Rx" SG_ 845 SeatIntnsPsngr_D_Stat 1;
BA_ "U_P702_MY2024_Rx" SG_ 845 SeatIntnsPsngr_D_Stat 1;
BA_ "U_V710_MY2023_Rx" SG_ 845 StmsLmbrPsgr_D_Stat 1;
BA_ "U_P708_MY2023_Rx" SG_ 845 StmsLmbrPsgr_D_Stat 1;
BA_ "U_P702_MY2024_Rx" SG_ 845 StmsLmbrPsgr_D_Stat 1;
BA_ "U_V710_MY2023_Rx" SG_ 845 StmsCshnPsgr_D_Stat 1;
BA_ "U_P708_MY2023_Rx" SG_ 845 StmsCshnPsgr_D_Stat 1;
BA_ "U_P702_MY2024_Rx" SG_ 845 StmsCshnPsgr_D_Stat 1;
BA_ "U_V710_MY2023_Rx" SG_ 845 SeatSwtchPsgr_B_Stat 1;
BA_ "U_P708_MY2023_Rx" SG_ 845 SeatSwtchPsgr_B_Stat 1;
BA_ "U_P702_MY2024_Rx" SG_ 845 SeatSwtchPsgr_B_Stat 1;
BA_ "U_V710_MY2023_Rx" SG_ 845 SeatPPsgr_B_Stat 1;
BA_ "U_P708_MY2023_Rx" SG_ 845 SeatPPsgr_B_Stat 1;
BA_ "U_P702_MY2024_Rx" SG_ 845 SeatPPsgr_B_Stat 1;
BA_ "U_V710_MY2023_Rx" SG_ 845 SeatFnPsgr_D_Stat 1;
BA_ "U_P708_MY2023_Rx" SG_ 845 SeatFnPsgr_D_Stat 1;
BA_ "U_P702_MY2024_Rx" SG_ 845 SeatFnPsgr_D_Stat 1;
BA_ "U_V710_MY2023_Rx" SG_ 845 PsgrMemFeedback_Rsp 1;
BA_ "U_P708_MY2023_Rx" SG_ 845 PsgrMemFeedback_Rsp 1;
BA_ "U_P702_MY2024_Rx" SG_ 845 PsgrMemFeedback_Rsp 1;
BA_ "GenSigStartValue" SG_ 1137 RngPerChrgLbl_L_Dsply 4093;
BA_ "U_V713N_MY2022_Rx" SG_ 1137 RngPerChrgLbl_L_Dsply 1;
BA_ "U_V713AV_MY2022_Rx" SG_ 1137 RngPerChrgLbl_L_Dsply 1;
BA_ "U_P708_MY2023_Rx" SG_ 1137 RngPerChrgLbl_L_Dsply 1;
BA_ "U_V710_MY2023_Rx" SG_ 1137 RngPerChrgLbl_L_Dsply 1;
BA_ "U_P702_MY2024_Rx" SG_ 1137 RngPerChrgLbl_L_Dsply 1;
BA_ "GenSigStartValue" SG_ 1137 RngPerChrgAvg_L_Dsply 4093;
BA_ "U_V713N_MY2022_Rx" SG_ 1137 RngPerChrgAvg_L_Dsply 1;
BA_ "U_V713AV_MY2022_Rx" SG_ 1137 RngPerChrgAvg_L_Dsply 1;
BA_ "U_V710_MY2023_Rx" SG_ 1137 RngPerChrgAvg_L_Dsply 1;
BA_ "U_P708_MY2023_Rx" SG_ 1137 RngPerChrgAvg_L_Dsply 1;
BA_ "U_P702_MY2024_Rx" SG_ 1137 RngPerChrgAvg_L_Dsply 1;
BA_ "GenSigStartValue" SG_ 1137 RngImpctTot_Pc_Dsply 1022;
BA_ "U_V713N_MY2022_Rx" SG_ 1137 RngImpctTot_Pc_Dsply 1;
BA_ "U_V713AV_MY2022_Rx" SG_ 1137 RngImpctTot_Pc_Dsply 1;
BA_ "U_P708_MY2023_Rx" SG_ 1137 RngImpctTot_Pc_Dsply 1;
BA_ "U_V710_MY2023_Rx" SG_ 1137 RngImpctTot_Pc_Dsply 1;
BA_ "U_P702_MY2024_Rx" SG_ 1137 RngImpctTot_Pc_Dsply 1;
BA_ "GenSigStartValue" SG_ 1137 RngImpctExt_Pc_Dsply 1022;
BA_ "U_V713N_MY2022_Rx" SG_ 1137 RngImpctExt_Pc_Dsply 1;
BA_ "U_V713AV_MY2022_Rx" SG_ 1137 RngImpctExt_Pc_Dsply 1;
BA_ "U_P708_MY2023_Rx" SG_ 1137 RngImpctExt_Pc_Dsply 1;
BA_ "U_V710_MY2023_Rx" SG_ 1137 RngImpctExt_Pc_Dsply 1;
BA_ "U_P702_MY2024_Rx" SG_ 1137 RngImpctExt_Pc_Dsply 1;
BA_ "GenSigStartValue" SG_ 1137 RngImpctDrv_Pc_Dsply 1022;
BA_ "U_V713N_MY2022_Rx" SG_ 1137 RngImpctDrv_Pc_Dsply 1;
BA_ "U_V713AV_MY2022_Rx" SG_ 1137 RngImpctDrv_Pc_Dsply 1;
BA_ "U_P708_MY2023_Rx" SG_ 1137 RngImpctDrv_Pc_Dsply 1;
BA_ "U_V710_MY2023_Rx" SG_ 1137 RngImpctDrv_Pc_Dsply 1;
BA_ "U_P702_MY2024_Rx" SG_ 1137 RngImpctDrv_Pc_Dsply 1;
BA_ "GenSigStartValue" SG_ 1137 RngImpctClim_Pc_Dsply 1022;
BA_ "U_V713N_MY2022_Rx" SG_ 1137 RngImpctClim_Pc_Dsply 1;
BA_ "U_V713AV_MY2022_Rx" SG_ 1137 RngImpctClim_Pc_Dsply 1;
BA_ "U_P708_MY2023_Rx" SG_ 1137 RngImpctClim_Pc_Dsply 1;
BA_ "U_V710_MY2023_Rx" SG_ 1137 RngImpctClim_Pc_Dsply 1;
BA_ "U_P702_MY2024_Rx" SG_ 1137 RngImpctClim_Pc_Dsply 1;
BA_ "U_V710_MY2023_Rx" SG_ 844 SeatMasgDrv_D_Stat 1;
BA_ "U_P708_MY2023_Rx" SG_ 844 SeatMasgDrv_D_Stat 1;
BA_ "U_P702_MY2024_Rx" SG_ 844 SeatMasgDrv_D_Stat 1;
BA_ "U_V710_MY2023_Rx" SG_ 844 SeatIntnsDrv_D_Stat 1;
BA_ "U_P708_MY2023_Rx" SG_ 844 SeatIntnsDrv_D_Stat 1;
BA_ "U_P702_MY2024_Rx" SG_ 844 SeatIntnsDrv_D_Stat 1;
BA_ "U_V710_MY2023_Rx" SG_ 844 StmsLmbrDrv_D_Stat 1;
BA_ "U_P708_MY2023_Rx" SG_ 844 StmsLmbrDrv_D_Stat 1;
BA_ "U_P702_MY2024_Rx" SG_ 844 StmsLmbrDrv_D_Stat 1;
BA_ "U_V710_MY2023_Rx" SG_ 844 StmsCshnDrv_D_Stat 1;
BA_ "U_P708_MY2023_Rx" SG_ 844 StmsCshnDrv_D_Stat 1;
BA_ "U_P702_MY2024_Rx" SG_ 844 StmsCshnDrv_D_Stat 1;
BA_ "U_V710_MY2023_Rx" SG_ 844 SeatSwtchDrv_B_Stat 1;
BA_ "U_P708_MY2023_Rx" SG_ 844 SeatSwtchDrv_B_Stat 1;
BA_ "U_P702_MY2024_Rx" SG_ 844 SeatSwtchDrv_B_Stat 1;
BA_ "U_V710_MY2023_Rx" SG_ 844 SeatFnDrv_D_Stat 1;
BA_ "U_P708_MY2023_Rx" SG_ 844 SeatFnDrv_D_Stat 1;
BA_ "U_P702_MY2024_Rx" SG_ 844 SeatFnDrv_D_Stat 1;
BA_ "GenSigStartValue" SG_ 844 SeatAirAmb_P_Actl 10000;
BA_ "U_V710_MY2023_Rx" SG_ 844 SeatAirAmb_P_Actl 1;
BA_ "U_P708_MY2023_Rx" SG_ 844 SeatAirAmb_P_Actl 1;
BA_ "U_P702_MY2024_Rx" SG_ 844 SeatAirAmb_P_Actl 1;
BA_ "U_V710_MY2023_Rx" SG_ 844 SeatPDrv_B_Stat 1;
BA_ "U_P708_MY2023_Rx" SG_ 844 SeatPDrv_B_Stat 1;
BA_ "U_P702_MY2024_Rx" SG_ 844 SeatPDrv_B_Stat 1;
BA_ "GenSigStartValue" SG_ 843 SeatLmbrUpPsgr_Pc_Actl 127;
BA_ "U_V710_MY2023_Rx" SG_ 843 SeatLmbrUpPsgr_Pc_Actl 1;
BA_ "U_P708_MY2023_Rx" SG_ 843 SeatLmbrUpPsgr_Pc_Actl 1;
BA_ "U_P702_MY2024_Rx" SG_ 843 SeatLmbrUpPsgr_Pc_Actl 1;
BA_ "GenSigStartValue" SG_ 843 SeatLmbrMidPsgr_Pc_Actl 127;
BA_ "U_V710_MY2023_Rx" SG_ 843 SeatLmbrMidPsgr_Pc_Actl 1;
BA_ "U_P708_MY2023_Rx" SG_ 843 SeatLmbrMidPsgr_Pc_Actl 1;
BA_ "U_P702_MY2024_Rx" SG_ 843 SeatLmbrMidPsgr_Pc_Actl 1;
BA_ "GenSigStartValue" SG_ 843 SeatLmbrLoPsgr_Pc_Actl 127;
BA_ "U_V710_MY2023_Rx" SG_ 843 SeatLmbrLoPsgr_Pc_Actl 1;
BA_ "U_P708_MY2023_Rx" SG_ 843 SeatLmbrLoPsgr_Pc_Actl 1;
BA_ "U_P702_MY2024_Rx" SG_ 843 SeatLmbrLoPsgr_Pc_Actl 1;
BA_ "GenSigStartValue" SG_ 843 SeatBlUpPsgr_Pc_Actl 127;
BA_ "U_V710_MY2023_Rx" SG_ 843 SeatBlUpPsgr_Pc_Actl 1;
BA_ "U_P708_MY2023_Rx" SG_ 843 SeatBlUpPsgr_Pc_Actl 1;
BA_ "U_P702_MY2024_Rx" SG_ 843 SeatBlUpPsgr_Pc_Actl 1;
BA_ "GenSigStartValue" SG_ 843 SeatBlLoPsgr_Pc_Actl 127;
BA_ "U_V710_MY2023_Rx" SG_ 843 SeatBlLoPsgr_Pc_Actl 1;
BA_ "U_P708_MY2023_Rx" SG_ 843 SeatBlLoPsgr_Pc_Actl 1;
BA_ "U_P702_MY2024_Rx" SG_ 843 SeatBlLoPsgr_Pc_Actl 1;
BA_ "GenSigStartValue" SG_ 842 SeatLmbrUpDrv_Pc_Actl 127;
BA_ "U_V710_MY2023_Rx" SG_ 842 SeatLmbrUpDrv_Pc_Actl 1;
BA_ "U_P708_MY2023_Rx" SG_ 842 SeatLmbrUpDrv_Pc_Actl 1;
BA_ "U_P702_MY2024_Rx" SG_ 842 SeatLmbrUpDrv_Pc_Actl 1;
BA_ "GenSigStartValue" SG_ 842 SeatLmbrMidDrv_Pc_Actl 127;
BA_ "U_V710_MY2023_Rx" SG_ 842 SeatLmbrMidDrv_Pc_Actl 1;
BA_ "U_P708_MY2023_Rx" SG_ 842 SeatLmbrMidDrv_Pc_Actl 1;
BA_ "U_P702_MY2024_Rx" SG_ 842 SeatLmbrMidDrv_Pc_Actl 1;
BA_ "GenSigStartValue" SG_ 842 SeatLmbrLoDrv_Pc_Actl 127;
BA_ "U_V710_MY2023_Rx" SG_ 842 SeatLmbrLoDrv_Pc_Actl 1;
BA_ "U_P708_MY2023_Rx" SG_ 842 SeatLmbrLoDrv_Pc_Actl 1;
BA_ "U_P702_MY2024_Rx" SG_ 842 SeatLmbrLoDrv_Pc_Actl 1;
BA_ "GenSigStartValue" SG_ 842 SeatBlUpDrv_Pc_Actl 127;
BA_ "U_V710_MY2023_Rx" SG_ 842 SeatBlUpDrv_Pc_Actl 1;
BA_ "U_P708_MY2023_Rx" SG_ 842 SeatBlUpDrv_Pc_Actl 1;
BA_ "U_P702_MY2024_Rx" SG_ 842 SeatBlUpDrv_Pc_Actl 1;
BA_ "GenSigStartValue" SG_ 842 SeatBlLoDrv_Pc_Actl 127;
BA_ "U_V710_MY2023_Rx" SG_ 842 SeatBlLoDrv_Pc_Actl 1;
BA_ "U_P708_MY2023_Rx" SG_ 842 SeatBlLoDrv_Pc_Actl 1;
BA_ "U_P702_MY2024_Rx" SG_ 842 SeatBlLoDrv_Pc_Actl 1;
BA_ "GenSigSendType" SG_ 846 SeatPosHomeRear_D_Rq 3;
BA_ "U_P702_MY2024_Tx" SG_ 846 SeatPosHomeRear_D_Rq 1;
BA_ "GenSigSendType" SG_ 846 SeatRelxPosDactv_B_Rq 3;
BA_ "U_V710_MY2023_Tx" SG_ 846 SeatRelxPosDactv_B_Rq 1;
BA_ "U_P708_MY2023_Tx" SG_ 846 SeatRelxPosDactv_B_Rq 1;
BA_ "U_P702_MY2024_Tx" SG_ 846 SeatRelxPosDactv_B_Rq 1;
BA_ "GenSigSendType" SG_ 846 SeatRelxPosActv_B_Rq 3;
BA_ "U_V710_MY2023_Tx" SG_ 846 SeatRelxPosActv_B_Rq 1;
BA_ "U_P708_MY2023_Tx" SG_ 846 SeatRelxPosActv_B_Rq 1;
BA_ "U_P702_MY2024_Tx" SG_ 846 SeatRelxPosActv_B_Rq 1;
BA_ "GenSigSendType" SG_ 846 SeatRelxPosSet_D_Rq 3;
BA_ "U_V710_MY2023_Tx" SG_ 846 SeatRelxPosSet_D_Rq 1;
BA_ "U_P708_MY2023_Tx" SG_ 846 SeatRelxPosSet_D_Rq 1;
BA_ "U_P702_MY2024_Tx" SG_ 846 SeatRelxPosSet_D_Rq 1;
BA_ "GenSigSendType" SG_ 846 SeatMasgDrv_D_Rq 3;
BA_ "U_V710_MY2023_Tx" SG_ 846 SeatMasgDrv_D_Rq 1;
BA_ "U_P708_MY2023_Tx" SG_ 846 SeatMasgDrv_D_Rq 1;
BA_ "U_P702_MY2024_Tx" SG_ 846 SeatMasgDrv_D_Rq 1;
BA_ "GenSigSendType" SG_ 846 SeatMasgPsngr_D_Rq 3;
BA_ "U_V710_MY2023_Tx" SG_ 846 SeatMasgPsngr_D_Rq 1;
BA_ "U_P708_MY2023_Tx" SG_ 846 SeatMasgPsngr_D_Rq 1;
BA_ "U_P702_MY2024_Tx" SG_ 846 SeatMasgPsngr_D_Rq 1;
BA_ "GenSigSendType" SG_ 846 SeatLmbr_D_Rq 3;
BA_ "U_V710_MY2023_Tx" SG_ 846 SeatLmbr_D_Rq 1;
BA_ "U_P708_MY2023_Tx" SG_ 846 SeatLmbr_D_Rq 1;
BA_ "U_P702_MY2024_Tx" SG_ 846 SeatLmbr_D_Rq 1;
BA_ "GenSigSendType" SG_ 846 SeatFnChngPsgr2_D_Rq 3;
BA_ "U_V710_MY2023_Tx" SG_ 846 SeatFnChngPsgr2_D_Rq 1;
BA_ "U_P708_MY2023_Tx" SG_ 846 SeatFnChngPsgr2_D_Rq 1;
BA_ "U_P702_MY2024_Tx" SG_ 846 SeatFnChngPsgr2_D_Rq 1;
BA_ "GenSigSendType" SG_ 846 SeatFnChngDrv2_D_Rq 3;
BA_ "U_V710_MY2023_Tx" SG_ 846 SeatFnChngDrv2_D_Rq 1;
BA_ "U_P708_MY2023_Tx" SG_ 846 SeatFnChngDrv2_D_Rq 1;
BA_ "U_P702_MY2024_Tx" SG_ 846 SeatFnChngDrv2_D_Rq 1;
BA_ "GenSigSendType" SG_ 846 SeatFnPsgr_D_Rq 3;
BA_ "U_V710_MY2023_Tx" SG_ 846 SeatFnPsgr_D_Rq 1;
BA_ "U_P708_MY2023_Tx" SG_ 846 SeatFnPsgr_D_Rq 1;
BA_ "U_P702_MY2024_Tx" SG_ 846 SeatFnPsgr_D_Rq 1;
BA_ "GenSigSendType" SG_ 846 SeatFnDrv_D_Rq 3;
BA_ "U_V710_MY2023_Tx" SG_ 846 SeatFnDrv_D_Rq 1;
BA_ "U_P708_MY2023_Tx" SG_ 846 SeatFnDrv_D_Rq 1;
BA_ "U_P702_MY2024_Tx" SG_ 846 SeatFnDrv_D_Rq 1;
BA_ "GenSigSendType" SG_ 846 SeatFnDfaltPsgr_B_Rq 3;
BA_ "U_V710_MY2023_Tx" SG_ 846 SeatFnDfaltPsgr_B_Rq 1;
BA_ "U_P708_MY2023_Tx" SG_ 846 SeatFnDfaltPsgr_B_Rq 1;
BA_ "U_P702_MY2024_Tx" SG_ 846 SeatFnDfaltPsgr_B_Rq 1;
BA_ "GenSigSendType" SG_ 846 SeatFnDfaltDrv_B_Rq 3;
BA_ "U_V710_MY2023_Tx" SG_ 846 SeatFnDfaltDrv_B_Rq 1;
BA_ "U_P708_MY2023_Tx" SG_ 846 SeatFnDfaltDrv_B_Rq 1;
BA_ "U_P702_MY2024_Tx" SG_ 846 SeatFnDfaltDrv_B_Rq 1;
BA_ "GenSigSendType" SG_ 846 SeatFnChngPsgr_D_Rq 3;
BA_ "U_V710_MY2023_Tx" SG_ 846 SeatFnChngPsgr_D_Rq 1;
BA_ "U_P708_MY2023_Tx" SG_ 846 SeatFnChngPsgr_D_Rq 1;
BA_ "U_P702_MY2024_Tx" SG_ 846 SeatFnChngPsgr_D_Rq 1;
BA_ "GenSigSendType" SG_ 846 SeatFnChngDrv_D_Rq 3;
BA_ "U_V710_MY2023_Tx" SG_ 846 SeatFnChngDrv_D_Rq 1;
BA_ "U_P708_MY2023_Tx" SG_ 846 SeatFnChngDrv_D_Rq 1;
BA_ "U_P702_MY2024_Tx" SG_ 846 SeatFnChngDrv_D_Rq 1;
BA_ "GenSigSendType" SG_ 846 PsgrMemory_Rq 3;
BA_ "U_V710_MY2023_Tx" SG_ 846 PsgrMemory_Rq 1;
BA_ "U_P708_MY2023_Tx" SG_ 846 PsgrMemory_Rq 1;
BA_ "U_P702_MY2024_Tx" SG_ 846 PsgrMemory_Rq 1;
VAL_ 811 ExtLghtDsply_D_Stat 7 "NotUsed" 6 "PressToOn3" 5 "PressToOff3" 4 "PressToOn2" 3 "PressToOff2" 2 "PressToOn1" 1 "PressToOff1" 0 "Reset" ;
VAL_ 811 LongTermReset_B_RqMnu 1 "On" 0 "Off" ;
VAL_ 811 SpeedoMajorUnit_D_Confg 3 "NotUsed" 2 "Kph" 1 "Mph" 0 "Null" ;
VAL_ 811 ScMnSoc_Pc_RqMnu 127 "Faulty" 126 "NoDataExists" ;
VAL_ 811 ScEnbl_D_RqMnu 3 "NotUsed" 2 "On" 1 "Off" 0 "Null" ;
VAL_ 811 OnePdlDrvButtn_B_Stat 1 "Pressed" 0 "Not_Pressed" ;
VAL_ 811 OnePdlDrvButtn_B_Falt 1 "Faulted" 0 "NotFaulted" ;
VAL_ 811 GoTEditMnte_T_RqMnu 15 "Faulty" 14 "NoDataExists" 13 "NotUsed_2" 12 "NotUsed_1" 11 "Minute_55" 10 "Minute_50" 9 "Minute_45" 8 "Minute_40" 7 "Minute_35" 6 "Minute_30" 5 "Minute_25" 4 "Minute_20" 3 "Minute_15" 2 "Minute_10" 1 "Minute_5" 0 "Minute_0" ;
VAL_ 811 GoTEditHr_T_RqMnu 31 "Faulty" 30 "NoDataExists" ;
VAL_ 811 ExtLghtRight_D_RqMnu 7 "NotUsed" 6 "PressToOn3" 5 "PressToOff3" 4 "PressToOn2" 3 "PressToOff2" 2 "PressToOn1" 1 "PressToOff1" 0 "Reset" ;
VAL_ 811 AutoLghtOvrrd_B_RqDrv 1 "Allowed" 0 "NotAllowed" ;
VAL_ 811 ExtLghtRear_D_RqMnu 7 "NotUsed" 6 "PressToOn3" 5 "PressToOff3" 4 "PressToOn2" 3 "PressToOff2" 2 "PressToOn1" 1 "PressToOff1" 0 "Reset" ;
VAL_ 811 ExtLghtLeft_D_RqMnu 7 "NotUsed" 6 "PressToOn3" 5 "PressToOff3" 4 "PressToOn2" 3 "PressToOff2" 2 "PressToOn1" 1 "PressToOff1" 0 "Reset" ;
VAL_ 811 ExtLghtFront_D_RqMnu 7 "NotUsed" 6 "PressToOn3" 5 "PressToOff3" 4 "PressToOn2" 3 "PressToOff2" 2 "PressToOn1" 1 "PressToOff1" 0 "Reset" ;
VAL_ 811 DistToStopover_L_Actl 65535 "Faulty" ;
VAL_ 811 StopoverType_D_Stat 7 "Faulty" 6 "NotUsed_1" 5 "Other" 4 "Work" 3 "Home" 2 "ChargeStation" 1 "FinalDestination" 0 "Null" ;
VAL_ 563 VgfZone_D_Stat 7 "Faulty" 6 "NotUsed_2" 5 "NotUsed_1" 4 "GPS_Unavailable" 3 "Restricted_Zone" 2 "Warning_Zone" 1 "Allowed_Zone" 0 "Off_Normal" ;
VAL_ 563 BattChrgStrtStop_D2_Rq 15 "NotUsed_8" 14 "NotUsed_7" 13 "NotUsed_6" 12 "NotUsed_5" 11 "NotUsed_4" 10 "NotUsed_3" 9 "NotUsed_2" 8 "NotUsed_1" 7 "GridStopChargingPartial" 6 "GridStopChargingMandatory" 5 "GridStartChargingFree" 4 "GridStartChargingPreferred" 3 "ReturnToSettings" 2 "StopCharge" 1 "StartCharge" 0 "NoNewRequest" ;
VAL_ 563 NtfyDrvTrgtDist_L2_Rq 8191 "Faulty" 8190 "NoDataExists" ;
VAL_ 563 GridSrvc01_D_RqCld 3 "Faulty" 2 "No_Data_Exists" 1 "On" 0 "Off" ;
VAL_ 563 DrvBhavWarn_B_Rq 1 "On" 0 "Off" ;
VAL_ 563 BattChrgStrtStop_D_Rq 3 "ReturnToSettings" 2 "StopCharge" 1 "StartCharge" 0 "NoNewRequest" ;
VAL_ 563 DrvBhavAudioAlrt_D_Rq 58 "NotUsed_51" 57 "NotUsed_50" 56 "NotUsed_49" 55 "NotUsed_48" 54 "NotUsed_47" 53 "NotUsed_46" 52 "NotUsed_45" 25 "NotUsed_18" 24 "NotUsed_17" 23 "NotUsed_16" 22 "NotUsed_15" 21 "NotUsed_14" 20 "NotUsed_13" 19 "NotUsed_12" 18 "NotUsed_11" 17 "NotUsed_10" 16 "NotUsed_9" 15 "NotUsed_8" 14 "NotUsed_7" 13 "NotUsed_6" 12 "NotUsed_5" 11 "NotUsed_4" 10 "NotUsed_3" 9 "NotUsed_2" 8 "NotUsed_1" 7 "ExcessiveIdleAndUnbuckled" 6 "ExcessiveSpeedAndUnbuckled" 5 "SeatbeltUnbuckled" 4 "HardBrakingBegin" 3 "HardAccelerationBegin" 2 "ExcessiveSpeedBegin" 1 "ExcessiveIdleBegin" 0 "NoMessage" 63 "NotUsed_56" 62 "NotUsed_55" 61 "NotUsed_54" 60 "NotUsed_53" 59 "NotUsed_52" ;
VAL_ 563 OfbChrgSetSync_D_Rq 3 "Fail" 2 "Success" 1 "InProgress" 0 "NoSyncInProgress" ;
VAL_ 563 KeyOffPwMde_D_Stat 7 "NotUsed_6" 6 "NotUsed_5" 5 "NotUsed_4" 4 "NotUsed_3" 0 "Inactive" 1 "On" 2 "NotUsed_1" 3 "NotUsed_2" ;
VAL_ 563 ModemReset_D_Stat 15 "NotUsed_10" 14 "NotUsed_9" 13 "NotUsed_8" 12 "NotUsed_7" 11 "NotUsed_6" 10 "NotUsed_5" 9 "NotUsed_4" 8 "NotUsed_3" 7 "NotUsed_2" 6 "NotUsed_1" 5 "WifiHotSpotResetComplete" 4 "CcsResetComplete" 3 "OnlineTrafficResetComplete" 2 "PaakResetComplete" 1 "ResetNotComplete" 0 "Null" ;
VAL_ 563 FactoryReset_St 3 "NotUsed_2" 2 "NotUsed_1" 1 "FactoryDefaultsRestored" 0 "Null" ;
VAL_ 978 CnvtTopTWarn_B_Falt 1 "Yes" 0 "No" ;
VAL_ 978 CnvtTopTOvr_B_Falt 1 "Yes" 0 "No" ;
VAL_ 978 CnvtTopTDir_B_Falt 1 "Yes" 0 "No" ;
VAL_ 978 CnvtTopStall_B_Falt 1 "Yes" 0 "No" ;
VAL_ 978 CnvtTopSns_B_Falt 1 "Yes" 0 "No" ;
VAL_ 978 CnvtTopRvrse_B_Stat 1 "Yes" 0 "No" ;
VAL_ 978 CnvtTopRngOpen_B_Stat 1 "Active" 0 "Inactive" ;
VAL_ 978 CnvtTopRngClose_B_Stat 1 "Active" 0 "Inactive" ;
VAL_ 978 CnvtTopRestrc_B_Falt 1 "Yes" 0 "No" ;
VAL_ 978 CnvtTopRdy_B_Stat 1 "Yes" 0 "No" ;
VAL_ 978 CnvtTopPosSet_B_Stat 1 "Yes" 0 "No" ;
VAL_ 978 CnvtTopPos_D_Stat 15 "Faulty" 14 "NotUsed7" 13 "NotUsed6" 12 "NotUsed5" 11 "NotUsed4" 10 "NotUsed3" 9 "NotUsed2" 8 "NotUsed1" 7 "ShutdownComplete" 6 "NoNormalised" 5 "Moving" 4 "PositionIntermediate" 3 "PositionOpenTarget" 2 "PositionOpenPosition" 1 "PositionClosePosition" 0 "PositionCloseTarget" ;
VAL_ 978 CnvtTopPos_B_Falt 1 "Yes" 0 "No" ;
VAL_ 978 CnvtTopOut_B_Falt 1 "Yes" 0 "No" ;
VAL_ 978 CnvtTopOpen_D_Stat 3 "Faulty" 2 "NotUsed" 1 "Active" 0 "Inactive" ;
VAL_ 978 CnvtTopOpen_B_Stat 1 "Yes" 0 "No" ;
VAL_ 978 CnvtTopNom_B_Stat 1 "Yes" 0 "No" ;
VAL_ 978 CnvtTopDir_B_Falt 1 "Yes" 0 "No" ;
VAL_ 978 CnvtTopComplt_D_Stat 7 "DenormalizingReady" 6 "NormalizingReady" 5 "RunoutComplete" 4 "StopByPositioning" 3 "StopByFault" 2 "StopByPinch" 1 "StopByStall" 0 "StopByRequest" ;
VAL_ 978 CnvtTopCnfm_B_Stat 1 "Yes" 0 "No" ;
VAL_ 978 CnvtTopClose_D_Stat 3 "Faulty" 2 "NotUsed" 1 "Active" 0 "Inactive" ;
VAL_ 978 CnvtTopActv_B_Stat 1 "Yes" 0 "No" ;
VAL_ 978 TonneuCapMde_D_Stat 3 "Faulty" 2 "NotUsed" 1 "Installed" 0 "NotInstalled" ;
VAL_ 1146 TrlrAidSwtch_D_RqDrv 3 "Faulty" 2 "NotUsed" 1 "Pressed" 0 "Not_Pressed" ;
VAL_ 1146 TrlrAidCtl_U_RqDrv 4095 "Faulty" 4094 "NoDataExists" ;
VAL_ 1109 eCallConfirmation 7 "Unused_2" 6 "CallComplete_DTMF_Timeout" 5 "eCall_Configured_Off" 4 "Call_Unsuccessful" 3 "Call_Cancelled" 2 "Call_Completed" 1 "Call_In_Progress" 0 "Normal" ;
VAL_ 557 AudioToneTouchY_D_Stat 255 "Value254" 2 "Value1_up_to_0xFE_Value253" 1 "Value0" 0 "Null" ;
VAL_ 557 AudioToneTouchX_D_Stat 255 "Value254" 2 "Value1_up_to_0xFE_Value253" 1 "Value0" 0 "Null" ;
VAL_ 557 AudioToneTouch_D_Stat 3 "NotUsed" 2 "Enabled" 1 "Disabled" 0 "Null" ;
VAL_ 140 DcacPwResetBttn_D_Stat 3 "NotUsed" 2 "Stuck" 1 "Pressed" 0 "Not_Pressed" ;
VAL_ 140 CcAslButtnIndxIncPress2 1 "Button_Pressed" 0 "Button_Not_Pressed" ;
VAL_ 140 SteWhlSwtchMde_D_Stat 3 "NotUsed_2" 2 "NotUsed_1" 1 "Dialog" 0 "Domain" ;
VAL_ 140 CcAslButtnOffCnclPress2 1 "Button_Pressed" 0 "Button_Not_Pressed" ;
VAL_ 140 CcAslButtnIndxDecPress2 1 "Button_Pressed" 0 "Button_Not_Pressed" ;
VAL_ 140 CcAslButtnCnclResPress2 1 "Button_Pressed" 0 "Button_Not_Pressed" ;
VAL_ 140 CcAslButtnResIncPress3 1 "Pressed" 0 "Not pressed" ;
VAL_ 140 CcButtnOnPress3 1 "Pressed" 0 "Not pressed" ;
VAL_ 140 CcButtnOnOffPress3 1 "Pressed" 0 "Not pressed" ;
VAL_ 140 CcButtnOnOffCnclPress3 1 "Pressed" 0 "Not pressed" ;
VAL_ 140 CcButtnOffPress3 1 "Pressed" 0 "Not pressed" ;
VAL_ 140 CcAsllButtnResPress3 1 "Pressed" 0 "Not pressed" ;
VAL_ 140 CcAslButtnSetPress3 1 "Pressed" 0 "Not pressed" ;
VAL_ 140 CcAslButtnSetIncPress3 1 "Pressed" 0 "Not pressed" ;
VAL_ 140 CcAslButtnSetDecPress3 1 "Pressed" 0 "Not pressed" ;
VAL_ 140 CcAslButtnResDecPress3 1 "Pressed" 0 "Not pressed" ;
VAL_ 140 CcAslButtnOnPress3 1 "Pressed" 0 "Not pressed" ;
VAL_ 140 CcAslButtnOnOffCncl3 1 "Pressed" 0 "Not pressed" ;
VAL_ 140 CcAslButtnDeny_B_Actl3 1 "Pressed" 0 "Not pressed" ;
VAL_ 140 CcAslButtnCnclPress3 1 "Pressed" 0 "Not pressed" ;
VAL_ 140 AslButtnOnOffPress3 1 "Pressed" 0 "Not pressed" ;
VAL_ 140 AslButtnOnOffCnclPress2 1 "Pressed" 0 "Not pressed" ;
VAL_ 546 PrplSnd_D_Rq 3 "NotUsed" 2 "Enabled" 1 "Disabled" 0 "Null" ;
VAL_ 546 SYNC_New_Attn_Event 1 "Active" 0 "Inactive" ;
VAL_ 546 SYNC_Attn_Info_Audio 7 "Unknown" 6 "Attenuation_6" 5 "Attenuation_5" 4 "Attenuation_4" 3 "Attenuation_3" 2 "Attenuation_2" 1 "Attenuation_1" 0 "Inactive" ;
VAL_ 546 Prompt_Directionality 3 "RearSpeakers" 2 "FrontSpeakers" 1 "ALL" 0 "Inactive" ;
VAL_ 546 Audible_Beep 1 "Active" 0 "Inactive" ;
VAL_ 546 Alert_Chan 2 "Initialize_for_Prompts" 1 "Mute" 0 "Inactive" ;
VAL_ 1186 AwdStat2_D_RqDsply 31 "NotUsed_26" 30 "NotUsed_25" 29 "NotUsed_24" 28 "NotUsed_23" 27 "NotUsed_22" 26 "NotUsed_21" 25 "NotUsed_20" 24 "NotUsed_19" 23 "NotUsed_18" 22 "NotUsed_17" 21 "NotUsed_16" 20 "NotUsed_15" 19 "NotUsed_14" 18 "NotUsed_13" 17 "NotUsed_12" 16 "NotUsed_11" 15 "NotUsed_10" 14 "NotUsed_9" 13 "NotUsed_8" 12 "NotUsed_7" 11 "NotUsed_6" 10 "NotUsed_5" 9 "NotUsed_4" 8 "NotUsed_3" 7 "NotUsed_2" 6 "NotUsed_1" 5 "Unavailable4x4Mode

" 4 "UnavailableDriveMode" 3 "HillHoldFail" 2 "TCaseOilChanged" 1 "ChangeTCaseOil" 0 "Normal" ;
VAL_ 1186 AwdDrvMde_D2_Stat 15 "Faulty" 14 "NotUsed_7" 13 "NotUsed_6" 12 "NotUsed_5" 11 "NotUsed_4" 10 "NotUsed_3" 9 "NotUsed_2" 8 "NotUsed_1" 7 "NotAvailable" 6 "TowHaul" 5 "RockCrawl" 4 "Baja" 3 "MudAndSand" 2 "Weather" 1 "Sport" 0 "Normal" ;
VAL_ 1186 FrontDiffLckLamp_D_Rq 3 "Triggered" 2 "Flash" 1 "On" 0 "Off" ;
VAL_ 1186 FrontDiffLckMsg_D_Rq 7 "LockerDisabled" 6 "LockerEnabled" 5 "LockerAccelPedal" 4 "Speed4" 3 "Speed3" 2 "Speed2" 1 "Speed1" 0 "NormalNoMessage" ;
VAL_ 1186 RearDiffLckLamp_D_Rq 3 "Not_Used" 2 "Flash" 1 "On" 0 "Off" ;
VAL_ 1186 RearDiffFalt_D_Stat 3 "Diff_Failed_Closed" 2 "Diff_Failed_Open" 1 "Fault_Non_Specific" 0 "No_Fault" ;
VAL_ 1186 RearDiffLck_Tq_Actl 4095 "Fault" 4094 "Unknown" ;
VAL_ 1186 FrontDiffFalt_D_Stat 3 "Diff_Failed_Closed" 2 "Diff_Failed_Open" 1 "Fault_Non_Specific" 0 "No_Fault" ;
VAL_ 1186 FrontDiffLck_Tq_Actl 16383 "Faulty" 16382 "NoDataExists" ;
VAL_ 1186 SelDrvMdeAwd2_D_Stat 31 "Faulty" 30 "NotUsed_17" 29 "NotUsed_16" 28 "NotUsed_15" 27 "NotUsed_14" 26 "NotUsed_13" 25 "NotUsed_12" 24 "NotUsed_11" 23 "NotUsed_10" 22 "NotUsed_9" 21 "NotUsed_8" 20 "CustomMode" 19 "OnePedalDrive" 18 "DragMode" 17 "EvLaterChargeMode" 16 "EvNowMode" 15 "TrackMode" 14 "RoughRoadMode" 13 "NotAvailable" 12 "HighSpeedDesertMode_Baja" 11 "SportAdaptiveMode" 10 "RockCrawlMode" 9 "MudRutsMode" 8 "SandMode" 7 "EconomyMode" 6 "GrassGravelSnow" 5 "TowHaulMode" 4 "SportMode" 3 "Normal_4L" 2 "Normal_4A" 1 "Normal_2H" 0 "NormalMode" ;
VAL_ 1186 RearDiffLckMsg_D_Rq 7 "Locker_Disabled" 6 "Locker_Enabled" 5 "Locker_Accel_Pedal" 4 "Speed4" 3 "Speed3" 2 "Spee2" 1 "Speed1" 0 "Normal__No_Message " ;
VAL_ 1186 LsdSrvcRqd_B_Rq 1 "On" 0 "Off" ;
VAL_ 1138 BattChrgTrgtLMin_T_Est 2047 "Faulty" 2046 "NoDataExists" ;
VAL_ 1138 ActChrgEndYr_No_Actl 31 "Invalid" ;
VAL_ 1138 ActChrgEndMnth_No_Actl 15 "Invalid" ;
VAL_ 1138 ActChrgEndMin_No_Actl 63 "Invalid" 62 "Unknown" ;
VAL_ 1138 ActChrgEndHr_No_Actl 31 "Invalid" 30 "Unknown" ;
VAL_ 1138 ActChrgEndDay_No_Actl 31 "Invalid" ;
VAL_ 1139 BattChrgTrgtLMax_T_Est 2047 "Faulty" 2046 "NoDataExists" ;
VAL_ 1139 ActChrgStrtYr_No_Actl 31 "Invalid" ;
VAL_ 1139 ActChrgStrtMin_No_Actl 63 "Invalid" 62 "Unknown" ;
VAL_ 1139 ActChrgStrtHr_No_Actl 31 "Invalid" 30 "Unknown" ;
VAL_ 1139 ActChrgStrtDay_No_Actl 31 "Invalid" ;
VAL_ 1139 ActChrgStrMnth_No_Actl 15 "Invalid" ;
VAL_ 1145 EstmChrgTimeHP_St 255 "Invalid" ;
VAL_ 1145 EstmChrgTimeLP_St 255 "Invalid" ;
VAL_ 1145 ChargeNowDuration_St 255 "Invalid" ;
VAL_ 1145 VehElRngeNut_L2_Dsply 8191 "Faulty" 8190 "NoDataExists" ;
VAL_ 1145 VehElRngeNut_L_Dsply 4095 "Faulty" 4094 "NoDataExists" ;
VAL_ 1145 NxtUsgSocEst_Pc_Dsply 255 "Faulty" 254 "NoDataExists" ;
VAL_ 1232 AHU_EnsembleName_St 1 "Supported" 0 "Not_Supported" ;
VAL_ 1232 AHU_AutoConfigOcc_Shakr 1 "Supported" 0 "Not_Supported" ;
VAL_ 1232 AHU_AutoConfigOcc_Rear 1 "Supported" 0 "Not_Supported" ;
VAL_ 1232 AHU_AutoConfigOcc_Front 1 "Supported" 0 "Not_Supported" ;
VAL_ 1232 AHU_AutoConfigOcc_Drvr 1 "Supported" 0 "Not_Supported" ;
VAL_ 1232 AHU_AutoConfigOcc_Cnvrt 1 "Supported" 0 "Not_Supported" ;
VAL_ 1232 AHU_AutoConfigOcc_Allst 1 "Supported" 0 "Not_Supported" ;
VAL_ 1232 ACU_DigitalRadio_St 5 "DAB_RadioSystemWithPTY_JA" 4 "DAB_RadioSystemWithPTY_GC" 3 "DAB_RadioSystemWithPTY_NA" 2 "DAB_RadioSystemWithPTY_EU" 1 "WithoutDigitalRadioSystem" 0 "Invalid" ;
VAL_ 1232 ACU_Configuration 6 "HIN_HSRNS" 0 "Invalid" 1 "LowLevelAudio" 2 "HighLevelAudio" 3 "LowLevelNavigation" 4 "HighLevelNavigation" 5 "HIN_LSRNS" ;
VAL_ 1232 ACU_MediaPlayer_St 0 "Invalid" 1 "MusicCassettePlayer" 2 "CdSinglePlayer" 3 "CdChanger" ;
VAL_ 1141 AirAmbTePlgIn_D_Dsply 3 "NotUsed" 2 "Hot_Outside_Plg_In_Msg" 1 "Cold_Outside_Plg_In_Msg" 0 "No_Plg_In_Msg" ;
VAL_ 1141 PtRmtRprt_D_Rq 15 "NotUsed_4" 14 "NotUsed_3" 13 "NotUsed_2" 12 "PlugInToMaintain12vBattery" 11 "SettingUpdated" 10 "FastChargeComplete" 9 "ChargeNotOccurring" 8 "OneTimeSocReached" 7 "BatteryTemperatureReminder" 6 "ReducedPerformance" 5 "LimitedPerformance" 4 "ChargeFault" 3 "ChargeComplete" 2 "VehiclePreconditioned" 1 "TripDistanceAchieved" 0 "NoReportRequest" ;
VAL_ 1141 NxtUsg_D_Rq 0 "Invalid" 1 "Not_Requested" 2 "Requested" 3 "NotUsed" ;
VAL_ 1141 NtfctnConflict1_D_Rq 7 "NotUsed_4" 6 "NotUsed_3" 5 "NotUsed_2" 4 "NotUsed_1" 3 "ChargeWindow" 2 "DepartureTime" 1 "NoConflictExists" 0 "Null" ;
VAL_ 1141 ChrgLocGPS_D_Rq 0 "Inactive" 1 "Not_Requested" 2 "Requested" 3 "NotUsed" ;
VAL_ 1141 OfbChrgSetSync_D_Stat 3 "Fail" 2 "Success" 1 "InProgress" 0 "NoSyncInProgress" ;
VAL_ 1140 BattTracPw_Pc_Avail 255 "Faulty" 254 "NoDataExists" ;
VAL_ 1140 RgenLongTerm_L_Dsply 16777215 "Faulty" 16777214 "NoDataExists" ;
VAL_ 1140 PreCondStat_D_Dsply 7 "Reserved3" 6 "Reserved2" 5 "Reserved1" 4 "Faulted" 3 "Complete" 2 "In_Progress" 1 "Scheduled" 0 "Not_Scheduled" ;
VAL_ 1140 RgenEvntLvl_Pc_Dsply 1023 "Fault" 1022 "NoDataExists" ;
VAL_ 1140 BrkEvntComplt_B_Dsply 1 "On" 0 "Off" ;
VAL_ 1140 ExtChrgrFalt_B_Dsply 1 "Yes" 0 "No" ;
VAL_ 873 BattTracEMaint_B_Dsply 1 "On" 0 "Off" ;
VAL_ 873 EffRelTrgtOn_B_Dsply 1 "On" 0 "Off" ;
VAL_ 873 GpsElMdeActv_B_Dsply 1 "On" 0 "Off" ;
VAL_ 873 LoAirAmbPlgIn_B_Dsply 1 "On" 0 "Off" ;
VAL_ 871 BattChrgCmpltPt_T_Est 2047 "Faulty" 2046 "NoDataExists" ;
VAL_ 871 BattChrgTrgSocPt_T_Est 2047 "Faulty" 2046 "NoDataExists" ;
VAL_ 871 BattChrgTrgtLPt_T_Est 2047 "Faulty" 2046 "NoDataExists" ;
VAL_ 871 BattElecPerf_D_Actl 7 "NotUsed" 6 "Hot_Batt_Severe_Lim_Perf" 5 "Hot_Batt_Reduced_Perf" 4 "Hot_Batt_Close_to_lim_Per" 3 "Cold_Batt_Severe_Lim_Perf" 2 "Cold_Batt_Reduced_Perf" 1 "Cold_Batt_Close_to_lim_Pe" 0 "Ok_no_message_displayed" ;
VAL_ 871 DrvEffLvlIncDec_D_Cmd 3 "NotUsed" 2 "Decrease_Level_by_1" 1 "Increase_Level_by_1" 0 "Null_State" ;
VAL_ 870 EngMdeMsgTxt_D_Rq 7 "NotUsed_3" 6 "NotUsed_2" 5 "NotUsed_1" 4 "Charge" 3 "GlowingCharge" 2 "Hybrid" 1 "Ev" 0 "NoMessage" ;
VAL_ 870 HybMdeMsgTxt_D2_Rq 15 "NotUsed_4" 14 "NotUsed_3" 13 "NotUsed_2" 12 "NotUsed_1" 11 "EvOverride_Avail" 10 "EvLaterActv_EvAuto_NowAvai" 9 "EvNowActv_EvAuto_LaterAvai" 8 "EvAutoActv_EvNow_LaterAvai" 7 "EvAutoActv_NoOtherMdeAvail" 6 "EvChrgActv_EvAutoMdeAvail" 5 "EvAutoActv_EvChrgMdeAvail" 4 "EvChrgActv_AllPhevMdeAvail" 3 "EvLaterActv_AllPhevMdeAvai" 2 "EvNowActv_AllPhevMdeAvail" 1 "EvAutoActv_AllPhevMdeAvail" 0 "Null" ;
VAL_ 870 PolicePurstMde_B_Stat 1 "On" 0 "Off" ;
VAL_ 870 RngPerChrgInst_L_Dsply 4095 "Faulty" 4094 "NoDataExists" ;
VAL_ 870 HybMdeLimMsgTxt_D_Rq 3 "Limited_Req_Full_Defrost" 2 "Limited_Climate_Defrost" 1 "Limited_System_Performance" 0 "Null" ;
VAL_ 870 ChkPlgtoStrt_D_Dsply 3 "NotUsed" 2 "Is_VehicleUnplugged_Prompt" 1 "Check_Plug_to_Start" 0 "No_Message_Display" ;
VAL_ 870 ShifOutNtrlMsgTxt_D_Rq 7 "Message7" 6 "Message6" 5 "Message5" 4 "Message4" 3 "Message3" 2 "Message2" 1 "Message1" 0 "NoMessage" ;
VAL_ 869 PwrFlowTxt_D_Dsply 15 "NotUsed7" 14 "NotUsed6" 13 "NotUsed5" 12 "NotUsed4" 11 "Disply_Rgen_Chrg_Txt" 10 "Disp_Fast_Charge_Txt" 9 "Disp_Fast_Charge_Cmplt_Txt" 8 "Disp_Charge_Cmplt_Txt" 7 "Disp_Remote_Start_Txt" 6 "Disp_Eng_Drv_Txt" 5 "Disp_Elec_Drv_Txt" 4 "Disp_Idle_with_Chrg_Txt" 3 "Disp_Idle_Txt" 2 "Disp_Charg_HV_Batt_Txt" 1 "Disp_Hyb_Drive_Txt" 0 "No_Text" ;
VAL_ 869 EngOnMsg2_D_Dsply 14 "_0xE_to_1F_NotUsed" 12 "Battery_Temperature" 11 "Hill_Decent_Control" 10 "Fuel_Maintenance" 9 "Oil_Maintenance" 8 "Normal_Operation" 7 "Low_Gear" 6 "Batt_Charging" 5 "Engine_Cold" 4 "Neutral_Gear" 3 "Heater_Setting" 2 "High_Speed" 1 "Acceleration" 0 "No_Display" 13 "Drive_Mode_Selection" ;
VAL_ 869 EngOnMsg1_D_Dsply 14 "_0xE_to_1F_NotUsed" 12 "Battery_Temperature" 11 "Hill_Decent_Control" 10 "Fuel_Maintenance" 9 "Oil_Maintenance" 8 "Normal_Operation" 7 "Low_Gear" 6 "Batt_Charging" 5 "Engine_Cold" 4 "Neutral_Gear" 3 "Heater_Setting" 2 "High_Speed" 1 "Acceleration" 0 "No_Display" 13 "Drive_Mode_Selection" ;
VAL_ 869 FuelMaintMde_D_Dsply 3 "Feature_Not_Present" 2 "In_Fuel_Maint_Mode" 1 "Close_to_Fuel_Maint" 0 "OK" ;
VAL_ 869 RgenActv_B_Dsply 1 "On" 0 "Off" ;
VAL_ 869 EngOffTe_B_Dsply 1 "Eng_warm_engh_for_pd" 0 "Eng_not_warm_engh_for_pd" ;
VAL_ 869 EngActv_B_Dsply 1 "On" 0 "Off" ;
VAL_ 869 EffWhlThresOn_B_Dsply 1 "On" 0 "Off" ;
VAL_ 869 DchrgActv_B_Dsply 1 "On" 0 "Off" ;
VAL_ 869 ChrgActv_B_Dsply 1 "On" 0 "Off" ;
VAL_ 786 VehElRnge_L2_Dsply 8191 "Faulty" 8190 "NoDataExists" ;
VAL_ 786 RgenTrip_L_Dsply 65535 "Fault" 65534 "NoDataExists" ;
VAL_ 786 VehElRngeCyc_L_Dsply 4095 "Faulty" 4094 "NoDataExists" ;
VAL_ 786 PtDataKeyId_D_Stat 15 "NotUsed5" 14 "NotUsed4" 13 "NotUsed3" 12 "NotUsed2" 11 "NotUsed1" 10 "Tot_Veh_NUT" 9 "Cust_4_NUT" 8 "Cust_3_NUT" 7 "Cust_2_NUT" 6 "Cust_1_NUT" 5 "Tot_Veh_Stat" 4 "Cust_4_Stat" 3 "Cust_3_Stat" 2 "Cust_2_Stat" 1 "Cust_1_Stat" 0 "Null" ;
VAL_ 786 ChrgStat_D_Dsply 7 "NotUsed" 6 "Complete" 5 "Scheduled" 4 "In_Progress" 3 "Fault_Outside_Car" 2 "Fault_Inside_Car" 1 "Fault_Unknown_Location" 0 "Not_Ready" ;
VAL_ 1095 Pers4Phone_D_Stat 7 "SevenPhoneAssociated" 6 "SixPhoneAssociated" 5 "FivePhoneAssociated" 4 "FourPhoneAssociated" 3 "ThreePhoneAssociated" 2 "TwoPhoneAssociated" 1 "OnePhoneAssociated" 0 "NoPhoneAssociated" ;
VAL_ 1095 Pers3Phone_D_Stat 7 "SevenPhoneAssociated" 6 "SixPhoneAssociated" 5 "FivePhoneAssociated" 4 "FourPhoneAssociated" 3 "ThreePhoneAssociated" 2 "TwoPhoneAssociated" 1 "OnePhoneAssociated" 0 "NoPhoneAssociated" ;
VAL_ 1095 Pers2Phone_D_Stat 7 "SevenPhoneAssociated" 6 "SixPhoneAssociated" 5 "FivePhoneAssociated" 4 "FourPhoneAssociated" 3 "ThreePhoneAssociated" 2 "TwoPhoneAssociated" 1 "OnePhoneAssociated" 0 "NoPhoneAssociated" ;
VAL_ 1095 Pers1Phone_D_Stat 7 "SevenPhoneAssociated" 6 "SixPhoneAssociated" 5 "FivePhoneAssociated" 4 "FourPhoneAssociated" 3 "ThreePhoneAssociated" 2 "TwoPhoneAssociated" 1 "OnePhoneAssociated" 0 "NoPhoneAssociated" ;
VAL_ 1095 HeadLghtOn_D_Rq 7 "NotUsed2" 6 "NotUsed1" 5 "DrlBoth" 4 "DrlRight" 3 "DrlLeft" 2 "High" 1 "Low" 0 "Off" ;
VAL_ 1095 PepsKeyActv_D_Stat 15 "NotUsed11" 14 "NotUsed10" 13 "NotUsed9" 12 "NotUsed8" 11 "NotUsed7" 10 "NotUsed6" 9 "NotUsed5" 8 "Key4Active" 7 "NotUsed4" 6 "NotUsed3" 5 "NotUsed2" 4 "Key3Active" 3 "NotUsed1" 2 "Key2Active" 1 "Key1Active" 0 "NoKeyActive" ;
VAL_ 1095 VehLck_D_Dsply 3 "Faulty" 2 "Unlock" 1 "Lock" 0 "Off" ;
VAL_ 872 PwFlowPlgBatt_D_Dsply 3 "NotUsed" 2 "Flow_from_Plug_to_Batt" 1 "Flow_from_Batt_to_Plug" 0 "No_Flow" ;
VAL_ 872 PwFlowMtrDrv_D_Dsply 3 "NotUsed" 2 "Flow_from_Mtr_to_Axle" 1 "Flow_from_Axle_to_Mtr" 0 "No_FLow" ;
VAL_ 872 PwFlowEngMtr_D_Dsply 3 "NotUsed" 2 "Flow_from_Eng_to_Mtr" 1 "Flow_from_Mtr_to_Eng" 0 "No_Flow" ;
VAL_ 872 PwFlowEngFuel_D_Dsply 3 "NotUsed" 2 "Flow_from_Eng_to_Fuel" 1 "Flow_from_Fuel_to_Eng" 0 "No_Flow" ;
VAL_ 872 PwFlowEngDrv_D_Dsply 3 "NotUsed" 2 "Flow_from_Eng_to_Axle" 1 "Flow_from_Axle_to_Eng" 0 "No_Flow" ;
VAL_ 872 PwFlowBattMtr_D_Dsply 3 "NotUsed" 2 "Flow_from_Batt_to_Mtr" 1 "Flow_from_Mtr_to_Batt" 0 "No_Flow" ;
VAL_ 872 HybMdeStat_D_Dsply 7 "NotUsed2" 6 "EV_Charge" 5 "EV_Override" 4 "Forced_EV_Mode" 3 "Forced_Charge_Sustain_Mode" 2 "Auto_Charge_Sustain_Mode" 1 "Auto_Charge_Deplete_Mode" 0 "Null_State" ;
VAL_ 872 PlgActvArb_B_Dsply 1 "On" 0 "Off" ;
VAL_ 872 EcoMode_B_Stat 1 "On" 0 "Off" ;
VAL_ 872 MildHybStat_D_Dsply 7 "NotUsed" 6 "Recovery" 5 "Charge" 4 "Assist" 3 "Boost" 2 "SystemInhibited" 1 "SystemError" 0 "Off" ;
VAL_ 791 StopStrtVThres_D_RqMnu 3 "High" 2 "Medium" 1 "Low" 0 "NoSelection" ;
VAL_ 791 AwdDrvMde_D2_Rq 15 "Faulty" 14 "NotUsed_7" 13 "NotUsed_6" 12 "NotUsed_5" 11 "NotUsed_4" 10 "NotUsed_3" 9 "NotUsed_2" 8 "NotUsed_1" 7 "NotAvailable" 6 "TowHaul" 5 "RockCrawl" 4 "Baja" 3 "MudAndSand" 2 "Weather" 1 "Sport" 0 "Normal" ;
VAL_ 791 EngAirFilt_B_RqReset 1 "Yes" 0 "No" ;
VAL_ 791 BattElEmotive_Pc_Dsply 1023 "Faulty" 1022 "NoDataExists" ;
VAL_ 791 VehElEffTrip2Reset_B_Rq 1 "On" 0 "Off" ;
VAL_ 791 VehElEffTrip1Reset_B_Rq 1 "On" 0 "Off" ;
VAL_ 791 HybMdeOvrrd_D_Rq 3 "NotUsed" 2 "Invalid" 1 "Override" 0 "Null" ;
VAL_ 791 GpsElMdeSel_B_Rq 1 "On" 0 "Off" ;
VAL_ 791 LongTermReset_B_Rq 1 "On" 0 "Off" ;
VAL_ 791 EcoCcActv_B_Rq 1 "On" 0 "Off" ;
VAL_ 791 DrvEffLvl_No_Stat 63 "Fault" 62 "NoDataExists" ;
VAL_ 791 ChargeProfIDPref_Rq 3 "NotUsed" 2 "Value" 1 "ChargeNow" 0 "Inactive" ;
VAL_ 791 GrdAsstAllw_D_RqMnu 3 "NotUsed" 2 "On" 1 "Off" 0 "NoModeSelected" ;
VAL_ 791 PlgOvrrdStrt_D_Cmd 3 "NotUsed" 2 "Override_Plug_Status" 1 "Dont_Override_Plug_Status" 0 "Null_State" ;
VAL_ 791 EcoMde_D_RqMnu 3 "NotUsed" 2 "On" 1 "Off" 0 "Null" ;
VAL_ 791 EmotiveType_D_Dsply 3 "EmotiveDisplay_3" 2 "EmotiveDisplay_2" 1 "EmotiveDisplay_1" 0 "Null" ;
VAL_ 358 StopStrtStdby_D_Indic 6 "Telltale_On_Grey" 5 "Telltale_Struck_Out" 4 "Telltale_Flashing_Amber" 3 "Telltale_On_Amber" 2 "Telltale_Flashing_Green" 1 "Telltale_On_Green" 0 "Telltale_Off" 7 "NotUsed3" ;
VAL_ 358 StopStrtIODTxt_D_Rq 31 "Message31" 30 "Message30" 29 "Message29" 28 "Message28" 27 "Message27" 26 "Message26" 25 "Message25" 24 "Message24" 23 "Message23" 22 "Message22" 21 "Message21" 20 "Message20" 19 "Message19" 18 "Message18" 17 "Message17" 16 "Message16" 15 "Message15" 14 "Message14" 13 "Message13" 12 "Message12" 11 "Message11" 10 "Message10" 9 "Message9" 8 "Message8" 7 "Message7" 6 "Message6" 5 "Message5" 4 "Message4" 3 "Message3" 2 "Message2" 1 "Message1" 0 "NoMessage" ;
VAL_ 358 StopStrtDrvMde_D_Indic 3 "NotUsed" 2 "StartStop_IndirectDeselect" 1 "StopStart_Deselected" 0 "StopStart_Selected" ;
VAL_ 358 StopStrtMsgTxt_D_Rq 15 "Message_15" 14 "Message_14" 13 "Message_13" 12 "Message_12" 11 "Message_11" 10 "Message_10" 9 "Message_9" 8 "Message_8" 7 "Message_7" 6 "Message_6" 5 "Message_5" 4 "Message_4" 3 "Message_3" 2 "Message_2" 1 "Message_1" 0 "NoMessage" ;
VAL_ 358 OdoTripVerify_L_Actl 16777215 "Fault" ;
VAL_ 358 HiElPwInhbt_B_Stat 1 "Inhibit" 0 "No_Inibit" ;
VAL_ 358 AutoStopPtDelta_I_Est 255 "Fault" ;
VAL_ 945 AdasRelay_B_Stat2 1 "On" 0 "Off" ;
VAL_ 945 StrtrMtrCtlMsgTxt_D_Rq2 15 "Not_Used_12" 14 "Not_Used_11" 13 "Not_Used_10" 12 "Not_Used_9" 11 "Not_Used_8" 10 "Not_Used_7" 9 "Not_Used_6" 8 "Not_Used_5" 7 "Not_Used_4" 6 "Not_Used_3" 5 "Not_Used_2" 4 "Not_Used_1" 3 "Fault_UnableToStrtOrStop" 2 "PressTwiceToStart" 1 "Fault_GoToDealer" 0 "NoMessage" ;
VAL_ 945 PrkLckCtlMsgTxt_D2_Rq 7 "Message7" 6 "Message6" 5 "Message5" 4 "Message4" 3 "Message3" 2 "Message2" 1 "Message1" 0 "NoMessage" ;
VAL_ 945 KeyPadCodeDgt7_D_Dsply 15 "NotUsed_4" 14 "NotUsed_3" 13 "NotUsed_2" 12 "NotUsed_1" 11 "Button7_8and9_0" 10 "Button0" 9 "Button9_0or9" 8 "Button8" 7 "Button7_8or7" 6 "Button6" 5 "Button5_6or5" 4 "Button4" 3 "Button3_4or3" 2 "Button2" 1 "Button1_2or1" 0 "EndofString" ;
VAL_ 945 KeyPadCodeDgt6_D_Dsply 15 "NotUsed_4" 14 "NotUsed_3" 13 "NotUsed_2" 12 "NotUsed_1" 11 "Button7_8and9_0" 10 "Button0" 9 "Button9_0or9" 8 "Button8" 7 "Button7_8or7" 6 "Button6" 5 "Button5_6or5" 4 "Button4" 3 "Button3_4or3" 2 "Button2" 1 "Button1_2or1" 0 "EndofString" ;
VAL_ 945 KeyPadCodeDgt5_D_Dsply 15 "NotUsed_4" 14 "NotUsed_3" 13 "NotUsed_2" 12 "NotUsed_1" 11 "Button7_8and9_0" 10 "Button0" 9 "Button9_0or9" 8 "Button8" 7 "Button7_8or7" 6 "Button6" 5 "Button5_6or5" 4 "Button4" 3 "Button3_4or3" 2 "Button2" 1 "Button1_2or1" 0 "EndofString" ;
VAL_ 945 KeyPadCodeDgt4_D_Dsply 15 "NotUsed_4" 14 "NotUsed_3" 13 "NotUsed_2" 12 "NotUsed_1" 11 "Button7_8and9_0" 10 "Button0" 9 "Button9_0or9" 8 "Button8" 7 "Button7_8or7" 6 "Button6" 5 "Button5_6or5" 4 "Button4" 3 "Button3_4or3" 2 "Button2" 1 "Button1_2or1" 0 "EndofString" ;
VAL_ 945 KeyPadCodeDgt3_D_Dsply 15 "NotUsed_4" 14 "NotUsed_3" 13 "NotUsed_2" 12 "NotUsed_1" 11 "Button7_8and9_0" 10 "Button0" 9 "Button9_0or9" 8 "Button8" 7 "Button7_8or7" 6 "Button6" 5 "Button5_6or5" 4 "Button4" 3 "Button3_4or3" 2 "Button2" 1 "Button1_2or1" 0 "EndofString" ;
VAL_ 945 KeyPadCodeDgt2_D_Dsply 15 "NotUsed_4" 14 "NotUsed_3" 13 "NotUsed_2" 12 "NotUsed_1" 11 "Button7_8and9_0" 10 "Button0" 9 "Button9_0or9" 8 "Button8" 7 "Button7_8or7" 6 "Button6" 5 "Button5_6or5" 4 "Button4" 3 "Button3_4or3" 2 "Button2" 1 "Button1_2or1" 0 "EndofString" ;
VAL_ 945 KeyPadCodeDgt1_D_Dsply 15 "NotUsed_4" 14 "NotUsed_3" 13 "NotUsed_2" 12 "NotUsed_1" 11 "Button7_8and9_0" 10 "Button0" 9 "Button9_0or9" 8 "Button8" 7 "Button7_8or7" 6 "Button6" 5 "Button5_6or5" 4 "Button4" 3 "Button3_4or3" 2 "Button2" 1 "Button1_2or1" 0 "EndofString" ;
VAL_ 945 KeyOffMde_D_Actl 15 "NotUsed_11" 14 "NotUsed_10" 13 "NotUsed_9" 12 "NotUsed_8" 11 "NotUsed_7" 10 "NotUsed_6" 9 "NotUsed_5" 8 "NotUsed_4" 7 "NotUsed_3" 6 "NotUsed_2" 5 "NotUsed_1" 4 "CriticalBattery" 3 "Hibernate" 2 "Transport" 1 "Factory" 0 "Normal" ;
VAL_ 945 PrkLckCtlLatch_B_Rq 1 "On" 0 "Off" ;
VAL_ 740 EmgcyAsstActv_D_Stat 3 "ConfiguredOff" 2 "Active" 1 "Inactive" 0 "Null" ;
VAL_ 1055 EcoCochInstNeg_B_Dsply 1 "True" 0 "False" ;
VAL_ 360 GsmSrvcRqd_B_Rq 1 "Yes" 0 "No" ;
VAL_ 360 TrnTrcmPwmSig_D_Actl 15 "Faulty" 14 "NoDataExists" 13 "NotUsed5" 12 "NotUsed4" 11 "NotUsed3" 10 "NotUsed2" 9 "NotUsed1" 8 "Default_To_Park" 7 "Neutral_Tow" 6 "Car_Wash_Mode" 5 "Manual" 4 "Drive" 3 "Neutral" 2 "Reverse" 1 "Park" 0 "No_Gear" ;
VAL_ 360 TrnGearPwmFalt_B_Actl 1 "Yes" 0 "No" ;
VAL_ 360 GearButtnStuck_B_Actl 1 "Yes" 0 "No" ;
VAL_ 1056 VehVActlBrk_No_Corr 255 "Faulty" 254 "NoDataExists" ;
VAL_ 1056 AutoEpbButtnOn_B_Stat 1 "On" 0 "Off" ;
VAL_ 1056 AutoEpbMsgTxt_D_Rq 7 "Message7" 6 "Message6" 5 "Message5" 4 "Message4" 3 "Message3" 2 "Message2" 1 "Message1" 0 "NoMessage" ;
VAL_ 1056 AutoEpbDsply_D_Stat 3 "NotUsed" 2 "GreyedOut" 1 "Available" 0 "NotAvailable" ;
VAL_ 1056 SelDrvMdeHmi03_D_Rq 31 "Faulty" 30 "SelDrvMde31" 29 "SelDrvMde30" 28 "SelDrvMde29" 27 "SelDrvMde28" 26 "SelDrvMde27" 25 "SelDrvMde26" 24 "SelDrvMde25" 23 "SelDrvMde24" 22 "SelDrvMde23" 21 "SelDrvMde22" 20 "SelDrvMde21" 19 "SelDrvMde20" 18 "SelDrvMde19" 17 "SelDrvMde18" 16 "SelDrvMde17" 15 "SelDrvMde16" 14 "SelDrvMde15" 13 "SelDrvMde14" 12 "SelDrvMde13" 11 "SelDrvMde12" 10 "SelDrvMde11" 9 "SelDrvMde10" 8 "SelDrvMde09" 7 "SelDrvMde08" 6 "SelDrvMde07" 5 "SelDrvMde06" 4 "SelDrvMde05" 3 "SelDrvMde04" 2 "SelDrvMde03" 1 "SelDrvMde02" 0 "SelDrvMde01" ;
VAL_ 1056 SelDrvMdePos12_B_Avail 1 "Available" 0 "NotAvailable" ;
VAL_ 1056 SelDrvMdePos11_B_Avail 1 "Available" 0 "NotAvailable" ;
VAL_ 1056 SelDrvMdePos10_B_Avail 1 "Available" 0 "NotAvailable" ;
VAL_ 1056 SelDrvMdePos09_B_Avail 1 "Available" 0 "NotAvailable" ;
VAL_ 1056 SelDrvMdePos08_B_Avail 1 "Available" 0 "NotAvailable" ;
VAL_ 1056 SelDrvMdePos07_B_Avail 1 "Available" 0 "NotAvailable" ;
VAL_ 1056 SelDrvMdePos06_B_Avail 1 "Available" 0 "NotAvailable" ;
VAL_ 1056 SelDrvMdePos05_B_Avail 1 "Available" 0 "NotAvailable" ;
VAL_ 1056 SelDrvMdePos04_B_Avail 1 "Available" 0 "NotAvailable" ;
VAL_ 1056 SelDrvMdePos03_B_Avail 1 "Available" 0 "NotAvailable" ;
VAL_ 1056 SelDrvMdePos02_B_Avail 1 "Available" 0 "NotAvailable" ;
VAL_ 1056 SelDrvMdePos01_B_Avail 1 "Available" 0 "NotAvailable" ;
VAL_ 1056 SelDrvMdeMsgTxt2_D_Rq 15 "Message15" 14 "Message14" 13 "Message13" 12 "Message12" 11 "Message11" 10 "Message10" 9 "Message9" 8 "Message8" 7 "Message7" 6 "Message6" 5 "Message5" 4 "Message4" 3 "Message3" 2 "Message2" 1 "Message1" 0 "NoMessage" ;
VAL_ 1056 ActvDrvMde_D2_Stat 31 "Faulty" 30 "SelDrvMde31" 29 "SelDrvMde30" 28 "SelDrvMde29" 27 "SelDrvMde28" 26 "SelDrvMde27" 25 "SelDrvMde26" 24 "SelDrvMde25" 23 "SelDrvMde24" 22 "SelDrvMde23" 21 "SelDrvMde22" 20 "SelDrvMde21" 19 "SelDrvMde20" 18 "SelDrvMde19" 17 "SelDrvMde18" 16 "SelDrvMde17" 15 "SelDrvMde16" 14 "SelDrvMde15" 13 "SelDrvMde14" 12 "SelDrvMde13" 11 "SelDrvMde12" 10 "SelDrvMde11" 9 "SelDrvMde10" 8 "SelDrvMde09" 7 "SelDrvMde08" 6 "SelDrvMde07" 5 "SelDrvMde06" 4 "SelDrvMde05" 3 "SelDrvMde04" 2 "SelDrvMde03" 1 "SelDrvMde02" 0 "SelDrvMde01" ;
VAL_ 1056 SelDrvMde_D2_Rq 31 "Faulty" 30 "SelDrvMde31" 29 "SelDrvMde30" 28 "SelDrvMde29" 27 "SelDrvMde28" 26 "SelDrvMde27" 25 "SelDrvMde26" 24 "SelDrvMde25" 23 "SelDrvMde24" 22 "SelDrvMde23" 21 "SelDrvMde22" 20 "SelDrvMde21" 19 "SelDrvMde20" 18 "SelDrvMde19" 17 "SelDrvMde18" 16 "SelDrvMde17" 15 "SelDrvMde16" 14 "SelDrvMde15" 13 "SelDrvMde14" 12 "SelDrvMde13" 11 "SelDrvMde12" 10 "SelDrvMde11" 9 "SelDrvMde10" 8 "SelDrvMde09" 7 "SelDrvMde08" 6 "SelDrvMde07" 5 "SelDrvMde06" 4 "SelDrvMde05" 3 "SelDrvMde04" 2 "SelDrvMde03" 1 "SelDrvMde02" 0 "SelDrvMde01" ;
VAL_ 1056 AwdMde_D_RqBrk 7 "Faulty" 6 "NotUsed2" 5 "NoRequest" 4 "Neutral" 3 "FourByFourLow" 2 "FourByFourHigh" 1 "FourByFourAuto" 0 "FourByTwo" ;
VAL_ 1056 SelDrvMdePt_D_Rq 31 "Faulty" 30 "NotUsed15" 29 "NotUsed14" 28 "NotUsed13" 27 "NotUsed12" 26 "NotUsed11" 25 "NotUsed10" 24 "NotUsed9" 23 "NotUsed8" 22 "NotUsed7" 21 "CustomMode" 20 "TrackMode" 19 "OnePedalDrive" 18 "EvLaterChargerMode" 17 "EvNowMode" 16 "DragMode" 15 "HighSpeedDesertMode_Baja" 14 "SportAdaptiveMode" 13 "NotAvailable_13" 12 "NotAvailable_12" 11 "NotAvailable_11" 10 "NotAvailable_10" 9 "RockCrawlMode" 8 "MudRutsMode" 7 "SandMode" 6 "EconomyMode" 5 "GrassGravelSnow" 4 "NotAvailable_04" 3 "TowHaulMode" 2 "NotAvailable_02" 1 "SportMode" 0 "NormalMode" ;
VAL_ 1056 SelDrvMdeMsgTxt_D_Rq 15 "Message15" 14 "Message14" 13 "Message13" 12 "Message12" 11 "Message11" 10 "Message10" 9 "Message9" 8 "Message8" 7 "Message7" 6 "Message6" 5 "Message5" 4 "Message4" 3 "Message3" 2 "Message2" 1 "Message1" 0 "NoMessage" ;
VAL_ 1056 SelDrvMde_D_Stat 3 "NotUsed" 2 "DriveModeChangeRequest" 1 "DriveModeChangeSelection" 0 "NoDriveModeChangeRequest" ;
VAL_ 1060 FuelLvlWarn_D_ActlEng 7 "DteLevel5Lowest" 6 "DteLevel4" 5 "DteLevel3" 4 "DteLevel2NonMyKey" 3 "DteLevel1MyKey" 2 "VeryLow" 1 "Low" 0 "OK" ;
VAL_ 1060 RearDiffOilTeWarn_B_Rq 1 "On" 0 "Off" ;
VAL_ 1060 EngExhMdeQuiet_D_Stat 3 "Faulty" 2 "QuietExhaust" 1 "LoudExhaust" 0 "Null" ;
VAL_ 1060 RearDiffOil_Te_Actl 511 "Faulty" ;
VAL_ 1060 BpedDrvMsgTxt_B_Dsply 1 "On" 0 "Off" ;
VAL_ 1060 SelDrvMdePt_D_Stat 0 "NotAvailable" 1 "Available" 2 "TemporarilyNotAvailable" 3 "Faulty" ;
VAL_ 135 McGlblClkAdj_B_Rq 1 "Request" 0 "NoRequest" ;
VAL_ 134 DispGlblClkAdj_B_Rq 1 "Request" 0 "NoRequest" ;
VAL_ 939 DrTgateMde_D_Stat 3 "NotUsed_1" 2 "Up" 1 "Down" 0 "NotAvailable" ;
VAL_ 939 ResPrkAidSnsRlSide_D_Stat 15 "Zone_15" 14 "Zone_14" 13 "Zone_13" 12 "Zone_12" 11 "Zone_11" 10 "Zone_10" 9 "Zone_9" 8 "Zone_8" 7 "Zone_7" 6 "Zone_6" 5 "Zone_5" 4 "Zone_4" 3 "Zone_3" 2 "Zone_2" 1 "Zone_1" 0 "Off" ;
VAL_ 939 SidePrkSnsR4_D_Stat 15 "NotUsed" 14 "NotFullyScannedYet" 13 "NoObjectInSector" 12 "Zone12" 11 "Zone11" 10 "Zone10" 9 "Zone9" 8 "Zone8" 7 "Zone7" 6 "Zone6" 5 "Zone5" 4 "Zone4" 3 "Zone3" 2 "Zone2" 1 "Zone1" 0 "Off" ;
VAL_ 939 SidePrkSnsR3_D_Stat 15 "NotUsed" 14 "NotFullyScannedYet" 13 "NoObjectInSector" 12 "Zone12" 11 "Zone11" 10 "Zone10" 9 "Zone9" 8 "Zone8" 7 "Zone7" 6 "Zone6" 5 "Zone5" 4 "Zone4" 3 "Zone3" 2 "Zone2" 1 "Zone1" 0 "Off" ;
VAL_ 939 SidePrkSnsL4_D_Stat 15 "NotUsed" 14 "NotFullyScannedYet" 13 "NoObjectInSector" 12 "Zone12" 11 "Zone11" 10 "Zone10" 9 "Zone9" 8 "Zone8" 7 "Zone7" 6 "Zone6" 5 "Zone5" 4 "Zone4" 3 "Zone3" 2 "Zone2" 1 "Zone1" 0 "Off" ;
VAL_ 939 SidePrkSnsL3_D_Stat 15 "NotUsed" 14 "NotFullyScannedYet" 13 "NoObjectInSector" 12 "Zone12" 11 "Zone11" 10 "Zone10" 9 "Zone9" 8 "Zone8" 7 "Zone7" 6 "Zone6" 5 "Zone5" 4 "Zone4" 3 "Zone3" 2 "Zone2" 1 "Zone1" 0 "Off" ;
VAL_ 939 PrkAidChime_D_Stat 3 "Fault" 2 "No_Data_Exists" 1 "On" 0 "Off" ;
VAL_ 939 PrkAidSnsRlCntr_D_Stat 15 "Zone_15" 14 "Zone_14" 13 "Zone_13" 12 "Zone_12" 11 "Zone_11" 10 "Zone_10" 9 "Zone_9" 8 "Zone_8" 7 "Zone_7" 6 "Zone_6" 5 "Zone_5" 4 "Zone_4" 3 "Zone_3" 2 "Zone_2" 1 "Zone_1" 0 "Off" ;
VAL_ 939 PrkAidSnsRrCrnr_D_Stat 15 "Zone_15" 14 "Zone_14" 13 "Zone_13" 12 "Zone_12" 11 "Zone_11" 10 "Zone_10" 9 "Zone_9" 8 "Zone_8" 7 "Zone_7" 6 "Zone_6" 5 "Zone_5" 4 "Zone_4" 3 "Zone_3" 2 "Zone_2" 1 "Zone_1" 0 "Off" ;
VAL_ 939 PrkAidSnsRrCntr_D_Stat 15 "Zone_15" 14 "Zone_14" 13 "Zone_13" 12 "Zone_12" 11 "Zone_11" 10 "Zone_10" 9 "Zone_9" 8 "Zone_8" 7 "Zone_7" 6 "Zone_6" 5 "Zone_5" 4 "Zone_4" 3 "Zone_3" 2 "Zone_2" 1 "Zone_1" 0 "Off" ;
VAL_ 939 PrkAidSnsRlCrnr_D_Stat 15 "Zone_15" 14 "Zone_14" 13 "Zone_13" 12 "Zone_12" 11 "Zone_11" 10 "Zone_10" 9 "Zone_9" 8 "Zone_8" 7 "Zone_7" 6 "Zone_6" 5 "Zone_5" 4 "Zone_4" 3 "Zone_3" 2 "Zone_2" 1 "Zone_1" 0 "Off" ;
VAL_ 939 PrkAidRear_D_Stat 3 "Faulted" 2 "Unused" 1 "Enabled" 0 "Disabled" ;
VAL_ 939 PrkAidFront_D_Stat 3 "Faulted" 2 "Unused" 1 "Enabled" 0 "Disabled" ;
VAL_ 939 PrkAid_D_Falt 7 "NotUsed2" 6 "NotUsed1" 5 "Failure_Front_PSM_Sensors" 4 "No_Data_Exists" 3 "Failure_Rear_Sensors" 2 "Speaker_Fault" 1 "ECU_Fault" 0 "No_Fault" ;
VAL_ 939 ResPrkAidSnsRrSide_D_Stat 15 "Zone_15" 14 "Zone_14" 13 "Zone_13" 12 "Zone_12" 11 "Zone_11" 10 "Zone_10" 9 "Zone_9" 8 "Zone_8" 7 "Zone_7" 6 "Zone_6" 5 "Zone_5" 4 "Zone_4" 3 "Zone_3" 2 "Zone_2" 1 "Zone_1" 0 "Off" ;
VAL_ 939 PrkAidLamp_D_Rq 3 "Not_Used" 2 "Flash" 1 "On" 0 "Off" ;
VAL_ 939 ApaLongCtrlEnbl_D_Rq 1 "Enable" 0 "Disable" ;
VAL_ 939 ApaBrk_D_Rq 3 "NotUsed" 2 "LowDecel" 1 "HighDecel" 0 "NoRequest" ;
VAL_ 938 SidePrkSnsR2_D_Stat 15 "NotUsed" 14 "NotFullyScannedYet" 13 "NoObjectInSector" 12 "Zone12" 11 "Zone11" 10 "Zone10" 9 "Zone9" 8 "Zone8" 7 "Zone7" 6 "Zone6" 5 "Zone5" 4 "Zone4" 3 "Zone3" 2 "Zone2" 1 "Zone1" 0 "Off" ;
VAL_ 938 SidePrkSnsR1_D_Stat 15 "NotUsed" 14 "NotFullyScannedYet" 13 "NoObjectInSector" 12 "Zone12" 11 "Zone11" 10 "Zone10" 9 "Zone9" 8 "Zone8" 7 "Zone7" 6 "Zone6" 5 "Zone5" 4 "Zone4" 3 "Zone3" 2 "Zone2" 1 "Zone1" 0 "Off" ;
VAL_ 938 SidePrkSnsL2_D_Stat 15 "NotUsed" 14 "NotFullyScannedYet" 13 "NoObjectInSector" 12 "Zone12" 11 "Zone11" 10 "Zone10" 9 "Zone9" 8 "Zone8" 7 "Zone7" 6 "Zone6" 5 "Zone5" 4 "Zone4" 3 "Zone3" 2 "Zone2" 1 "Zone1" 0 "Off" ;
VAL_ 938 SidePrkSnsL1_D_Stat 15 "NotUsed" 14 "NotFullyScannedYet" 13 "NoObjectInSector" 12 "Zone12" 11 "Zone11" 10 "Zone10" 9 "Zone9" 8 "Zone8" 7 "Zone7" 6 "Zone6" 5 "Zone5" 4 "Zone4" 3 "Zone3" 2 "Zone2" 1 "Zone1" 0 "Off" ;
VAL_ 938 ApaMde_D_Stat 7 "NotUsed" 6 "RePA" 5 "ParkIn" 4 "POA" 3 "PPA" 2 "SAPP" 1 "Off" 0 "Null" ;
VAL_ 938 ApaActvSd_D_Actl 3 "Dirver_Side" 2 "Passenger_Side" 1 "No_Side" 0 "Null" ;
VAL_ 938 PrkAidSwtch_B_Stat 1 "Pressed" 0 "Not_Pressed" ;
VAL_ 938 PrkAidMsgTxt_D_Rq 15 "All_Sns_Blk" 14 "R_Sns_ON_F_Sns_Blk" 13 "R_Sns_Blk_F_Sns_ON" 12 "R_Sns_Inactive_Trlr_atch" 11 "Not_Avail_Trlr_attchd" 10 "Fail_Mode_no_Chime" 9 "Fail_Mode_with_Chime" 8 "R_Sns_Trlr_F_Sns_Blk" 7 "NotUsed3" 6 "Park_Sys_Alternate_Mode" 5 "R_Snsrs_On_F_Snsrs_On" 4 "NotUsed2" 3 "Reset_Message_Warn" 2 "R_Snsrs_Off_F_Snsrs_On" 1 "R_Snsrs_On_F_Snsrs_Off" 0 "All_Park_Sensors_Off" ;
VAL_ 938 ApaMde_D_Avail 15 "NotUsed7" 14 "NotUsed6" 13 "NotUsed5" 12 "NotUsed4" 11 "NotUsed3" 10 "NotUsed2" 9 "NotUsed1" 8 "PPA_POA" 7 "SAPP_POA" 6 "POA" 5 "PPA" 4 "SAPP" 3 "SAPP_PPA_POA" 2 "SAPP_PPA" 1 "None" 0 "Null" ;
VAL_ 938 PrkAidSnsFrCrnr_D_Stat 15 "Zone_15" 14 "Zone_14" 13 "Zone_13" 12 "Zone_12" 11 "Zone_11" 10 "Zone_10" 9 "Zone_9" 8 "Zone_8" 7 "Zone_7" 6 "Zone_6" 5 "Zone_5" 4 "Zone_4" 3 "Zone_3" 2 "Zone_2" 1 "Zone_1" 0 "Off" ;
VAL_ 938 PrkAidSnsFrCntr_D_Stat 15 "Zone_15" 14 "Zone_14" 13 "Zone_13" 12 "Zone_12" 11 "Zone_11" 10 "Zone_10" 9 "Zone_9" 8 "Zone_8" 7 "Zone_7" 6 "Zone_6" 5 "Zone_5" 4 "Zone_4" 3 "Zone_3" 2 "Zone_2" 1 "Zone_1" 0 "Off" ;
VAL_ 938 PrkAidSnsFlCrnr_D_Stat 15 "Zone_15" 14 "Zone_14" 13 "Zone_13" 12 "Zone_12" 11 "Zone_11" 10 "Zone_10" 9 "Zone_9" 8 "Zone_8" 7 "Zone_7" 6 "Zone_6" 5 "Zone_5" 4 "Zone_4" 3 "Zone_3" 2 "Zone_2" 1 "Zone_1" 0 "Off" ;
VAL_ 938 PrkAidSnsFlCntr_D_Stat 15 "Zone_15" 14 "Zone_14" 13 "Zone_13" 12 "Zone_12" 11 "Zone_11" 10 "Zone_10" 9 "Zone_9" 8 "Zone_8" 7 "Zone_7" 6 "Zone_6" 5 "Zone_5" 4 "Zone_4" 3 "Zone_3" 2 "Zone_2" 1 "Zone_1" 0 "Off" ;
VAL_ 938 RpaChime_D_Rq 15 "Zone15_Chime" 14 "Zone14_Chime" 13 "Zone13_Chime" 12 "Zone12_Chime" 11 "Zone11_Chime" 10 "Zone10_Chime" 9 "Zone9_Chime" 8 "Zone8_Chime" 7 "Zone7_Chime" 6 "Zone6_Chime" 5 "Zone5_Chime" 4 "Zone4_Chime" 3 "Zone3_Chime" 2 "Zone2_Chime" 1 "Zone1_Chime" 0 "No_Chime" ;
VAL_ 938 FpaChime_D_Rq 15 "Zone15_Chime" 14 "Zone14_Chime" 13 "Zone13_Chime" 12 "Zone12_Chime" 11 "Zone11_Chime" 10 "Zone10_Chime" 9 "Zone9_Chime" 8 "Zone8_Chime" 7 "Zone7_Chime" 6 "Zone6_Chime" 5 "Zone5_Chime" 4 "Zone4_Chime" 3 "Zone3_Chime" 2 "Zone2_Chime" 1 "Zone1_Chime" 0 "No_Chime" ;
VAL_ 938 PrkAidAudioMute_B_Rq 1 "Enable" 0 "Disable" ;
VAL_ 938 PrkBrkEl_B_RqFap 1 "Yes" 0 "No" ;
VAL_ 952 Tire_Press_IRR_Data 65535 "Not_Supported" 65534 "Invalid" 65533 "Unknown" ;
VAL_ 952 Tire_Press_ILR_Data 65535 "Not_Supported" 65534 "Invalid" 65533 "Unknown" ;
VAL_ 845 SeatMasgPsngr_D_Stat 15 "NotUsed_10" 14 "NotUsed_9" 13 "NotUsed_8" 12 "NotUsed_7" 11 "NotUsed_6" 10 "Pattern10" 9 "Pattern9" 8 "Pattern8" 7 "Pattern7" 6 "Pattern6" 5 "Pattern5" 4 "Pattern4" 3 "Pattern3" 2 "Pattern2" 1 "Pattern1" 0 "Null" ;
VAL_ 845 SeatIntnsPsngr_D_Stat 7 "NotUsed_3" 6 "NotUsed_2" 5 "NotUsed_1" 4 "High" 3 "Medium" 2 "Low" 1 "Off" 0 "Null" ;
VAL_ 845 StmsLmbrPsgr_D_Stat 3 "High" 2 "Low" 1 "Off" 0 "Null" ;
VAL_ 845 StmsCshnPsgr_D_Stat 3 "High" 2 "Low" 1 "Off" 0 "Null" ;
VAL_ 845 SeatSwtchPsgr_B_Stat 1 "On" 0 "Off" ;
VAL_ 845 SeatPPsgr_B_Stat 1 "Updating" 0 "NotUpdating" ;
VAL_ 845 SeatFnPsgr_D_Stat 7 "CushionMassage" 6 "LumbarMassage" 5 "UpperBolster" 4 "LowerBolster" 3 "UpperLumbar" 2 "MiddleLumbar" 1 "LowerLumbar" 0 "Null" ;
VAL_ 845 PsgrMemFeedback_Rsp 8 "Recall_4" 7 "Recall_3" 6 "Recall_2" 5 "Recall_1" 4 "Store_4" 3 "Store_3" 2 "Store_2" 1 "Store_1" 0 "Inactive" ;
VAL_ 1137 RngPerChrgLbl_L_Dsply 4095 "Faulty" 4094 "NoDataExists" ;
VAL_ 1137 RngPerChrgAvg_L_Dsply 4095 "Faulty" 4094 "NoDataExists" ;
VAL_ 1137 RngImpctTot_Pc_Dsply 1023 "Faulty" ;
VAL_ 1137 RngImpctExt_Pc_Dsply 1023 "Faulty" ;
VAL_ 1137 RngImpctDrv_Pc_Dsply 1023 "Faulty" ;
VAL_ 1137 RngImpctClim_Pc_Dsply 1023 "Faulty" ;
VAL_ 844 SeatMasgDrv_D_Stat 15 "NotUsed_10" 14 "NotUsed_9" 13 "NotUsed_8" 12 "NotUsed_7" 11 "NotUsed_6" 10 "Pattern10" 9 "Pattern9" 8 "Pattern8" 7 "Pattern7" 6 "Pattern6" 5 "Pattern5" 4 "Pattern4" 3 "Pattern3" 2 "Pattern2" 1 "Pattern1" 0 "Null" ;
VAL_ 844 SeatIntnsDrv_D_Stat 7 "NotUsed_3" 6 "NotUsed_2" 5 "NotUsed_1" 4 "High" 3 "Medium" 2 "Low" 1 "Off" 0 "Null" ;
VAL_ 844 StmsLmbrDrv_D_Stat 3 "High" 2 "Low" 1 "Off" 0 "Null" ;
VAL_ 844 StmsCshnDrv_D_Stat 3 "High" 2 "Low" 1 "Off" 0 "Null" ;
VAL_ 844 SeatSwtchDrv_B_Stat 1 "On" 0 "Off" ;
VAL_ 844 SeatFnDrv_D_Stat 7 "CushionMassage" 6 "LumbarMassage" 5 "UpperBolster" 4 "LowerBolster" 3 "UpperLumbar" 2 "MiddleLumbar" 1 "LowerLumbar" 0 "Null" ;
VAL_ 844 SeatPDrv_B_Stat 1 "Updating" 0 "NotUpdating" ;
VAL_ 843 SeatBlUpPsgr_Pc_Actl 127 "Null" ;
VAL_ 843 SeatBlLoPsgr_Pc_Actl 127 "Null" ;
VAL_ 842 SeatBlUpDrv_Pc_Actl 127 "Null" ;
VAL_ 842 SeatBlLoDrv_Pc_Actl 127 "Null" ;
VAL_ 846 SeatPosHomeRear_D_Rq 15 "NotUsed_9" 14 "NotUsed_8" 13 "NotUsed_7" 12 "NotUsed_6" 11 "NotUsed_5" 10 "NotUsed_4" 9 "NotUsed_3" 8 "NotUsed_2" 7 "NotUsed_1" 6 "BothThirdRowSeatReturn" 5 "RightThirdRowSeatReturn" 4 "LeftThirdRowSeatReturn" 3 "BothSecondRowSeatReturn" 2 "RightSecondRowSeatReturn" 1 "LeftSecondRowSeatReturn" 0 "NoRequest" ;
VAL_ 846 SeatRelxPosDactv_B_Rq 1 "True" 0 "False" ;
VAL_ 846 SeatRelxPosActv_B_Rq 1 "True" 0 "False" ;
VAL_ 846 SeatRelxPosSet_D_Rq 3 "NotUsed" 2 "Active" 1 "Store" 0 "Inactive" ;
VAL_ 846 SeatMasgDrv_D_Rq 15 "NotUsed_10" 14 "NotUsed_9" 13 "NotUsed_8" 12 "NotUsed_7" 11 "NotUsed_6" 10 "Pattern10" 9 "Pattern9" 8 "Pattern8" 7 "Pattern7" 6 "Pattern6" 5 "Pattern5" 4 "Pattern4" 3 "Pattern3" 2 "Pattern2" 1 "Pattern1" 0 "Null" ;
VAL_ 846 SeatMasgPsngr_D_Rq 15 "NotUsed_10" 14 "NotUsed_9" 13 "NotUsed_8" 12 "NotUsed_7" 11 "NotUsed_6" 10 "Pattern10" 9 "Pattern9" 8 "Pattern8" 7 "Pattern7" 6 "Pattern6" 5 "Pattern5" 4 "Pattern4" 3 "Pattern3" 2 "Pattern2" 1 "Pattern1" 0 "Null" ;
VAL_ 846 SeatLmbr_D_Rq 15 "NotUsed_7" 14 "NotUsed_6" 13 "NotUsed_5" 12 "NotUsed_4" 11 "NotUsed_3" 10 "NotUsed_2" 9 "NotUsed_1" 8 "PassengerDown" 7 "PassengerUp" 6 "PassengerAft" 5 "PassengerFore" 4 "DriverDown" 3 "DriverUp" 2 "DriverAft" 1 "DriverFore" 0 "Null" ;
VAL_ 846 SeatFnChngPsgr2_D_Rq 15 "Faulty" 14 "NotUsed9" 13 "NotUsed8" 12 "NotUsed7" 11 "NotUsed6" 10 "High_2" 9 "Med_2" 8 "Low_2" 7 "Off_2" 6 "High" 5 "Low" 4 "Off" 3 "Decrease" 2 "Increase" 1 "NotUsed1" 0 "Inactive" ;
VAL_ 846 SeatFnChngDrv2_D_Rq 15 "Faulty" 14 "NotUsed9" 13 "NotUsed8" 12 "NotUsed7" 11 "NotUsed6" 10 "High_2" 9 "Med_2" 8 "Low_2" 7 "Off_2" 6 "High" 5 "Low" 4 "Off" 3 "Decrease" 2 "Increase" 1 "NotUsed1" 0 "Inactive" ;
VAL_ 846 SeatFnPsgr_D_Rq 7 "CushionMassage" 6 "LumbarMassage" 5 "UpperBolster" 4 "LowerBolster" 3 "UpperLumbar" 2 "MiddleLumbar" 1 "LowerLumbar" 0 "Inactive" ;
VAL_ 846 SeatFnDrv_D_Rq 7 "CushionMassage" 6 "LumbarMassage" 5 "UpperBolster" 4 "LowerBolster" 3 "UpperLumbar" 2 "MiddleLumbar" 1 "LowerLumbar" 0 "Inactive" ;
VAL_ 846 SeatFnDfaltPsgr_B_Rq 1 "Active" 0 "Inactive" ;
VAL_ 846 SeatFnDfaltDrv_B_Rq 1 "Active" 0 "Inactive" ;
VAL_ 846 SeatFnChngPsgr_D_Rq 2 "Decrease" 1 "Increase" 0 "Inactive" ;
VAL_ 846 SeatFnChngDrv_D_Rq 2 "Decrease" 1 "Increase" 0 "Inactive" ;
VAL_ 846 PsgrMemory_Rq 8 "Recall_4" 7 "Recall_3" 6 "Recall_2" 5 "Recall_1" 4 "Store_4" 3 "Store_3" 2 "Store_2" 1 "Store_1" 0 "Inactive" ;
